VERSION "FL_IC_CANFD"

NS_ :

BS_:

BU_: AVAS BBCM CMSM DVR EAMP EPC FLZCU ICC PCL PLG SBOX SCU

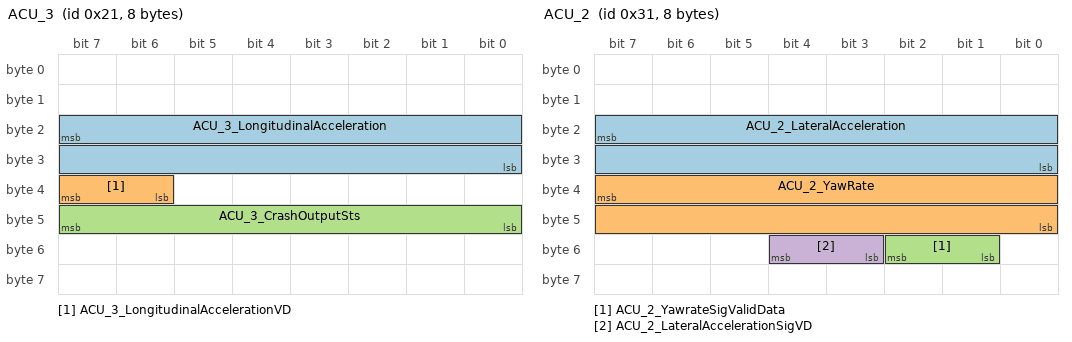
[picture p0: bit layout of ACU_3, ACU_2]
BO_ 33 ACU_3: 8 FLZCU
 SG_ ACU_3_LongitudinalAcceleration : 23|16@0+ (0.001,-2) [-2|2] "g"  ICC
 SG_ ACU_3_LongitudinalAccelerationVD : 39|2@0+ (1,0) [0|3] ""  ICC
 SG_ ACU_3_CrashOutputSts : 47|8@0+ (1,0) [0|255] ""  ICC

BO_ 49 ACU_2: 8 FLZCU
 SG_ ACU_2_LateralAcceleration : 23|16@0+ (0.001,-2) [-2|2] "g"  ICC
 SG_ ACU_2_YawRate : 39|16@0+ (0.01,-180) [-180|180] "deg/sec"  ICC
 SG_ ACU_2_YawrateSigValidData : 50|2@0+ (1,0) [0|3] ""  ICC
 SG_ ACU_2_LateralAccelerationSigVD : 52|2@0+ (1,0) [0|3] ""  ICC

BO_ 258 BMS_1: 48 FLZCU
 SG_ BMS_1_CRC1 : 7|8@0+ (1,0) [0|255] ""  ICC
 SG_ BMS_1_RollgCntr1 : 11|4@0+ (1,0) [0|14] ""  ICC
 SG_ BMS_1_Resd1 : 15|4@0+ (1,0) [0|15] ""  ICC
 SG_ BMS_PackVoltage : 23|16@0+ (0.1,0) [0|1000] "volt(V)"  ICC
 SG_ BMS_PackCurrent : 39|16@0+ (0.1,-2047) [-2047|2047] "ampere(A)"  ICC
 SG_ BMS_HvBattSts : 51|4@0+ (1,0) [0|15] ""  ICC
 SG_ BMS_SysSelfCheck : 53|2@0+ (1,0) [0|3] ""  ICC
 SG_ BMS_HVBattThermRunaway : 55|2@0+ (1,0) [0|3] ""  ICC
 SG_ BMS_1_CRC2 : 71|8@0+ (1,0) [0|255] ""  ICC
 SG_ BMS_1_RollgCntr2 : 75|4@0+ (1,0) [0|14] ""  ICC
 SG_ BMS_1_Resd2 : 79|4@0+ (1,0) [0|15] ""  ICC
 SG_ BMS_ChargeVoltageReq : 87|14@0+ (0.1,0) [0|1024] "volt(V)"  ICC
 SG_ BMS_ChgCurrReq : 103|14@0+ (0.1,-1024) [-1024|0] "ampere(A)"  ICC
 SG_ BMS_InfraDcUActDc : 119|14@0+ (0.1,0) [0|1024] "volt(V)"  ICC
 SG_ BMS_1_CRC3 : 135|8@0+ (1,0) [0|255] ""  ICC
 SG_ BMS_1_RollgCntr3 : 139|4@0+ (1,0) [0|14] ""  ICC
 SG_ BMS_1_Resd3 : 143|4@0+ (1,0) [0|15] ""  ICC
 SG_ BMS_InfraDcIActDc : 151|14@0+ (0.1,-1024) [-1024|0] "ampere(A)"  ICC
 SG_ BMS_HvBattDynChrgnILim : 167|14@0+ (0.1,-1024) [-1024|0] "ampere(A)"  ICC
 SG_ BMS_HvBattUChrgnLim : 183|14@0+ (0.1,0) [0|1024] "volt(V)"  ICC
 SG_ BMS_1_CRC4 : 199|8@0+ (1,0) [0|255] ""  ICC
 SG_ BMS_1_RollgCntr4 : 203|4@0+ (1,0) [0|14] ""  ICC
 SG_ BMS_1_Resd4 : 207|4@0+ (1,0) [0|15] ""  ICC
 SG_ BMS_ChrgDcIAvl : 215|14@0+ (0.1,-1024) [-1024|0] "ampere(A)"  ICC
 SG_ BMS_DChrgAPlusSt : 217|1@0+ (1,0) [0|1] ""  ICC
 SG_ BMS_Insulation_R : 231|16@0+ (1,0) [0|60000] "kiloohm(kΩ)"  ICC
 SG_ BMS_ChrgDcCnctrDetd : 241|2@0+ (1,0) [0|3] ""  ICC
 SG_ BMS_DCChgMode : 244|3@0+ (1,0) [0|7] ""  ICC
 SG_ BMS_ChrgDcChrgnFltStopReas : 247|3@0+ (1,0) [0|7] ""  ICC
 SG_ BMS_1_CRC5 : 263|8@0+ (1,0) [0|255] ""  ICC
 SG_ BMS_1_RollgCntr5 : 267|4@0+ (1,0) [0|14] ""  ICC
 SG_ BMS_1_Resd5 : 271|4@0+ (1,0) [0|15] ""  ICC
 SG_ BMS_ChgRemTime : 279|11@0+ (1,0) [0|1440] "min"  ICC
 SG_ BMS_ChargeRequest_Mode : 284|4@0+ (1,0) [0|15] ""  ICC
 SG_ BMS_1_StateOfChargeDis : 295|8@0+ (1,0) [0|100] "%"  ICC
 SG_ BMS_StateOfEnergy : 311|16@0+ (0.1,0) [0|999.9] "kWh"  ICC
 SG_ BMS_1_CRC6 : 327|8@0+ (1,0) [0|255] ""  ICC
 SG_ BMS_1_RollgCntr6 : 331|4@0+ (1,0) [0|14] ""  ICC
 SG_ BMS_1_Resd6 : 335|4@0+ (1,0) [0|15] ""  ICC
 SG_ BMS_StateOfHealth : 342|7@0+ (1,0) [0|100] ""  ICC
 SG_ BMS_BlanceState : 343|1@0+ (1,0) [0|1] ""  ICC
 SG_ BMS_IsolationFault : 345|2@0+ (1,0) [0|3] ""  ICC
 SG_ BMS_HVILFault_DC : 346|1@0+ (1,0) [0|1] ""  ICC
 SG_ BMS_HVILFault_FMCU : 347|1@0+ (1,0) [0|1] ""  ICC
 SG_ BMS_HVILFault_RMCU : 348|1@0+ (1,0) [0|1] ""  ICC
 SG_ BMS_SOCDis : 359|14@0+ (0.01,0) [0|100] "%"  ICC
 SG_ BMS_InfraDcIActDcMin : 375|14@0+ (0.1,-1024) [-1024|0] "ampere(A)"  ICC

BO_ 259 EMS_6: 16 FLZCU
 SG_ EMS_EngineSpeed_Actual : 39|16@0+ (0.25,0) [0|16383] "rpm"  ICC

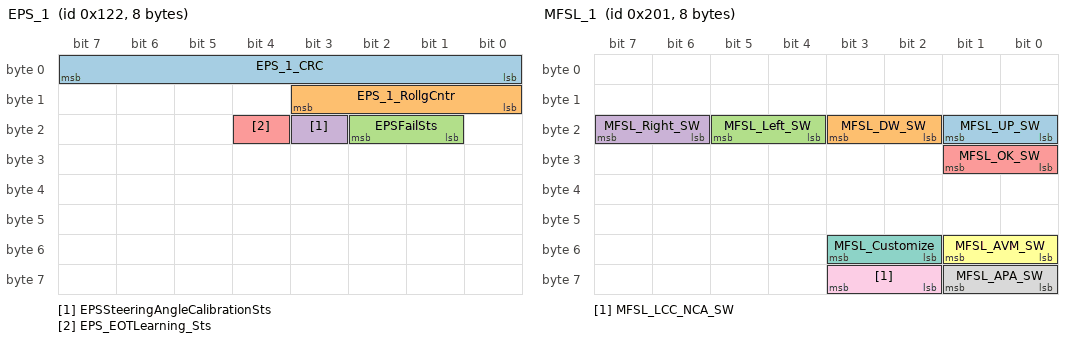
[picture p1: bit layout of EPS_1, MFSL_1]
BO_ 290 EPS_1: 8 FLZCU
 SG_ EPS_1_CRC : 7|8@0+ (1,0) [0|255] ""  ICC
 SG_ EPS_1_RollgCntr : 11|4@0+ (1,0) [0|14] ""  ICC
 SG_ EPSFailSts : 18|2@0+ (1,0) [0|3] ""  ICC
 SG_ EPSSteeringAngleCalibrationSts : 19|1@0+ (1,0) [0|1] ""  ICC
 SG_ EPS_EOTLearning_Sts : 20|1@0+ (1,0) [0|1] ""  ICC

BO_ 513 MFSL_1: 8 FLZCU
 SG_ MFSL_UP_SW : 17|2@0+ (1,0) [0|3] ""  ICC
 SG_ MFSL_DW_SW : 19|2@0+ (1,0) [0|3] ""  ICC
 SG_ MFSL_Left_SW : 21|2@0+ (1,0) [0|3] ""  ICC
 SG_ MFSL_Right_SW : 23|2@0+ (1,0) [0|3] ""  ICC
 SG_ MFSL_OK_SW : 25|2@0+ (1,0) [0|3] ""  ICC
 SG_ MFSL_AVM_SW : 49|2@0+ (1,0) [0|3] ""  ICC
 SG_ MFSL_Customize : 51|2@0+ (1,0) [0|3] ""  ICC
 SG_ MFSL_APA_SW : 57|2@0+ (1,0) [0|3] ""  ICC
 SG_ MFSL_LCC_NCA_SW : 59|2@0+ (1,0) [0|3] ""  ICC

BO_ 514 ADS_HW_202h: 16 FLZCU
 SG_ New_Signal_202_2 : 111|24@0+ (1,0) [0|0] ""  ICC
 SG_ New_Signal_202_1 : 71|16@0+ (1,0) [0|0] ""  ICC
 SG_ ADS_CRC1_202h : 7|8@0+ (1,0) [0|255] ""  ICC
 SG_ ADS_RollgCntr1_202h : 11|4@0+ (1,0) [0|14] ""  ICC
 SG_ ADS_Resd1_202h : 15|4@0+ (1,0) [0|15] ""  ICC
 SG_ ADS_NicaReminderAcoustic_202h : 17|3@0+ (1,0) [0|7] ""  ICC
 SG_ ADS_NicaReminderLEDVisual_202h : 20|3@0+ (1,0) [0|7] ""  ICC
 SG_ ADS_AdsFault_202h : 23|3@0+ (1,0) [0|7] ""  ICC
 SG_ ADS_TakeoverID_202h : 30|16@0+ (1,0) [0|65535] ""  ICC
 SG_ ADS_TakeoverType_202h : 43|4@0+ (1,0) [0|15] ""  ICC
 SG_ ADS_TakeoverLevel_202h : 46|3@0+ (1,0) [0|7] ""  ICC
 SG_ ADS_TORIDCorrespErrorID_202h : 55|16@0+ (1,0) [0|65535] ""  ICC
 SG_ ADS_TakeoverExtended16bit_202h : 87|16@0+ (1,0) [0|65535] ""  ICC
 SG_ ADS_TakeoverExtended8bit_202h : 103|8@0+ (1,0) [0|255] ""  ICC

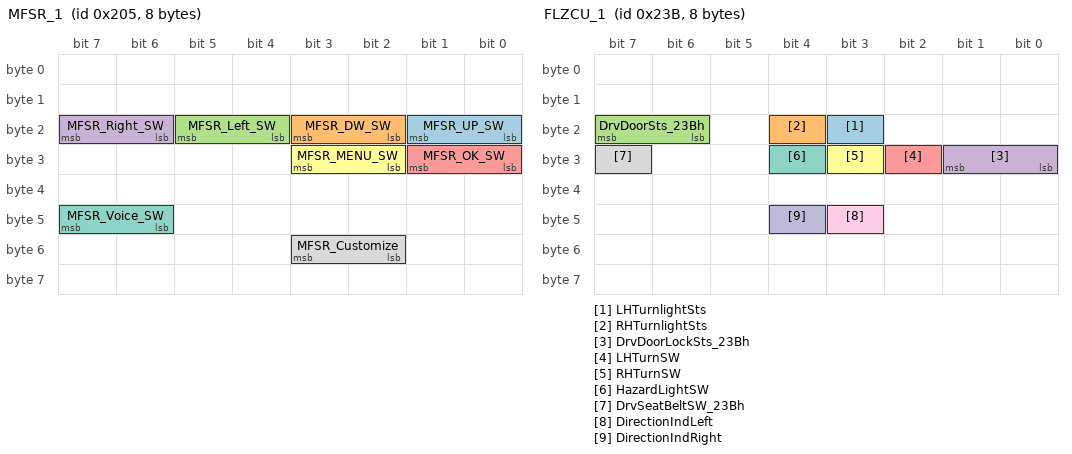
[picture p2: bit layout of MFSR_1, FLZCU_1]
BO_ 517 MFSR_1: 8 FLZCU
 SG_ MFSR_UP_SW : 17|2@0+ (1,0) [0|3] ""  ICC
 SG_ MFSR_DW_SW : 19|2@0+ (1,0) [0|3] ""  ICC
 SG_ MFSR_Left_SW : 21|2@0+ (1,0) [0|3] ""  ICC
 SG_ MFSR_Right_SW : 23|2@0+ (1,0) [0|3] ""  ICC
 SG_ MFSR_OK_SW : 25|2@0+ (1,0) [0|3] ""  ICC
 SG_ MFSR_MENU_SW : 27|2@0+ (1,0) [0|3] ""  ICC
 SG_ MFSR_Voice_SW : 47|2@0+ (1,0) [0|3] ""  ICC
 SG_ MFSR_Customize : 51|2@0+ (1,0) [0|3] ""  ICC

BO_ 524 ADS_6: 8 FLZCU
 SG_ ADS_6_Customize_buttonsFB : 19|3@0+ (1,0) [0|7] ""  ICC

BO_ 571 FLZCU_1: 8 FLZCU
 SG_ LHTurnlightSts : 19|1@0+ (1,0) [0|1] ""  ICC
 SG_ RHTurnlightSts : 20|1@0+ (1,0) [0|1] ""  ICC
 SG_ DrvDoorSts_23Bh : 23|2@0+ (1,0) [0|3] ""  ICC
 SG_ DrvDoorLockSts_23Bh : 25|2@0+ (1,0) [0|3] ""  ICC
 SG_ LHTurnSW : 26|1@0+ (1,0) [0|1] ""  ICC
 SG_ RHTurnSW : 27|1@0+ (1,0) [0|1] ""  ICC
 SG_ HazardLightSW : 28|1@0+ (1,0) [0|1] ""  ICC
 SG_ DrvSeatBeltSW_23Bh : 31|1@0+ (1,0) [0|1] ""  ICC
 SG_ DirectionIndLeft : 43|1@0+ (1,0) [0|1] ""  ICC
 SG_ DirectionIndRight : 44|1@0+ (1,0) [0|1] ""  ICC

BO_ 572 ONEBOX_7: 48 FLZCU
 SG_ ONEBOX_7_TAB_HighTemp : 49|1@0+ (1,0) [0|1] ""  ICC
 SG_ ONEBOX_7_TAB_Active : 51|2@0+ (1,0) [0|3] ""  ICC
 SG_ ONEBOX_7_BSW_Active : 60|2@0+ (1,0) [0|3] ""  ICC
 SG_ ONEBOX_7_iCCO_Active : 109|2@0+ (1,0) [0|3] ""  ICC
 SG_ ONEBOX_7_iCCO_TgtVel : 151|8@0+ (0.1,0) [0|20] ""  ICC

BO_ 587 ONEBOX_4: 48 FLZCU
 SG_ ONEBOX_4_LHFWheelSpeedRPM : 23|16@0+ (0.0625,0) [0|4095.875] "rpm"  ICC
 SG_ ONEBOX_4_RHFWheelSpeedRPM : 39|16@0+ (0.0625,0) [0|4095.875] "rpm"  ICC
 SG_ LHRWheelSpeedRPM : 55|16@0+ (0.0625,0) [0|4095.875] "rpm"  ICC
 SG_ RHRWheelSpeedRPM : 87|16@0+ (0.0625,0) [0|4095.875] "rpm"  ICC
 SG_ LHRPulseCounter : 103|13@0+ (1,0) [0|8191] "pulse"  ICC
 SG_ LHRPulseCounterFailSts : 106|1@0+ (1,0) [0|1] ""  ICC
 SG_ RHRPulseCounter : 119|13@0+ (1,0) [0|8191] "pulse"  ICC
 SG_ RHRPulseCounterFailSts : 122|1@0+ (1,0) [0|1] ""  ICC
 SG_ RHFPulseCounter : 151|13@0+ (1,0) [0|8191] "pulse"  ICC
 SG_ RHFPulseCounterFailSts : 154|1@0+ (1,0) [0|1] ""  ICC
 SG_ LHFPulseCounter : 167|13@0+ (1,0) [0|8191] "pulse"  ICC
 SG_ LHFPulseCounterFailSts : 170|1@0+ (1,0) [0|1] ""  ICC
 SG_ LHFWheelDriveDirection : 187|3@0+ (1,0) [0|7] ""  ICC
 SG_ RHFWheelDriveDirection : 219|3@0+ (1,0) [0|7] ""  ICC
 SG_ LHRWheelDriveDirection : 235|3@0+ (1,0) [0|7] ""  ICC
 SG_ RHRWheelDriveDirection : 251|3@0+ (1,0) [0|7] ""  ICC
 SG_ IPB_SandABSAvl_24Bh : 277|2@0+ (1,0) [0|3] ""  ICC
 SG_ IPB_SandABSSwSts_24Bh : 279|2@0+ (1,0) [0|3] ""  ICC

BO_ 612 EPB_R_1: 24 FLZCU
 SG_ New_Signal_264_5 : 40|17@0+ (1,0) [0|0] ""  ICC
 SG_ New_Signal_264_4 : 47|6@0+ (1,0) [0|0] ""  ICC
 SG_ New_Signal_264_3 : 24|5@0+ (1,0) [0|0] ""  ICC
 SG_ New_Signal_264_2 : 31|6@0+ (1,0) [0|0] ""  ICC
 SG_ New_Signal_264_1 : 15|4@0+ (1,0) [0|0] ""  ICC
 SG_ CRC1_264h : 7|8@0+ (1,0) [0|255] ""  ICC
 SG_ RollgCntr1_264h : 11|4@0+ (1,0) [0|14] ""  ICC
 SG_ EPBAUTO_Status_264h : 16|1@0+ (1,0) [0|1] ""  ICC
 SG_ FltLamp_264h : 18|2@0+ (1,0) [0|3] ""  ICC
 SG_ ParkLamp_264h : 20|2@0+ (1,0) [0|3] ""  ICC
 SG_ ActrSt_264h : 23|3@0+ (1,0) [0|7] ""  ICC
 SG_ RWUSt_264h : 25|1@0+ (1,0) [0|1] ""  ICC
 SG_ TextDisp_264h : 35|4@0+ (1,0) [0|15] ""  ICC
 SG_ IPB_EPBErrorStatus : 41|1@0+ (1,0) [0|1] ""  ICC

BO_ 632 EMS_4: 8 FLZCU
 SG_ EngineCoolantTemperature : 23|8@0+ (0.75,-48) [-48|142.5] "°C"  ICC

BO_ 638 FRZCU_9: 16 FLZCU
 SG_ FRZCU_HoodSts : 45|2@0+ (1,0) [0|3] ""  ICC
 SG_ FRZCU_AuthenResult : 48|1@0+ (1,0) [0|1] ""  ICC
 SG_ FRZCU_TrunkSts : 53|2@0+ (1,0) [0|3] ""  ICC
 SG_ DrvHandleSwitchSts_27Eh : 57|2@0+ (1,0) [0|3] ""  ICC
 SG_ PassHandleSwitchSts_27Eh : 59|2@0+ (1,0) [0|3] ""  ICC
 SG_ PassRearHandleSwitchSts_27Eh : 61|2@0+ (1,0) [0|3] ""  ICC
 SG_ DrvRearHandleSwitchSts_27Eh : 63|2@0+ (1,0) [0|3] ""  ICC
 SG_ SeatLength_target_Passenger : 87|4@0+ (1,0) [0|15] ""  ICC
 SG_ FRZCU_TrunkLockSts : 89|2@0+ (1,0) [0|3] ""  ICC
 SG_ SeatBackrest_target_Passenger : 95|5@0+ (1,0) [0|31] ""  ICC
 SG_ FRZCU_GloveboxSW : 98|1@0+ (1,0) [0|1] ""  ICC
 SG_ FrontBackSpeedAdj_Cmd : 101|3@0+ (1,0) [0|7] ""  ICC
 SG_ FRZCU_HoodLockSts : 103|2@0+ (1,0) [0|3] ""  ICC
 SG_ FRZCU_PELockInKeyWarning : 105|1@0+ (1,0) [0|1] ""  ICC
 SG_ PassRearReleaseLockSts_27Eh : 108|3@0+ (1,0) [0|7] ""  ICC
 SG_ PassReleaseLockSts_27Eh : 111|3@0+ (1,0) [0|7] ""  ICC
 SG_ FRZCU_OTAPwrDwnReqFb : 113|2@0+ (1,0) [0|3] ""  ICC
 SG_ FRZCU_KeylessWarning : 116|1@0+ (1,0) [0|1] ""  ICC
 SG_ FRZCU_PowerOFFWarning : 118|1@0+ (1,0) [0|1] ""  ICC
 SG_ FRZCU_OTAPwrOnReqFb : 127|2@0+ (1,0) [0|3] ""  ICC

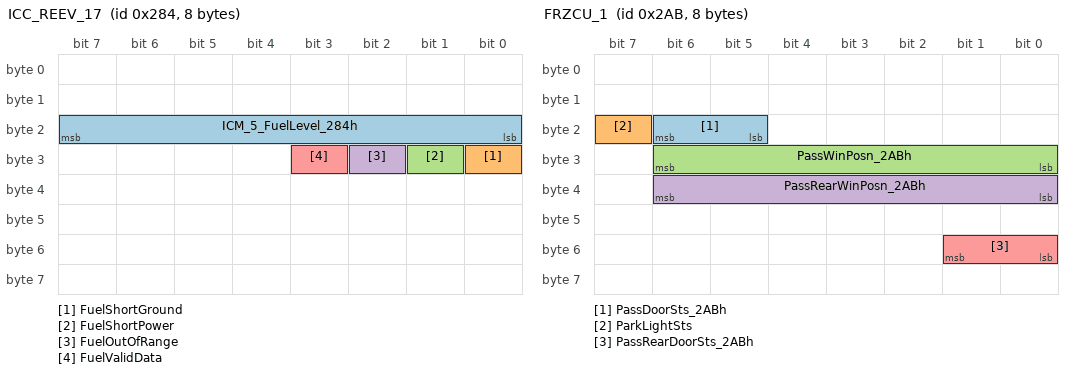
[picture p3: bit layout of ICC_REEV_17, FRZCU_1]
BO_ 644 ICC_REEV_17: 8 ICC
 SG_ ICM_5_FuelLevel_284h : 23|8@0+ (1,0) [0|100] "%"  FLZCU
 SG_ FuelShortGround : 24|1@0+ (1,0) [0|1] ""  FLZCU
 SG_ FuelShortPower : 25|1@0+ (1,0) [0|1] ""  FLZCU
 SG_ FuelOutOfRange : 26|1@0+ (1,0) [0|1] ""  FLZCU
 SG_ FuelValidData : 27|1@0+ (1,0) [0|1] ""  FLZCU

BO_ 683 FRZCU_1: 8 FLZCU
 SG_ PassDoorSts_2ABh : 22|2@0+ (1,0) [0|3] ""  ICC
 SG_ ParkLightSts : 23|1@0+ (1,0) [0|1] ""  ICC
 SG_ PassWinPosn_2ABh : 30|7@0+ (1,0) [0|100] "%"  ICC
 SG_ PassRearWinPosn_2ABh : 38|7@0+ (1,0) [0|100] "%"  ICC
 SG_ PassRearDoorSts_2ABh : 49|2@0+ (1,0) [0|3] ""  ICC

BO_ 699 RZCU_2: 8 FLZCU
 SG_ DrvRearDoorSts_2BBh : 21|2@0+ (1,0) [0|3] ""  ICC

BO_ 769 ADS_HW_301h: 48 FLZCU
 SG_ ADS_LccNcaFunctionStatus_301h : 19|6@0+ (1,0) [0|63] ""  ICC
 SG_ ADS_AccFunctionStatus_301h : 23|4@0+ (1,0) [0|15] ""  ICC
 SG_ ADS_AvpFunctionStatus_301h : 25|5@0+ (1,0) [0|31] ""  ICC
 SG_ ADS_AdsFucntionNotActive_301h : 29|4@0+ (1,0) [0|15] ""  ICC
 SG_ ADS_SpeedSetByDriver_301h : 36|9@0+ (1,0) [0|511] "kph"  ICC
 SG_ ADS_SpeedLimitValue_301h : 43|8@0+ (1,0) [0|255] "kph"  ICC
 SG_ ADS_OneTouchSpeedAdjustment_301h : 48|3@0+ (1,0) [0|7] ""  ICC
 SG_ ADS_SpeedAutoFollow_301h : 51|3@0+ (1,0) [0|7] ""  ICC
 SG_ ADS_HODReminder_301h : 58|3@0+ (1,0) [0|7] ""  ICC
 SG_ ADS_CalibState_301h : 61|3@0+ (1,0) [0|7] ""  ICC
 SG_ ADS_FcwFault_301h : 80|2@0+ (1,0) [0|3] ""  ICC
 SG_ ADS_FcwWaning_301h : 83|3@0+ (1,0) [0|7] ""  ICC
 SG_ ADS_DMSReminder_301h : 87|4@0+ (1,0) [0|15] ""  ICC
 SG_ ADS_AebObjType_301h : 88|3@0+ (1,0) [0|7] ""  ICC
 SG_ ADS_AebFault_301h : 90|2@0+ (1,0) [0|3] ""  ICC
 SG_ ADS_AebWaning_301h : 94|4@0+ (1,0) [0|15] ""  ICC
 SG_ ADS_RcwWarning_301h : 96|3@0+ (1,0) [0|7] ""  ICC
 SG_ ADS_RaebFault_301h : 98|2@0+ (1,0) [0|3] ""  ICC
 SG_ ADS_RaebWarning_301h : 101|3@0+ (1,0) [0|7] ""  ICC
 SG_ ADS_FctaRightWarning_301h : 104|3@0+ (1,0) [0|7] ""  ICC
 SG_ ADS_FctaLeftWarning_301h : 107|3@0+ (1,0) [0|7] ""  ICC
 SG_ ADS_RcwFault_301h : 109|2@0+ (1,0) [0|3] ""  ICC
 SG_ ADS_FctbRightWarning_301h : 114|3@0+ (1,0) [0|7] ""  ICC
 SG_ ADS_FctbLeftWarning_301h : 117|3@0+ (1,0) [0|7] ""  ICC
 SG_ ADS_RctaFault_301h : 121|2@0+ (1,0) [0|3] ""  ICC
 SG_ ADS_RctaRightWarning_301h : 124|3@0+ (1,0) [0|7] ""  ICC
 SG_ ADS_RctaLeftWarning_301h : 127|3@0+ (1,0) [0|7] ""  ICC
 SG_ ADS_LdwWarning_301h : 145|3@0+ (1,0) [0|7] ""  ICC
 SG_ ADS_RctbRightWarning_301h : 148|3@0+ (1,0) [0|7] ""  ICC
 SG_ ADS_RctbLeftWarning_301h : 151|3@0+ (1,0) [0|7] ""  ICC
 SG_ ADS_LkaFault_301h : 152|2@0+ (1,0) [0|3] ""  ICC
 SG_ ADS_LKAWarning_301h : 155|3@0+ (1,0) [0|7] ""  ICC
 SG_ ADS_LdwFault_301h : 158|3@0+ (1,0) [0|7] ""  ICC
 SG_ ADS_BsdFault_301h : 160|2@0+ (1,0) [0|3] ""  ICC
 SG_ ADS_RightMirrWarningCmd_301h : 163|3@0+ (1,0) [0|7] ""  ICC
 SG_ ADS_LeftMirrWarningCmd_301h : 166|3@0+ (1,0) [0|7] ""  ICC
 SG_ ADS_RiFrntDoorWarningCmd_301h : 168|3@0+ (1,0) [0|7] ""  ICC
 SG_ ADS_LeReDoorWarningCmd_301h : 171|3@0+ (1,0) [0|7] ""  ICC
 SG_ ADS_LeFrntDoorWarningCmd_301h : 174|3@0+ (1,0) [0|7] ""  ICC
 SG_ ADS_SpeedLimitWarning_301h : 176|3@0+ (1,0) [0|7] ""  ICC
 SG_ ADS_DowFault_301h : 178|2@0+ (1,0) [0|3] ""  ICC
 SG_ ADS_RiReDoorWarningCmd_301h : 181|3@0+ (1,0) [0|7] ""  ICC
 SG_ ADS_ElkaFault_301h : 185|2@0+ (1,0) [0|3] ""  ICC
 SG_ ADS_TlaFault_301h : 187|2@0+ (1,0) [0|3] ""  ICC
 SG_ ADS_TsrFault_301h : 189|2@0+ (1,0) [0|3] ""  ICC
 SG_ ADS_AbsoultwSpeedLimit_301h : 215|16@0+ (1,0) [0|65535] "kph"  ICC
 SG_ ADS_ElkaWarning_301h : 228|3@0+ (1,0) [0|7] ""  ICC
 SG_ ADS_TlaWarning_301h : 231|3@0+ (1,0) [0|7] ""  ICC

BO_ 770 ADS_HW_302h: 64 FLZCU
 SG_ ADS_RPAOnlineOrNot_302h : 23|8@0+ (1,0) [0|255] ""  ICC
 SG_ ADS_VehParkMod_302h : 25|3@0+ (1,0) [0|7] ""  ICC
 SG_ ADS_SeldParkID_302h : 29|4@0+ (1,0) [0|10] ""  ICC
 SG_ ADS_RpaParkAuthn_302h : 31|2@0+ (1,0) [0|3] ""  ICC
 SG_ ADS_ParkProgs_302h : 32|7@0+ (1,0) [0|100] ""  ICC
 SG_ ADS_ParkDirCfm_302h : 36|4@0+ (1,0) [0|15] ""  ICC
 SG_ ADS_RemParkPatSel_302h : 38|2@0+ (1,0) [0|3] ""  ICC
 SG_ ADS_ParkRmngDst_302h : 41|9@0+ (0.1,0) [0|50] ""  ICC
 SG_ ADS_ObstclDst_302h : 48|5@0+ (1,0) [0|31] ""  ICC
 SG_ ADS_AutEve_302h : 59|4@0+ (1,0) [0|15] ""  ICC
 SG_ ADS_parkInterruptDuration_302h : 87|8@0+ (1,0) [0|255] ""  ICC
 SG_ ADS_ParkOutDir_ParaLe_302h : 88|1@0+ (1,0) [0|1] ""  ICC
 SG_ ADS_ParkStMac_302h : 93|5@0+ (1,0) [0|31] ""  ICC
 SG_ APA_ResuAvl_302h : 95|2@0+ (1,0) [0|3] ""  ICC
 SG_ APA_RPAFctUnavlMsg_1_302h : 96|1@0+ (1,0) [0|1] ""  ICC
 SG_ ADS_ParkOutDir_PerpBack_302h : 97|1@0+ (1,0) [0|1] ""  ICC
 SG_ ADS_ParkOutDir_PerpRiBack_302h : 98|1@0+ (1,0) [0|1] ""  ICC
 SG_ ADS_ParkOutDir_PerpLeBack_302h : 99|1@0+ (1,0) [0|1] ""  ICC
 SG_ ADS_ParkOutDir_PerpRiFwd_302h : 100|1@0+ (1,0) [0|1] ""  ICC
 SG_ ADS_ParkOutDir_PerpLeFwd_302h : 101|1@0+ (1,0) [0|1] ""  ICC
 SG_ ADS_ParkOutDir_PerpFwd_302h : 102|1@0+ (1,0) [0|1] ""  ICC
 SG_ ADS_ParkOutDir_ParaRi_302h : 103|1@0+ (1,0) [0|1] ""  ICC
 SG_ APA_RPAFctUnavlMsg_9_302h : 104|1@0+ (1,0) [0|1] ""  ICC
 SG_ APA_RPAFctUnavlMsg_8_302h : 105|1@0+ (1,0) [0|1] ""  ICC
 SG_ APA_RPAFctUnavlMsg_7_302h : 106|1@0+ (1,0) [0|1] ""  ICC
 SG_ APA_RPAFctUnavlMsg_6_302h : 107|1@0+ (1,0) [0|1] ""  ICC
 SG_ APA_RPAFctUnavlMsg_5_302h : 108|1@0+ (1,0) [0|1] ""  ICC
 SG_ APA_RPAFctUnavlMsg_4_302h : 109|1@0+ (1,0) [0|1] ""  ICC
 SG_ APA_RPAFctUnavlMsg_3_302h : 110|1@0+ (1,0) [0|1] ""  ICC
 SG_ APA_RPAFctUnavlMsg_2_302h : 111|1@0+ (1,0) [0|1] ""  ICC
 SG_ APA_RPAFctUnavlMsg_17_302h : 112|1@0+ (1,0) [0|1] ""  ICC
 SG_ APA_RPAFctUnavlMsg_16_302h : 113|1@0+ (1,0) [0|1] ""  ICC
 SG_ APA_RPAFctUnavlMsg_15_302h : 114|1@0+ (1,0) [0|1] ""  ICC
 SG_ APA_RPAFctUnavlMsg_14_302h : 115|1@0+ (1,0) [0|1] ""  ICC
 SG_ APA_RPAFctUnavlMsg_13_302h : 116|1@0+ (1,0) [0|1] ""  ICC
 SG_ APA_RPAFctUnavlMsg_12_302h : 117|1@0+ (1,0) [0|1] ""  ICC
 SG_ APA_RPAFctUnavlMsg_11_302h : 118|1@0+ (1,0) [0|1] ""  ICC
 SG_ APA_RPAFctUnavlMsg_10_302h : 119|1@0+ (1,0) [0|1] ""  ICC
 SG_ APA_RPAFctUnavlMsg_25_302h : 120|1@0+ (1,0) [0|1] ""  ICC
 SG_ APA_RPAFctUnavlMsg_24_302h : 121|1@0+ (1,0) [0|1] ""  ICC
 SG_ APA_RPAFctUnavlMsg_23_302h : 122|1@0+ (1,0) [0|1] ""  ICC
 SG_ APA_RPAFctUnavlMsg_22_302h : 123|1@0+ (1,0) [0|1] ""  ICC
 SG_ APA_RPAFctUnavlMsg_21_302h : 124|1@0+ (1,0) [0|1] ""  ICC
 SG_ APA_RPAFctUnavlMsg_20_302h : 125|1@0+ (1,0) [0|1] ""  ICC
 SG_ APA_RPAFctUnavlMsg_19_302h : 126|1@0+ (1,0) [0|1] ""  ICC
 SG_ APA_RPAFctUnavlMsg_18_302h : 127|1@0+ (1,0) [0|1] ""  ICC
 SG_ APA_RPACnclMsg_8_302h : 144|1@0+ (1,0) [0|1] ""  ICC
 SG_ APA_RPACnclMsg_7_302h : 145|1@0+ (1,0) [0|1] ""  ICC
 SG_ APA_RPACnclMsg_6_302h : 146|1@0+ (1,0) [0|1] ""  ICC
 SG_ APA_RPACnclMsg_5_302h : 147|1@0+ (1,0) [0|1] ""  ICC
 SG_ APA_RPACnclMsg_4_302h : 148|1@0+ (1,0) [0|1] ""  ICC
 SG_ APA_RPACnclMsg_3 : 149|1@0+ (1,0) [0|1] ""  ICC
 SG_ APA_RPACnclMsg_2_302h : 150|1@0+ (1,0) [0|1] ""  ICC
 SG_ APA_RPACnclMsg_1_302h : 151|1@0+ (1,0) [0|1] ""  ICC
 SG_ APA_RPACnclMsg_16_302h : 152|1@0+ (1,0) [0|1] ""  ICC
 SG_ APA_RPACnclMsg_15_302h : 153|1@0+ (1,0) [0|1] ""  ICC
 SG_ APA_RPACnclMsg_14_302h : 154|1@0+ (1,0) [0|1] ""  ICC
 SG_ APA_RPACnclMsg_13_302h : 155|1@0+ (1,0) [0|1] ""  ICC
 SG_ APA_RPACnclMsg_12_302h : 156|1@0+ (1,0) [0|1] ""  ICC
 SG_ APA_RPACnclMsg_11_302h : 157|1@0+ (1,0) [0|1] ""  ICC
 SG_ APA_RPACnclMsg_10_302h : 158|1@0+ (1,0) [0|1] ""  ICC
 SG_ APA_RPACnclMsg_9_302h : 159|1@0+ (1,0) [0|1] ""  ICC
 SG_ APA_RPAPauseMsg_4_302h : 160|1@0+ (1,0) [0|1] ""  ICC
 SG_ APA_RPAPauseMsg_3_302h : 161|1@0+ (1,0) [0|1] ""  ICC
 SG_ APA_RPAPauseMsg_2_302h : 162|1@0+ (1,0) [0|1] ""  ICC
 SG_ APA_RPAPauseMsg_1_302h : 163|1@0+ (1,0) [0|1] ""  ICC
 SG_ APA_RPACnclMsg_20_302h : 164|1@0+ (1,0) [0|1] ""  ICC
 SG_ APA_RPACnclMsg_19_302h : 165|1@0+ (1,0) [0|1] ""  ICC
 SG_ APA_RPACnclMsg_18_302h : 166|1@0+ (1,0) [0|1] ""  ICC
 SG_ APA_RPACnclMsg_17_302h : 167|1@0+ (1,0) [0|1] ""  ICC
 SG_ ADS_ParkPosn1_ID_302h : 169|4@0+ (1,0) [0|15] ""  ICC
 SG_ APA_RPAPauseMsg_10_302h : 170|1@0+ (1,0) [0|1] ""  ICC
 SG_ APA_RPAPauseMsg_9_302h : 171|1@0+ (1,0) [0|1] ""  ICC
 SG_ APA_RPAPauseMsg_8_302h : 172|1@0+ (1,0) [0|1] ""  ICC
 SG_ APA_RPAPauseMsg_7_302h : 173|1@0+ (1,0) [0|1] ""  ICC
 SG_ APA_RPAPauseMsg_6_302h : 174|1@0+ (1,0) [0|1] ""  ICC
 SG_ APA_RPAPauseMsg_5_302h : 175|1@0+ (1,0) [0|1] ""  ICC
 SG_ ADS_ParkRelPos1_x1_302h : 177|10@0+ (0.1,-50) [-50|50] ""  ICC
 SG_ ADS_MnvrOrintChng2_302h : 179|2@0+ (1,0) [0|3] ""  ICC
 SG_ ADS_MnvrOrintChng1_302h : 181|2@0+ (1,0) [0|3] ""  ICC
 SG_ ADS_ParkRelPos1_y1_302h : 215|10@0+ (0.1,-50) [-50|50] ""  ICC
 SG_ ADS_ParkRelPos1_x2_302h : 221|10@0+ (0.1,-50) [-50|50] ""  ICC
 SG_ ADS_ParkRelPos1_y2_302h : 227|10@0+ (0.1,-50) [-50|50] ""  ICC
 SG_ ADS_ParkRelPos1_x3_302h : 233|10@0+ (0.1,-50) [-50|50] ""  ICC
 SG_ ADS_TcsActvSts_302h : 248|1@0+ (1,0) [0|1] ""  ICC
 SG_ ADS_VdcActvSts_302h : 249|1@0+ (1,0) [0|1] ""  ICC
 SG_ ADS_ParkChkSrc_Posn1_302h : 252|3@0+ (1,0) [0|7] ""  ICC
 SG_ ADS_TarParkSt_Posn1_302h : 255|3@0+ (1,0) [0|7] ""  ICC
 SG_ ADS_ParkRelPos1_y3_302h : 279|10@0+ (0.1,-50) [-50|50] ""  ICC
 SG_ ADS_ParkRelPos1_x4_302h : 285|10@0+ (0.1,-50) [-50|50] ""  ICC
 SG_ ADS_ParkRelPos1_y4_302h : 291|10@0+ (0.1,-50) [-50|50] ""  ICC
 SG_ ADS_ParkPosn2_ID_302h : 297|4@0+ (1,0) [0|15] ""  ICC
 SG_ ADS_ParkRelPos2_x1_302h : 309|10@0+ (0.1,-50) [-50|50] ""  ICC
 SG_ ADS_ParkRelPos2_y1_302h : 343|10@0+ (0.1,-50) [-50|50] ""  ICC
 SG_ ADS_ParkRelPos2_x2_302h : 349|10@0+ (0.1,-50) [-50|50] ""  ICC
 SG_ ADS_ParkRelPos2_y2_302h : 355|10@0+ (0.1,-50) [-50|50] ""  ICC
 SG_ ADS_ParkRelPos2_x3_302h : 361|10@0+ (0.1,-50) [-50|50] ""  ICC
 SG_ ADS_ParkChkSrc_Posn2_302h : 380|3@0+ (1,0) [0|7] ""  ICC
 SG_ ADS_TarParkSt_Posn2_302h : 383|3@0+ (1,0) [0|7] ""  ICC
 SG_ ADS_ParkRelPos2_y3_302h : 407|10@0+ (0.1,-50) [-50|50] ""  ICC
 SG_ ADS_ParkRelPos2_x4_302h : 413|10@0+ (0.1,-50) [-50|50] ""  ICC
 SG_ ADS_ParkRelPos2_y4_302h : 419|10@0+ (0.1,-50) [-50|50] ""  ICC

BO_ 771 FLZCU_303h: 16 FLZCU
 SG_ TimeGapAdjustment_33Dh : 26|3@0+ (1,0) [0|7] ""  ICC

BO_ 777 ISGF_2: 8 FLZCU
 SG_ ISGF_ErrLvl : 20|4@0+ (1,0) [0|15] ""  ICC

BO_ 783 ADS_COM_1: 8 FLZCU
 SG_ ADCC_SysReadySts : 37|3@0+ (1,0) [0|7] ""  ICC

BO_ 787 FRZCU_14: 16 FLZCU
 SG_ PassSitPosnSts_313h : 22|2@0+ (1,0) [0|3] ""  ICC
 SG_ ChrgHoodSts : 23|1@0+ (1,0) [0|1] ""  ICC

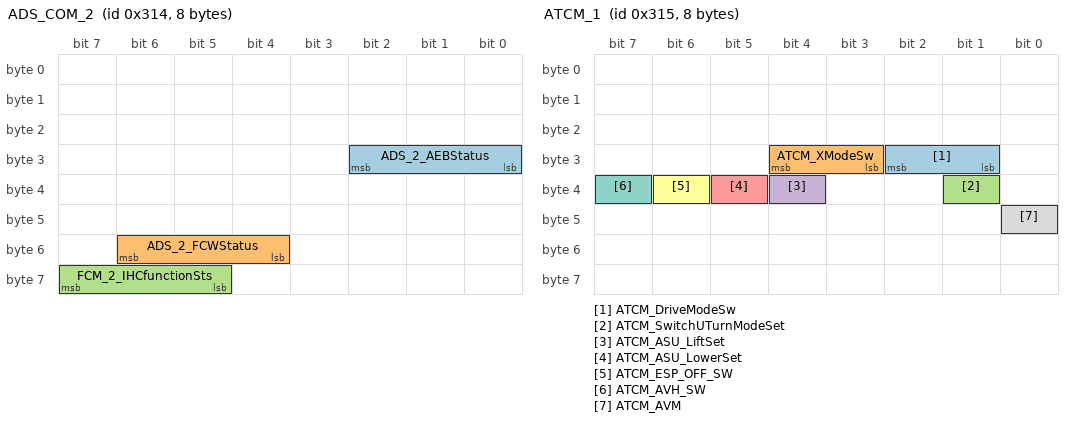
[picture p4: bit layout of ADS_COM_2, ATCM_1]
BO_ 788 ADS_COM_2: 8 FLZCU
 SG_ ADS_2_AEBStatus : 26|3@0+ (1,0) [0|7] ""  ICC
 SG_ ADS_2_FCWStatus : 54|3@0+ (1,0) [0|7] ""  ICC
 SG_ FCM_2_IHCfunctionSts : 63|3@0+ (1,0) [0|7] ""  ICC

BO_ 789 ATCM_1: 8 FLZCU
 SG_ ATCM_DriveModeSw : 26|2@0+ (1,0) [0|3] ""  ICC
 SG_ ATCM_XModeSw : 28|2@0+ (1,0) [0|3] ""  ICC
 SG_ ATCM_SwitchUTurnModeSet : 33|1@0+ (1,0) [0|1] ""  ICC
 SG_ ATCM_ASU_LiftSet : 36|1@0+ (1,0) [0|1] ""  ICC
 SG_ ATCM_ASU_LowerSet : 37|1@0+ (1,0) [0|1] ""  ICC
 SG_ ATCM_ESP_OFF_SW : 38|1@0+ (1,0) [0|1] ""  ICC
 SG_ ATCM_AVH_SW : 39|1@0+ (1,0) [0|1] ""  ICC
 SG_ ATCM_AVM : 40|1@0+ (1,0) [0|1] ""  ICC

BO_ 794 ADS_COM_3: 24 FLZCU
 SG_ ADS_3_ICATextinfo : 19|4@0+ (1,0) [0|15] ""  ICC
 SG_ ADS_3_ICAStatus : 23|3@0+ (1,0) [0|7] ""  ICC
 SG_ ADS_3_DriverHandsoffWarning : 27|3@0+ (1,0) [0|7] ""  ICC
 SG_ ADS_3_ACCSts : 31|4@0+ (1,0) [0|15] ""  ICC
 SG_ ADS_3_LKSSts : 34|3@0+ (1,0) [0|7] ""  ICC
 SG_ ADS_3_LKSMod : 36|2@0+ (1,0) [0|3] ""  ICC
 SG_ ADS_3_LKSRightTrackingSt : 42|2@0+ (1,0) [0|3] ""  ICC
 SG_ ADS_3_LKSLeftTrackingSt : 44|2@0+ (1,0) [0|3] ""  ICC
 SG_ ADS_3_ELKSts : 47|3@0+ (1,0) [0|7] ""  ICC
 SG_ ADS_3_ELKRightActiveSt : 53|2@0+ (1,0) [0|3] ""  ICC
 SG_ ADS_3_ELKLeftActiveSt : 55|2@0+ (1,0) [0|3] ""  ICC
 SG_ ADS_HNOPSts : 83|4@0+ (1,0) [0|15] ""  ICC

BO_ 811 BMS_6: 16 FLZCU
 SG_ BMS_Chg_Sts_32Bh : 87|4@0+ (1,0) [0|15] ""  ICC

BO_ 819 ADS_4: 48 FLZCU
 SG_ ADS_4_CRC1 : 7|8@0+ (1,0) [0|255] ""  ICC
 SG_ ADS_4_RollgCntr1 : 11|4@0+ (1,0) [0|14] ""  ICC
 SG_ ADS_4_Resd1 : 15|4@0+ (1,0) [0|15] ""  ICC
 SG_ ADS_4_AEBReqType : 16|3@0+ (1,0) [0|7] ""  ICC
 SG_ ADS_4_AEBStatus : 19|3@0+ (1,0) [0|7] ""  ICC
 SG_ ADS_4_ACCSts : 23|4@0+ (1,0) [0|15] ""  ICC
 SG_ ADS_4_TimeGapSet : 26|3@0+ (1,0) [0|7] ""  ICC
 SG_ ADS_4_FcwMode : 29|3@0+ (1,0) [0|7] ""  ICC
 SG_ ADS_4_SetSpd : 39|8@0+ (1,0) [0|255] "kph"  ICC
 SG_ ADS_4_DAIStatus : 41|2@0+ (1,0) [0|3] ""  ICC
 SG_ ADS_4_ACCTextMessage : 45|4@0+ (1,0) [0|15] ""  ICC
 SG_ ADS_4_LongiTakeOverReq : 46|1@0+ (1,0) [0|1] ""  ICC
 SG_ ADS_4_SetSpdUnit : 47|1@0+ (1,0) [0|1] ""  ICC
 SG_ ADS_4_GoNotifier : 50|3@0+ (1,0) [0|7] ""  ICC
 SG_ ADS_4_DAISts : 52|2@0+ (1,0) [0|3] ""  ICC
 SG_ ADS_4_Radar_textinfo : 55|3@0+ (1,0) [0|7] ""  ICC
 SG_ ADS_4_SCF_PopoverReq : 57|1@0+ (1,0) [0|1] ""  ICC
 SG_ ADS_4_DrvrCfmSCFDispFb : 58|1@0+ (1,0) [0|1] ""  ICC
 SG_ ADS_4_SCF_SpdLimUnit : 60|2@0+ (1,0) [0|3] ""  ICC
 SG_ ADS_4_SCF_SpdLimSts : 63|3@0+ (1,0) [0|7] ""  ICC
 SG_ ADS_4_CRC2 : 71|8@0+ (1,0) [0|255] ""  ICC
 SG_ ADS_4_RollgCntr2 : 75|4@0+ (1,0) [0|14] ""  ICC
 SG_ ADS_4_Resd2 : 79|4@0+ (1,0) [0|15] ""  ICC
 SG_ ADS_4_ACCObjTyp : 83|4@0+ (1,0) [0|15] ""  ICC
 SG_ ADS_4_FrntFarObjTyp : 87|4@0+ (1,0) [0|15] ""  ICC
 SG_ ADS_4_ACCObjLgtDstX : 95|8@0+ (0.5,0) [0|127] "m"  ICC
 SG_ ADS_4_ACCObjHozDstY : 103|10@0+ (0.1,-50) [-50|50] "m"  ICC
 SG_ ADS_4_FrntFarObjHozDstY : 105|10@0+ (0.1,-50) [-50|50] "m"  ICC
 SG_ ADS_4_FrntFarObjID : 107|1@0+ (1,0) [0|1] ""  ICC
 SG_ ADS_4_Resd : 108|1@0+ (1,0) [0|1] ""  ICC
 SG_ ADS_4_ACCObjID : 109|1@0+ (1,0) [0|1] ""  ICC
 SG_ ADS_4_FrntFarObjLgtDstX : 127|8@0+ (0.5,0) [0|127] "m"  ICC
 SG_ ADS_4_CRC3 : 135|8@0+ (1,0) [0|255] ""  ICC
 SG_ ADS_4_RollgCntr3 : 139|4@0+ (1,0) [0|14] ""  ICC
 SG_ ADS_4_Resd3 : 143|4@0+ (1,0) [0|15] ""  ICC
 SG_ ADS_4_LeObjHozDstY : 145|10@0+ (0.1,-50) [-50|50] "m"  ICC
 SG_ ADS_4_Resd_1 : 146|1@0+ (1,0) [0|1] ""  ICC
 SG_ ADS_4_LeObjID : 147|1@0+ (1,0) [0|1] ""  ICC
 SG_ ADS_4_LeObjTyp : 151|4@0+ (1,0) [0|15] ""  ICC
 SG_ ADS_4_LeObjLgtDstX : 167|8@0+ (0.5,0) [0|127] "m"  ICC
 SG_ ADS_4_RiObjHozDstY : 169|10@0+ (0.1,-50) [-50|50] "m"  ICC
 SG_ ADS_4_RiObjID : 171|1@0+ (1,0) [0|1] ""  ICC
 SG_ ADS_4_RiObjTyp : 175|4@0+ (1,0) [0|15] ""  ICC
 SG_ ADS_4_RiObjLgtDstX : 191|8@0+ (0.5,0) [0|127] "m"  ICC
 SG_ ADS_4_CRC4 : 199|8@0+ (1,0) [0|255] ""  ICC
 SG_ ADS_4_RollgCntr4 : 203|4@0+ (1,0) [0|14] ""  ICC
 SG_ ADS_4_Resd4 : 207|4@0+ (1,0) [0|15] ""  ICC
 SG_ ADS_4_SCFSwtSet : 210|2@0+ (1,0) [0|3] ""  ICC
 SG_ ADS_4_AEBSettingSt : 212|2@0+ (1,0) [0|3] ""  ICC
 SG_ ADS_4_FCWSettingSt : 215|3@0+ (1,0) [0|7] ""  ICC
 SG_ NOPTextinfo_333h : 219|4@0+ (1,0) [0|15] ""  ICC
 SG_ ADS_4_CruiseAccelerateSts : 221|2@0+ (1,0) [0|3] ""  ICC
 SG_ ADS_4_DAISwtSet : 223|2@0+ (1,0) [0|3] ""  ICC
 SG_ FCM_FRM_DAIONOFFSts_333h : 225|2@0+ (1,0) [0|3] ""  ICC
 SG_ FCTAFCTBONOFFSts_333h : 227|2@0+ (1,0) [0|3] ""  ICC
 SG_ TRA_Operation_Status_333h : 231|4@0+ (1,0) [0|15] ""  ICC
 SG_ LightingBlueONOFFSts_333h : 233|2@0+ (1,0) [0|3] ""  ICC
 SG_ ADCC_AdsLowPowSts_333h : 235|2@0+ (1,0) [0|3] ""  ICC
 SG_ DataCollectionONOFFStS_333h : 237|2@0+ (1,0) [0|3] ""  ICC
 SG_ FCM_10_TLITrfcLi_333h : 239|2@0+ (1,0) [0|3] ""  ICC

BO_ 821 ADS_5: 48 FLZCU
 SG_ ADS_5_CRC1 : 7|8@0+ (1,0) [0|255] ""  ICC
 SG_ ADS_5_RollgCntr1 : 11|4@0+ (1,0) [0|14] ""  ICC
 SG_ ADS_5_Resd1 : 15|4@0+ (1,0) [0|15] ""  ICC
 SG_ ADS_5_ILOASts : 18|3@0+ (1,0) [0|7] ""  ICC
 SG_ ADS_5_ICAQuitReason : 21|3@0+ (1,0) [0|7] ""  ICC
 SG_ ADS_5_ISLISt : 23|2@0+ (1,0) [0|3] ""  ICC
 SG_ ADS_5_ISLISpeedLimitSign : 26|8@0+ (1,0) [0|255] ""  ICC
 SG_ ADS_5_ILOATextInfo : 28|2@0+ (1,0) [0|3] ""  ICC
 SG_ ADS_5_ILOAActdirection : 30|2@0+ (1,0) [0|3] ""  ICC
 SG_ ADS_5_LKS_warning : 31|1@0+ (1,0) [0|1] ""  ICC
 SG_ ADS_5_EgoLeftLineHeatgAg : 32|9@0+ (0.004,-1.02) [-1.02|1.02] "Rad"  ICC
 SG_ ADS_5_ISLIOverSpeedWarn : 34|2@0+ (1,0) [0|3] ""  ICC
 SG_ ADS_5_EgoLeLineHozlDst : 48|9@0+ (0.1,-25) [-25|25] "m"  ICC
 SG_ ADS_5_EgoLeLineID : 51|1@0+ (1,0) [0|1] ""  ICC
 SG_ ADS_5_EgoLeLineColor : 53|2@0+ (1,0) [0|3] ""  ICC
 SG_ ADS_5_EgoLeLineTyp : 55|2@0+ (1,0) [0|3] ""  ICC
 SG_ ADS_5_CRC2 : 71|8@0+ (1,0) [0|255] ""  ICC
 SG_ ADS_5_RollgCntr2 : 75|4@0+ (1,0) [0|14] ""  ICC
 SG_ ADS_5_Resd2 : 79|4@0+ (1,0) [0|15] ""  ICC
 SG_ ADS_5_EgoLeLineCrvt : 87|10@0+ (6E-005,-0.0156) [-0.0156|0.0156] "1/m"  ICC
 SG_ ADS_5_NeborLeLineHozlDst : 88|9@0+ (0.1,-25) [-25|25] "m"  ICC
 SG_ ADS_5_NeborLeLineID : 89|1@0+ (1,0) [0|1] ""  ICC
 SG_ ADS_5_NeborLeLineColor : 91|2@0+ (1,0) [0|3] ""  ICC
 SG_ ADS_5_NeborLeLineTyp : 93|2@0+ (1,0) [0|3] ""  ICC
 SG_ ADS_5_NeborLeLineCrvt : 111|10@0+ (6E-005,-0.0156) [-0.0156|0.0156] "1/m"  ICC
 SG_ ADS_5_NeborRiLineHozlDst : 112|9@0+ (0.1,-25) [-25|25] "m"  ICC
 SG_ ADS_5_NeborRiLineID : 113|1@0+ (1,0) [0|1] ""  ICC
 SG_ ADS_5_NeborRiLineColor : 115|2@0+ (1,0) [0|3] ""  ICC
 SG_ ADS_5_NeborRiLineTyp : 117|2@0+ (1,0) [0|3] ""  ICC
 SG_ ADS_5_CRC3 : 135|8@0+ (1,0) [0|255] ""  ICC
 SG_ ADS_5_RollgCntr3 : 139|4@0+ (1,0) [0|14] ""  ICC
 SG_ ADS_5_Resd3 : 143|4@0+ (1,0) [0|15] ""  ICC
 SG_ ADS_5_NeborRiLineCrvt : 151|10@0+ (6E-005,-0.0156) [-0.0156|0.0156] "1/m"  ICC
 SG_ ADS_5_ELKSettingSt : 153|2@0+ (1,0) [0|3] ""  ICC
 SG_ ADS_5_LDWLDPSnvtySet : 155|2@0+ (1,0) [0|3] ""  ICC
 SG_ ADS_5_LDWWarnType : 157|2@0+ (1,0) [0|3] ""  ICC
 SG_ ADS_5_IESSwtSet : 161|2@0+ (1,0) [0|3] ""  ICC
 SG_ ADS_5_IHCSettingSt : 163|2@0+ (1,0) [0|3] ""  ICC
 SG_ ADS_5_ISLIWarningMod : 165|2@0+ (1,0) [0|3] ""  ICC
 SG_ ADS_5_ICAEnableBtnSts : 167|2@0+ (1,0) [0|3] ""  ICC
 SG_ ADS_5_EgoRiLineTyp : 169|2@0+ (1,0) [0|3] ""  ICC
 SG_ ADS_5_FCM_Camera_textinfo : 175|2@0+ (1,0) [0|3] ""  ICC
 SG_ ADS_5_EgoRiLineHozlDst : 179|9@0+ (0.1,-25) [-25|25] "m"  ICC
 SG_ ADS_5_EgoRiLineColor : 181|2@0+ (1,0) [0|3] ""  ICC
 SG_ ADS_5_EgoRiLineID : 183|2@0+ (1,0) [0|3] ""  ICC
 SG_ ADS_5_CRC4 : 199|8@0+ (1,0) [0|255] ""  ICC
 SG_ ADS_5_RollgCntr4 : 203|4@0+ (1,0) [0|14] ""  ICC
 SG_ ADS_5_Resd4 : 207|4@0+ (1,0) [0|15] ""  ICC
 SG_ ADS_5_EgoRightLineHeatgAg : 215|9@0+ (0.004,-1.02) [-1.02|1.02] "Rad"  ICC
 SG_ ADS_5_EgoRiLineCrvt : 222|10@0+ (6E-005,-0.0156) [-0.0156|0.0156] "1/m"  ICC
 SG_ ADS_5_NeborLeftLineHeatgAg : 228|9@0+ (0.004,-1.02) [-1.02|1.02] "Rad"  ICC
 SG_ ADS_5_NeborRightLineHeatgAg : 235|9@0+ (0.004,-1.02) [-1.02|1.02] "Rad"  ICC

BO_ 850 ASU_6: 32 FLZCU
 SG_ ASU_6_HMIFailFb_JT : 23|4@0+ (1,0) [0|15] ""  ICC

BO_ 859 FLZCU_5: 8 FLZCU
 SG_ RearDefrostSts : 21|1@0+ (1,0) [0|1] ""  ICC

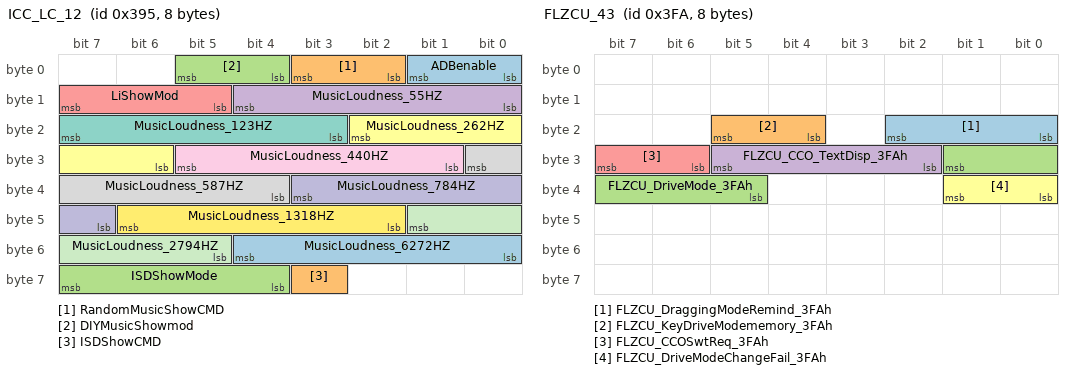
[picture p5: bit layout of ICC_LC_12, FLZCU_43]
BO_ 917 ICC_LC_12: 8 ICC
 SG_ ADBenable : 1|2@0+ (1,0) [0|3] ""  FLZCU
 SG_ RandomMusicShowCMD : 3|2@0+ (1,0) [0|3] ""  FLZCU
 SG_ DIYMusicShowmod : 5|2@0+ (1,0) [0|3] ""  FLZCU
 SG_ MusicLoudness_55HZ : 12|5@0+ (1,0) [0|31] ""  FLZCU
 SG_ LiShowMod : 15|3@0+ (1,0) [0|7] ""  FLZCU
 SG_ MusicLoudness_262HZ : 18|5@0+ (1,0) [0|31] ""  FLZCU
 SG_ MusicLoudness_123HZ : 23|5@0+ (1,0) [0|31] ""  FLZCU
 SG_ MusicLoudness_587HZ : 24|5@0+ (1,0) [0|31] ""  FLZCU
 SG_ MusicLoudness_440HZ : 29|5@0+ (1,0) [0|31] ""  FLZCU
 SG_ MusicLoudness_784HZ : 35|5@0+ (1,0) [0|31] ""  FLZCU
 SG_ MusicLoudness_2794HZ : 41|5@0+ (1,0) [0|31] ""  FLZCU
 SG_ MusicLoudness_1318HZ : 46|5@0+ (1,0) [0|31] ""  FLZCU
 SG_ MusicLoudness_6272HZ : 52|5@0+ (1,0) [0|31] ""  FLZCU
 SG_ ISDShowCMD : 59|1@0+ (1,0) [0|1] ""  FLZCU
 SG_ ISDShowMode : 63|4@0+ (1,0) [0|15] ""  FLZCU

BO_ 943 CSA_3: 32 FLZCU
 SG_ CSA_3_CRC1 : 7|8@0+ (1,0) [0|255] ""  ICC
 SG_ CSA_3_RollgCntr1 : 11|4@0+ (1,0) [0|14] ""  ICC
 SG_ CSA_3_Resd1 : 15|4@0+ (1,0) [0|15] ""  ICC
 SG_ FlwheelBearing : 23|12@0+ (0.001,0) [0|4.095] "t"  ICC
 SG_ FrwheelBearing : 27|12@0+ (0.001,0) [0|4.095] "t"  ICC
 SG_ BlwheelBearing : 47|12@0+ (0.001,0) [0|4.095] "t"  ICC
 SG_ BrwheelBearing : 51|12@0+ (0.001,0) [0|4.095] "t"  ICC
 SG_ CSA_3_CRC2 : 71|8@0+ (1,0) [0|255] ""  ICC
 SG_ CSA_3_RollgCntr2 : 75|4@0+ (1,0) [0|14] ""  ICC
 SG_ VehicleBearing_kg : 87|12@0+ (1,0) [0|4095] "kg"  ICC
 SG_ VehicleBearing_lb : 91|14@0+ (1,0) [0|16383] "lb"  ICC
 SG_ GoodsWeight_kg : 109|12@0+ (1,0) [0|4095] "kg"  ICC
 SG_ Goods_Weight_Ratio : 113|10@0+ (0.1,0) [0|100] "%"  ICC
 SG_ CSA_3_CRC3 : 135|8@0+ (1,0) [0|255] ""  ICC
 SG_ CSA_3_RollgCntr3 : 139|4@0+ (1,0) [0|14] ""  ICC
 SG_ CSA_3_Resd3 : 143|4@0+ (1,0) [0|15] ""  ICC
 SG_ GoodsWeight_lb : 151|14@0+ (1,0) [0|16383] "lb"  ICC
 SG_ OverWeightValue_kg : 153|12@0+ (1,0) [0|4095] "kg"  ICC
 SG_ OverWeightValue_lb : 173|14@0+ (1,0) [0|16383] "lb"  ICC
 SG_ OverLoadWarnShieldSetFed : 187|2@0+ (1,0) [0|3] ""  ICC
 SG_ OverWeightWarning : 188|1@0+ (1,0) [0|1] ""  ICC
 SG_ OverWeightRatio : 191|3@0+ (1,0) [0|7] "%"  ICC
 SG_ Fraxlebearingrate : 199|8@0+ (1,0) [0|100] "%"  ICC

BO_ 949 PEPS_1: 16 FLZCU
 SG_ PEPS_OrderInformation : 21|4@0+ (1,0) [0|15] ""  ICC
 SG_ PEPS_InformationSource : 23|2@0+ (1,0) [0|3] ""  ICC
 SG_ PEPS_KeySts : 27|3@0+ (1,0) [0|7] ""  ICC
 SG_ PEPS_IDInformation : 31|4@0+ (1,0) [0|15] ""  ICC
 SG_ PEPS_ETRUnLockReq : 39|2@0+ (1,0) [0|3] ""  ICC

BO_ 991 TMS_2: 24 FLZCU
 SG_ TMS_BatteryLoopErrorLevel : 123|3@0+ (1,0) [0|7] ""  ICC
 SG_ TMS_MotorLoopErrorLevel : 126|3@0+ (1,0) [0|7] ""  ICC

BO_ 1018 FLZCU_43: 8 FLZCU
 SG_ FLZCU_DraggingModeRemind_3FAh : 18|3@0+ (1,0) [0|7] ""  ICC
 SG_ FLZCU_KeyDriveModememory_3FAh : 21|2@0+ (1,0) [0|3] ""  ICC
 SG_ FLZCU_DriveMode_3FAh : 25|5@0+ (1,0) [0|31] ""  ICC
 SG_ FLZCU_CCO_TextDisp_3FAh : 29|4@0+ (1,0) [0|15] ""  ICC
 SG_ FLZCU_CCOSwtReq_3FAh : 31|2@0+ (1,0) [0|3] ""  ICC
 SG_ FLZCU_DriveModeChangeFail_3FAh : 33|2@0+ (1,0) [0|3] ""  ICC

BO_ 1020 FLZCU_41: 64 FLZCU
 SG_ SAM_1_SteeringAngleSpeed : 23|8@0+ (4,0) [0|1016] "deg/Sec"  ICC
 SG_ SAM_1_SteeringAngle : 31|16@0+ (0.0625,-2048) [-2048|2047.875] "deg"  ICC
 SG_ BMSH_MaxChgPwrPeak : 47|12@0+ (0.1,0) [0|320] "KW"  ICC
 SG_ BMSH_MaxDchgPwrPeak : 51|12@0+ (0.1,0) [0|320] "KW"  ICC
 SG_ FMCU_8_ISGF_SpdAct : 71|16@0+ (1,-32767) [-32767|32766] "rpm"  ICC
 SG_ RMCU_1_Speed : 87|16@0+ (1,-32767) [-32767|32766] "rpm"  ICC
 SG_ SAM_1_SteeringAngleVD : 96|1@0+ (1,0) [0|1] ""  ICC
 SG_ SAM_1_SteeringAngleSpeedVD : 97|1@0+ (1,0) [0|1] ""  ICC
 SG_ CSA_2_AllWarningInfo : 100|3@0+ (1,0) [0|7] ""  ICC
 SG_ RMCU_1_TCURErrLvlDis : 127|3@0+ (1,0) [0|7] ""  ICC
 SG_ ASU_2_sensorErrorSts : 143|4@0+ (1,0) [0|15] ""  ICC
 SG_ ASU_2_LFHeight : 151|12@0+ (0.1,-150) [0|259.4] "mm"  ICC
 SG_ ASU_2_RFHeight : 155|12@0+ (0.1,-150) [0|259.4] "mm"  ICC
 SG_ ASU_2_LRHeight : 175|12@0+ (0.1,-150) [0|259.4] "mm"  ICC
 SG_ ASU_2_RRHeight : 179|12@0+ (0.1,-150) [0|259.4] "mm"  ICC
 SG_ CSA_2_WiprFrntCmd : 209|2@0+ (1,0) [0|3] ""  ICC
 SG_ EVCC_GunConnectSt_203h : 211|2@0+ (1,0) [0|3] ""  ICC
 SG_ STAT_ShifterLeverFault : 214|3@0+ (1,0) [0|7] ""  ICC

BO_ 1022 FLZCU_40: 64 FLZCU
 SG_ FLZCU_MedStatusFb : 17|2@0+ (1,0) [0|3] ""  ICC
 SG_ FLZCU_SteerWhlposSts : 20|3@0+ (1,0) [0|7] ""  ICC
 SG_ FLZCU_CarMode : 23|3@0+ (1,0) [0|7] ""  ICC
 SG_ FLZCU_MedAreaFb : 27|4@0+ (1,0) [0|15] ""  ICC
 SG_ FLZCU_MedFailCause : 31|4@0+ (1,0) [0|15] ""  ICC
 SG_ DrvSecSeatLvltargetCmd_3FEh : 34|7@0+ (1,-1) [-1|100] "%"  ICC
 SG_ FLZCU_NapArea2Fb : 37|3@0+ (1,0) [0|7] ""  ICC
 SG_ FLZCU_MedClosePrompt : 39|2@0+ (1,0) [0|3] ""  ICC
 SG_ DrvSecSeatBackAgCmd_3FEh : 43|7@0+ (1,-1) [-1|100] "%"  ICC
 SG_ DrvSecSeatLegSpprtCmd_3FEh : 52|7@0+ (1,-1) [-1|100] "%"  ICC
 SG_ FLZCU_LogoChargingSts : 58|2@0+ (1,0) [0|3] ""  ICC
 SG_ FLZCU_MonoAmbLigSts : 59|1@0+ (1,0) [0|1] ""  ICC
 SG_ DrvRearWinThermalStatus_3FEh : 60|1@0+ (1,0) [0|1] ""  ICC
 SG_ DrvWinThermalStatus_3FEh : 61|1@0+ (1,0) [0|1] ""  ICC
 SG_ PassRearSeatBackAgCmd_3FEh : 80|7@0+ (1,-1) [-1|100] "%"  ICC
 SG_ PassRearSeatLvltargetCmd_3FEh : 87|7@0+ (1,-1) [-1|100] "%"  ICC
 SG_ PassRearSeatLegSpprtCmd_3FEh : 89|7@0+ (1,-1) [-1|100] "%"  ICC
 SG_ DrvSitPosnSts_3FEh : 98|3@0+ (1,0) [0|7] ""  ICC
 SG_ DrvRearSeatVentLvl2_3FEh : 107|4@0+ (1,0) [0|15] ""  ICC
 SG_ DrvSeatVentLvl2_3FEh : 111|4@0+ (1,0) [0|15] ""  ICC
 SG_ DrvRearSeatHeatLvl2_3FEh : 115|4@0+ (1,0) [0|15] ""  ICC
 SG_ DrvSeatHeatLvl2_3FEh : 119|4@0+ (1,0) [0|15] ""  ICC
 SG_ FLZCU_DrvExpSeatSts_3FEh : 129|2@0+ (1,0) [0|3] ""  ICC
 SG_ FLZCU_FLogolightInhibitSts : 130|1@0+ (1,0) [0|1] ""  ICC
 SG_ FLZCU_SteerOverHeatWarn : 134|1@0+ (1,0) [0|1] ""  ICC
 SG_ MaintenanceOdometer_Backup_3FEh : 175|24@0+ (0.1,0) [0|999999.9] "KM"  ICC

BO_ 1024 FRZCU_13: 64 FLZCU
 SG_ CSunshadePercentSts : 20|4@0+ (1,0) [0|15] ""  ICC
 SG_ CSunshadeSts : 23|3@0+ (1,0) [0|7] ""  ICC
 SG_ PassSeatVentLvl2_400h : 27|4@0+ (1,0) [0|15] ""  ICC
 SG_ PassSeatHeatLvl2_400h : 31|4@0+ (1,0) [0|15] ""  ICC
 SG_ PassSecSeatHeatLvl2_400h : 35|4@0+ (1,0) [0|15] ""  ICC
 SG_ PassSecSeatVentLvl2_400h : 39|4@0+ (1,0) [0|15] ""  ICC
 SG_ FRZCU_OnekeyHVoffSwtst : 41|2@0+ (1,0) [0|3] ""  ICC
 SG_ FRZCU_CSunshadeThermalSts : 43|1@0+ (1,0) [0|1] ""  ICC
 SG_ PassRearWinThermalSts_400h : 44|1@0+ (1,0) [0|1] ""  ICC
 SG_ PassWinThermalSts_400h : 45|1@0+ (1,0) [0|1] ""  ICC
 SG_ FRZCU_ContainerlightSts : 47|2@0+ (1,0) [0|3] ""  ICC
 SG_ FRZCU_ADSLightSts : 49|2@0+ (1,0) [0|3] ""  ICC
 SG_ FRZCU_QueenSeatEnterSts : 57|2@0+ (1,0) [0|3] ""  ICC
 SG_ FRZCU_PasgerSeatMovFailCause : 61|4@0+ (1,0) [0|15] ""  ICC
 SG_ FRZCU_ADSLightFltSts : 63|2@0+ (1,0) [0|3] ""  ICC
 SG_ FRZCU_QueenSeatPosSts : 80|1@0+ (1,0) [0|1] ""  ICC
 SG_ FRZCU_QueenSeatSts : 83|2@0+ (1,0) [0|3] ""  ICC
 SG_ FRZCU_QueenSeatMovFailCause : 87|4@0+ (1,0) [0|15] ""  ICC
 SG_ CSunshadeLearnedSts : 93|2@0+ (1,0) [0|3] ""  ICC
 SG_ CSunshadePosn : 103|7@0+ (1,0) [0|100] "%"  ICC

CM_ SG_ 33 ACU_3_LongitudinalAcceleration "纵向加速度
Longitudinal acceleration signal
Sensor accuracy：0.0027680342857143 g";
CM_ SG_ 33 ACU_3_LongitudinalAccelerationVD "纵向加速度有效位
If hasn’t been calibrated, after initialization, this signal ‘s value is always10(invalid)";
CM_ SG_ 33 ACU_3_CrashOutputSts "碰撞状态信号
Crash signal indicates the status according to bit:
If multiple directions collide at the same time, each collision flag bit representing each direction will be set to 1.For example, if left crash is superimposed with right crash, the output signal is 00001100
此信号发到ECU停止工作为止";
CM_ SG_ 49 ACU_2_LateralAcceleration "横向加速度
Lateral acceleration signal
Sensor accuracy：0.0027680342857143g";
CM_ SG_ 49 ACU_2_YawRate "偏航角速度
Yaw rate signal
Sensor accuracy：0.122189236 deg/s";
CM_ SG_ 49 ACU_2_YawrateSigValidData "偏航角速度有效性
Signal state for yawrate";
CM_ SG_ 49 ACU_2_LateralAccelerationSigVD "横向加速度有效性
If hasn’t been calibrated, after initialization, this signal ‘s value is always 10(invalid).";
CM_ SG_ 258 BMS_1_CRC1 "Profile1A:E2E CRC (SAE J1850 CRC-8) for 8 Bytes
DataID:0x0014";
CM_ SG_ 258 BMS_1_RollgCntr1 "Profile1A:E2E Rolling message counter(the maximum value of Alive counter is 14)";
CM_ SG_ 258 BMS_1_Resd1 "Profile1A:E2E Reserved";
CM_ SG_ 258 BMS_PackVoltage "电池包电压（实际电压）
Battery Voltage";
CM_ SG_ 258 BMS_PackCurrent "电池包电流
Baattery Current(direction:discharge+ charge -)";
CM_ SG_ 258 BMS_HvBattSts "BMS实际状态
Battery State
拆帧至GL 网段
ID 0x397(FLZCU_16)20-23Bit";
CM_ SG_ 258 BMS_SysSelfCheck "系统自检
BMS Self Check State";
CM_ SG_ 258 BMS_HVBattThermRunaway "热失控
Thermal Run-away
拆帧至ID 0x397(FLZCU_16)18-19Bit";
CM_ SG_ 258 BMS_1_CRC2 "Profile1A:E2E CRC (SAE J1850 CRC-8) for 8 Bytes
DataID:No ASIL requirements.Not configure
CRC Reserved.";
CM_ SG_ 258 BMS_1_RollgCntr2 "Profile1A:E2E Rolling message counter(the maximum value of Alive counter is 14)";
CM_ SG_ 258 BMS_1_Resd2 "Profile1A:E2E Reserved";
CM_ SG_ 258 BMS_ChargeVoltageReq "充电请求电压（快充）
Chagre Voltage Request indiction(only for BMS internal analysis)";
CM_ SG_ 258 BMS_ChgCurrReq "充电请求电流（快充）
Chagre Current Request t indiction(only for BMS internal analysis)";
CM_ SG_ 258 BMS_InfraDcUActDc "快充桩的实际输出电压
DC-charge station actual ouput voltage(only for BMS internal analysis)";
CM_ SG_ 258 BMS_1_CRC3 "Profile1A:E2E CRC (SAE J1850 CRC-8) for 8 Bytes
DataID:0x0015";
CM_ SG_ 258 BMS_1_RollgCntr3 "Profile1A:E2E Rolling message counter(the maximum value of Alive counter is 14)";
CM_ SG_ 258 BMS_1_Resd3 "Profile1A:E2E Reserved";
CM_ SG_ 258 BMS_InfraDcIActDc "快充桩的实际输出电流
DC-charge station actual ouput current(only for BMS internal analysis)";
CM_ SG_ 258 BMS_HvBattDynChrgnILim "最大允许充电电流（快慢充共用）
battery chagre current limit";
CM_ SG_ 258 BMS_HvBattUChrgnLim "最大允许充电电压（快慢充共用）
battery chagre voltage limit";
CM_ SG_ 258 BMS_1_CRC4 "Profile1A:E2E CRC (SAE J1850 CRC-8) for 8 Bytes
DataID:0x0016";
CM_ SG_ 258 BMS_1_RollgCntr4 "Profile1A:E2E Rolling message counter(the maximum value of Alive counter is 14)";
CM_ SG_ 258 BMS_1_Resd4 "Profile1A:E2E Reserved";
CM_ SG_ 258 BMS_ChrgDcIAvl "桩最大输出电流
DC-charge station charging current limit";
CM_ SG_ 258 BMS_DChrgAPlusSt "A+状态  边沿检测
DC A+ status";
CM_ SG_ 258 BMS_Insulation_R "绝缘阻值(取双边中较小值)
insulation resistance";
CM_ SG_ 258 BMS_ChrgDcCnctrDetd "CC2连接状态
CC2 connect state
拆帧至DK 网段ID 0x4E9(FLZCU_28)14-15Bit";
CM_ SG_ 258 BMS_DCChgMode "快充模式
DC charge mode
0x0:Default 默认值
0x1:HandOver 握手
0x2:ParaConfig充电配置
0x3:Chging充电中
0x4:ChgEnd充电结束
0x5:ChgWaring充电警告
0x6:ChgFault充电错误
CATL无0x5状态，可以不进行配置。";
CM_ SG_ 258 BMS_ChrgDcChrgnFltStopReas "Dc charge stop reason";
CM_ SG_ 258 BMS_1_CRC5 "Profile1A:E2E CRC (SAE J1850 CRC-8) for 8 Bytes
DataID:0x0017";
CM_ SG_ 258 BMS_1_RollgCntr5 "Profile1A:E2E Rolling message counter(the maximum value of Alive counter is 14)";
CM_ SG_ 258 BMS_1_Resd5 "Profile1A:E2E Reserved";
CM_ SG_ 258 BMS_ChgRemTime "剩余充电时间
remain charging time
BMS以实际充电电流进行测算剩余充电时间，快慢充共用信号。充电状态发正常计算值，非充电状态发0。";
CM_ SG_ 258 BMS_ChargeRequest_Mode "充电模式请求
charge request mode
0x0:没有请求
0x1: 慢充请求
0x2:升压模式请求
0x3:快充请求
0x4:充电预充请求
0x5~0xE:Reserved预留
0xF:init无效值
快充与慢充流程需使用该信号
0x2，0x4，0xF无定义";
CM_ SG_ 258 BMS_1_StateOfChargeDis "显示SOC
battery indication SOC
拆帧至GL 网段ID 0x397(FLZCU_16)24-31Bit";
CM_ SG_ 258 BMS_StateOfEnergy "电池SOEbattery SOE";
CM_ SG_ 258 BMS_1_CRC6 "Profile1A:E2E CRC (SAE J1850 CRC-8) for 8 Bytes
DataID:0x0018";
CM_ SG_ 258 BMS_1_RollgCntr6 "Profile1A:E2E Rolling message counter(the maximum value of Alive counter is 14)";
CM_ SG_ 258 BMS_1_Resd6 "Profile1A:E2E Reserved";
CM_ SG_ 258 BMS_StateOfHealth "电池SOH
battery SOH
0x7E: Error
0x7F: Init";
CM_ SG_ 258 BMS_BlanceState "电池均衡状态
battery balance state";
CM_ SG_ 258 BMS_IsolationFault "电池绝缘故障
battery insulation fault state";
CM_ SG_ 258 BMS_HVILFault_DC "DC internal HVIL fault
捷途使用该信号发送BMS电池包内部高压互锁故障状态";
CM_ SG_ 258 BMS_SOCDis "发送显示SOC
battery indication SOC";
CM_ SG_ 258 BMS_InfraDcIActDcMin "桩最小输出电流
DC-charge station actual ouput current(only for BMS internal analysis)";
CM_ SG_ 259 EMS_EngineSpeed_Actual "发动机转速（实际）
PHEV:Actual Engine speed send by EMS to HCU";
CM_ SG_ 290 EPS_1_CRC "Profile1A:E2E CRC (SAE J1850 CRC-8) for 8 Bytes
DataID:0x002E";
CM_ SG_ 290 EPS_1_RollgCntr "Profile1A:E2E Rolling message counter(the maximum value of Alive counter is 14)";
CM_ SG_ 290 EPSFailSts "EPS Fail Status";
CM_ SG_ 290 EPSSteeringAngleCalibrationSts "EPS Steering Angle Calibration Status";
CM_ SG_ 290 EPS_EOTLearning_Sts "Indicates the status of EPS EOT(end of travel) learning, displayed on the DMC(ICM)";
CM_ SG_ 513 MFSL_UP_SW "上调节开关";
CM_ SG_ 513 MFSL_DW_SW "下调节开关";
CM_ SG_ 513 MFSL_Left_SW "左调节开关";
CM_ SG_ 513 MFSL_Right_SW "右调节开关";
CM_ SG_ 513 MFSL_OK_SW "确认";
CM_ SG_ 513 MFSL_APA_SW "APA开关";
CM_ SG_ 513 MFSL_LCC_NCA_SW "行车功能激活按键";
CM_ BO_ 514 "华为MDC新增";
CM_ SG_ 514 ADS_CRC1_202h "Profile1A:E2E CRC (SAE J1850 CRC-8) for 8 Bytes
DataID:0x00FF";
CM_ SG_ 514 ADS_RollgCntr1_202h "Profile1A:E2E Rolling message counter(the maximum value of Alive counter is 14)";
CM_ SG_ 514 ADS_Resd1_202h "Profile1A:E2E Reserved";
CM_ SG_ 514 ADS_NicaReminderAcoustic_202h "ADS功能告警声音提醒";
CM_ SG_ 514 ADS_NicaReminderLEDVisual_202h "ADS功能接告警灯提醒";
CM_ SG_ 514 ADS_AdsFault_202h "ADS系统故障";
CM_ SG_ 514 ADS_TakeoverID_202h "ADS功能接管提醒ID";
CM_ SG_ 514 ADS_TakeoverType_202h "TORType";
CM_ SG_ 514 ADS_TakeoverLevel_202h "TORLevel";
CM_ SG_ 514 ADS_TORIDCorrespErrorID_202h "TOR对应的error code ID";
CM_ SG_ 514 ADS_TakeoverExtended16bit_202h "接管扩展字段(如：弹窗内数值显示)";
CM_ SG_ 514 ADS_TakeoverExtended8bit_202h "接管扩展字段(如：功能激活失败)";
CM_ SG_ 517 MFSR_UP_SW "上调节开关";
CM_ SG_ 517 MFSR_DW_SW "下调节开关";
CM_ SG_ 517 MFSR_Left_SW "左调节开关";
CM_ SG_ 517 MFSR_Right_SW "右调节开关";
CM_ SG_ 517 MFSR_OK_SW "确认";
CM_ SG_ 517 MFSR_Voice_SW "语音唤醒";
CM_ SG_ 517 MFSR_Customize "用户自定义开关";
CM_ BO_ 524 "国内高配ADCC发整帧国内低配FCM只发送ADS_6_Customize_buttonsFB国际项目FRM只发送ADS_6_Customize_buttonsFB";
CM_ SG_ 524 ADS_6_Customize_buttonsFB "自定义按键大屏设置设置项反馈";
CM_ SG_ 571 LHTurnlightSts "左转向灯工作状态";
CM_ SG_ 571 RHTurnlightSts "右转向灯工作状态";
CM_ SG_ 571 DrvDoorSts_23Bh "主驾门状态";
CM_ SG_ 571 DrvDoorLockSts_23Bh "主驾门锁状态";
CM_ SG_ 571 LHTurnSW "左转向开关，打开发1；关闭发0，默认发0";
CM_ SG_ 571 RHTurnSW "右转向开关，打开发1；关闭发0，默认发0";
CM_ SG_ 571 HazardLightSW "带自锁的开关，按照危险灯状态发送；不带自锁的开关，发送危险灯状态";
CM_ SG_ 571 DrvSeatBeltSW_23Bh "安全带检测开关，0为未插入，1为插入";
CM_ SG_ 571 DirectionIndLeft "当左转向灯闪烁时一直发1，转向灯熄灭时一直发0
左转向灯实际状态";
CM_ SG_ 571 DirectionIndRight "当右转向灯闪烁时一直发1，转向灯熄灭时一直发0
右转向灯实际状态";
CM_ SG_ 572 ONEBOX_7_TAB_HighTemp "坦克转弯工作温度过高";
CM_ SG_ 572 ONEBOX_7_TAB_Active "IPB反馈TAB状态";
CM_ SG_ 572 ONEBOX_7_BSW_Active "智能擦盘状态反馈信号";
CM_ SG_ 572 ONEBOX_7_iCCO_Active "IPB反馈iCCO功能状态";
CM_ SG_ 572 ONEBOX_7_iCCO_TgtVel "iCCO功能目标车速";
CM_ SG_ 587 ONEBOX_4_LHFWheelSpeedRPM "left front Wheel Speed(the unit is RPM)";
CM_ SG_ 587 ONEBOX_4_RHFWheelSpeedRPM "right front  Wheel Speed(the unit is RPM)";
CM_ SG_ 587 LHRWheelSpeedRPM "Left Rear Wheel Speed(the unit is RPM)";
CM_ SG_ 587 RHRWheelSpeedRPM "right Rear  Wheel Speed(the unit is RPM)";
CM_ SG_ 587 LHRPulseCounter "left rear wheel Pulse Counter";
CM_ SG_ 587 LHRPulseCounterFailSts "left rear wheel Pulse Counter Fail Status";
CM_ SG_ 587 RHRPulseCounter "right rear wheel Pulse Counter";
CM_ SG_ 587 RHRPulseCounterFailSts "right rear wheel Pulse Counter FailSts";
CM_ SG_ 587 RHFPulseCounter "right front wheel Pulse Counter";
CM_ SG_ 587 RHFPulseCounterFailSts "right front wheel Pulse Counter FailSts";
CM_ SG_ 587 LHFPulseCounter "left front wheel Pulse Counter";
CM_ SG_ 587 LHFPulseCounterFailSts "left front wheel Pulse Counter FailSts";
CM_ SG_ 587 LHFWheelDriveDirection "left front Wheel Drive Direction";
CM_ SG_ 587 RHFWheelDriveDirection "right front Wheel Speed Drive Direction";
CM_ SG_ 587 LHRWheelDriveDirection "left rear Wheel Speed Drive Direction";
CM_ SG_ 587 RHRWheelDriveDirection "right rear Wheel Speed Drive Direction";
CM_ SG_ 587 IPB_SandABSAvl_24Bh "沙地ABS功能可用状态";
CM_ SG_ 587 IPB_SandABSSwSts_24Bh "沙地ABS开关状态";
CM_ SG_ 612 CRC1_264h "Profile1A:E2E CRC (SAE J1850 CRC-8) for 8 Bytes
DataID:0x002B";
CM_ SG_ 612 RollgCntr1_264h "Profile1A:E2E Rolling message counter(the maximum value of Alive counter is 14)";
CM_ SG_ 612 EPBAUTO_Status_264h "熄火自动驻车";
CM_ SG_ 612 FltLamp_264h "EPB故障状态
诊断和转毂测试模式时闪烁";
CM_ SG_ 612 ParkLamp_264h "EPB驻车灯状态
动态制动时闪烁";
CM_ SG_ 612 ActrSt_264h "Current state of APB actuator connected to ECU
EPB卡钳执行状态

备注：
①一边夹紧一边释放，按博世最新平台策略，一按照Applied外发。
②0x5:CompletelyReleased（IPB2.0实际按照Reserved）
③0x6:Half Applied（IPB2.0实际按照Reserved）";
CM_ SG_ 612 RWUSt_264h "EPB 后轮防抱死工作状态：
0x1:active仪表持续提示“紧急制动开启”且仪表红“P”灯闪烁，同时点亮制动尾灯，最后1帧信号显示完后结束";
CM_ SG_ 612 TextDisp_264h "EPB文本提示
备注：
0x1:驻车坡度过大，请注意安全
0x2:IPB2.0实际按照Reserved
0x3:请关好车门并系好安全带
0x4:请同时踩下制动踏板
0x5:IPB2.0新增禁止P档手动释放EPB文字提示“请切换到非P档解除电子驻车”
0x6:请先将挡位置于N挡，然后踩下制动踏板方可关闭熄火自动驻车功能";
CM_ SG_ 612 IPB_EPBErrorStatus "用于EPB故障显示";
CM_ SG_ 632 EngineCoolantTemperature "Engine coolant temperture
发动机水温";
CM_ SG_ 638 FRZCU_HoodSts "前舱盖状态
源头FRZCU_HoodSts";
CM_ SG_ 638 FRZCU_AuthenResult "源头FRZCU_AuthenResult";
CM_ SG_ 638 FRZCU_TrunkSts "FRZCU不发，由BBCM发
源头FRZCU_TrunkSts";
CM_ SG_ 638 DrvHandleSwitchSts_27Eh "主驾门把手开关状态
FRZCU_HandleSwitchStsFL
源头DrvHandleSwitchSts_27Eh";
CM_ SG_ 638 PassHandleSwitchSts_27Eh "副驾门把手开关状态
FRZCU_HandleSwitchStsFR
源头PassHandleSwitchSts_27Eh";
CM_ SG_ 638 PassRearHandleSwitchSts_27Eh "副驾后门把手开关状态
FRZCU_HandleSwitchStsRR
源头PassRearHandleSwitchSts_27Eh";
CM_ SG_ 638 DrvRearHandleSwitchSts_27Eh "主驾后门把手开关状态
FRZCU_HandleSwitchStsRL
源头DrvRearHandleSwitchSts_27Eh";
CM_ SG_ 638 SeatLength_target_Passenger "座椅水平位置调节";
CM_ SG_ 638 FRZCU_TrunkLockSts "源头FRZCU_TrunkLockSts";
CM_ SG_ 638 SeatBackrest_target_Passenger "座椅靠背角度调节";
CM_ SG_ 638 FRZCU_GloveboxSW "上报手套箱开关状态";
CM_ SG_ 638 FrontBackSpeedAdj_Cmd "Front_Back_Speed_Adjust_Command
座椅前后调节速度信号";
CM_ SG_ 638 FRZCU_HoodLockSts "源头FRZCU_HoodLockSts";
CM_ SG_ 638 FRZCU_PELockInKeyWarning "PE闭锁车内有钥匙提醒";
CM_ SG_ 638 PassRearReleaseLockSts_27Eh "FRZCU_RRReleaseLockSts
副驾后电释放状态
0x0:None
0x1:已释放
0x2:释放中
0x3:已复位
0x4:复位中";
CM_ SG_ 638 PassReleaseLockSts_27Eh "FRZCU_FRReleaseLockSts
副驾电释放状态
0x0:None
0x1:已释放
0x2:释放中
0x3:已复位
0x4:复位中";
CM_ SG_ 638 FRZCU_OTAPwrDwnReqFb "OTA_Power_Down_Request_FeedBack";
CM_ SG_ 638 FRZCU_KeylessWarning "无合法钥匙提醒";
CM_ SG_ 638 FRZCU_PowerOFFWarning "电源下电提醒";
CM_ SG_ 638 FRZCU_OTAPwrOnReqFb "OTA_Power_On_Request_FeedBack";
CM_ SG_ 644 ICM_5_FuelLevel_284h "国六项目EMS收，滤波后的燃油液位信息";
CM_ SG_ 644 FuelShortGround "备注：国六项目EMS收，短路到地";
CM_ SG_ 644 FuelShortPower "备注：国六项目EMS收，短路到电源";
CM_ SG_ 644 FuelOutOfRange "备注：国六项目EMS收。超范围";
CM_ SG_ 644 FuelValidData "备注：国六项目EMS收，开路，信号丢失";
CM_ SG_ 683 PassDoorSts_2ABh "副驾门状态
RHFDoorSts";
CM_ SG_ 683 ParkLightSts "位置灯状态
源头ParkLightSts";
CM_ SG_ 683 PassWinPosn_2ABh "副驾玻璃开度
FRWinPosn
Front Right Window Position";
CM_ SG_ 683 PassRearWinPosn_2ABh "副驾后玻璃开度
RRWinPosn
Rear Right Window Position";
CM_ SG_ 683 PassRearDoorSts_2ABh "副驾后门状态
RHRDoorSts";
CM_ SG_ 699 DrvRearDoorSts_2BBh "主驾后门状态";
CM_ BO_ 769 "华为MDC新增";
CM_ SG_ 769 ADS_LccNcaFunctionStatus_301h "LCC和NCA的功能状态机";
CM_ SG_ 769 ADS_AccFunctionStatus_301h "ACC功能状态机";
CM_ SG_ 769 ADS_AvpFunctionStatus_301h "AVP的功能状态机";
CM_ SG_ 769 ADS_AdsFucntionNotActive_301h "ADS无法激活";
CM_ SG_ 769 ADS_SpeedSetByDriver_301h "ADS 智驾定速值";
CM_ SG_ 769 ADS_SpeedLimitValue_301h "ADS 道路限速值";
CM_ SG_ 769 ADS_OneTouchSpeedAdjustment_301h "非智能限速一键调速";
CM_ SG_ 769 ADS_SpeedAutoFollow_301h "智能限速状态";
CM_ SG_ 769 ADS_HODReminder_301h "脱手提醒";
CM_ SG_ 769 ADS_CalibState_301h "标定状态";
CM_ SG_ 769 ADS_FcwFault_301h "FCW故障";
CM_ SG_ 769 ADS_FcwWaning_301h "FCW告警";
CM_ SG_ 769 ADS_DMSReminder_301h "DIL提醒";
CM_ SG_ 769 ADS_AebObjType_301h "AEB触发障碍物类型";
CM_ SG_ 769 ADS_AebFault_301h "AEB故障";
CM_ SG_ 769 ADS_AebWaning_301h "AEB告警";
CM_ SG_ 769 ADS_RcwWarning_301h "RCW告警";
CM_ SG_ 769 ADS_RaebFault_301h "RAEB故障";
CM_ SG_ 769 ADS_RaebWarning_301h "RAEB告警";
CM_ SG_ 769 ADS_FctaRightWarning_301h "右FCTA告警";
CM_ SG_ 769 ADS_FctaLeftWarning_301h "左FCTA告警";
CM_ SG_ 769 ADS_RcwFault_301h "RCW故障";
CM_ SG_ 769 ADS_FctbRightWarning_301h "右FCTB告警";
CM_ SG_ 769 ADS_FctbLeftWarning_301h "左FCTB告警";
CM_ SG_ 769 ADS_RctaFault_301h "RCTA故障";
CM_ SG_ 769 ADS_RctaRightWarning_301h "右RCTA告警";
CM_ SG_ 769 ADS_RctaLeftWarning_301h "左RCTA告警";
CM_ SG_ 769 ADS_LdwWarning_301h "LDW告警";
CM_ SG_ 769 ADS_RctbRightWarning_301h "右RCTB告警";
CM_ SG_ 769 ADS_RctbLeftWarning_301h "左RCTB告警";
CM_ SG_ 769 ADS_LkaFault_301h "LKA故障";
CM_ SG_ 769 ADS_LKAWarning_301h "LKA告警";
CM_ SG_ 769 ADS_LdwFault_301h "LDW故障";
CM_ SG_ 769 ADS_BsdFault_301h "BSD故障";
CM_ SG_ 769 ADS_RightMirrWarningCmd_301h "右BSD告警";
CM_ SG_ 769 ADS_LeftMirrWarningCmd_301h "左BSD告警";
CM_ SG_ 769 ADS_RiFrntDoorWarningCmd_301h "右前门的告警";
CM_ SG_ 769 ADS_LeReDoorWarningCmd_301h "左后门的告警";
CM_ SG_ 769 ADS_LeFrntDoorWarningCmd_301h "左前门的告警";
CM_ SG_ 769 ADS_SpeedLimitWarning_301h "超速告警";
CM_ SG_ 769 ADS_DowFault_301h "DOW故障";
CM_ SG_ 769 ADS_RiReDoorWarningCmd_301h "右后门的告警";
CM_ SG_ 769 ADS_ElkaFault_301h "ELKA故障";
CM_ SG_ 769 ADS_TlaFault_301h "TLA故障";
CM_ SG_ 769 ADS_TsrFault_301h "TSR故障";
CM_ SG_ 769 ADS_AbsoultwSpeedLimit_301h "设定的绝对限速值";
CM_ SG_ 769 ADS_ElkaWarning_301h "ELKA告警";
CM_ SG_ 769 ADS_TlaWarning_301h "TLA告警";
CM_ BO_ 770 "华为MDC新增";
CM_ SG_ 770 ADS_RPAOnlineOrNot_302h "RPA业务心跳消息";
CM_ SG_ 770 ADS_VehParkMod_302h "自车泊入方式";
CM_ SG_ 770 ADS_SeldParkID_302h "选中的目标车位ID号";
CM_ SG_ 770 ADS_RpaParkAuthn_302h "RPA泊车授权";
CM_ SG_ 770 ADS_ParkProgs_302h "泊车进度0~100%";
CM_ SG_ 770 ADS_ParkDirCfm_302h "RPA泊出方向确认";
CM_ SG_ 770 ADS_RemParkPatSel_302h "RPA远程泊车模式选择确认";
CM_ SG_ 770 ADS_ParkRmngDst_302h "泊车剩余距离0~50m";
CM_ SG_ 770 ADS_ObstclDst_302h "障碍物距离";
CM_ SG_ 770 ADS_AutEve_302h "智能驾驶事件（RPA指示信息）";
CM_ SG_ 770 ADS_parkInterruptDuration_302h "RPA暂停倒计时";
CM_ SG_ 770 ADS_ParkOutDir_ParaLe_302h "水平向左";
CM_ SG_ 770 ADS_ParkStMac_302h "泊车状态机";
CM_ SG_ 770 APA_ResuAvl_302h "RPA功能是否可以恢复泊车";
CM_ SG_ 770 APA_RPAFctUnavlMsg_1_302h "RPA功能不可用原因1";
CM_ SG_ 770 ADS_ParkOutDir_PerpBack_302h "垂直向后";
CM_ SG_ 770 ADS_ParkOutDir_PerpRiBack_302h "垂直向右后";
CM_ SG_ 770 ADS_ParkOutDir_PerpLeBack_302h "垂直向左后";
CM_ SG_ 770 ADS_ParkOutDir_PerpRiFwd_302h "垂直向右前";
CM_ SG_ 770 ADS_ParkOutDir_PerpLeFwd_302h "垂直向左前";
CM_ SG_ 770 ADS_ParkOutDir_PerpFwd_302h "垂直向前";
CM_ SG_ 770 ADS_ParkOutDir_ParaRi_302h "水平向右";
CM_ SG_ 770 APA_RPAFctUnavlMsg_9_302h "RPA功能不可用原因9";
CM_ SG_ 770 APA_RPAFctUnavlMsg_8_302h "RPA功能不可用原因8";
CM_ SG_ 770 APA_RPAFctUnavlMsg_7_302h "RPA功能不可用原因7";
CM_ SG_ 770 APA_RPAFctUnavlMsg_6_302h "RPA功能不可用原因6";
CM_ SG_ 770 APA_RPAFctUnavlMsg_5_302h "RPA功能不可用原因5";
CM_ SG_ 770 APA_RPAFctUnavlMsg_4_302h "RPA功能不可用原因4";
CM_ SG_ 770 APA_RPAFctUnavlMsg_3_302h "RPA功能不可用原因3";
CM_ SG_ 770 APA_RPAFctUnavlMsg_2_302h "RPA功能不可用原因2";
CM_ SG_ 770 APA_RPAFctUnavlMsg_17_302h "RPA功能不可用原因17";
CM_ SG_ 770 APA_RPAFctUnavlMsg_16_302h "RPA功能不可用原因16";
CM_ SG_ 770 APA_RPAFctUnavlMsg_15_302h "RPA功能不可用原因15";
CM_ SG_ 770 APA_RPAFctUnavlMsg_14_302h "RPA功能不可用原因14";
CM_ SG_ 770 APA_RPAFctUnavlMsg_13_302h "RPA功能不可用原因13";
CM_ SG_ 770 APA_RPAFctUnavlMsg_12_302h "RPA功能不可用原因12";
CM_ SG_ 770 APA_RPAFctUnavlMsg_11_302h "RPA功能不可用原因11";
CM_ SG_ 770 APA_RPAFctUnavlMsg_10_302h "RPA功能不可用原因10";
CM_ SG_ 770 APA_RPAFctUnavlMsg_25_302h "RPA功能不可用原因25";
CM_ SG_ 770 APA_RPAFctUnavlMsg_24_302h "RPA功能不可用原因24";
CM_ SG_ 770 APA_RPAFctUnavlMsg_23_302h "RPA功能不可用原因23";
CM_ SG_ 770 APA_RPAFctUnavlMsg_22_302h "RPA功能不可用原因22";
CM_ SG_ 770 APA_RPAFctUnavlMsg_21_302h "RPA功能不可用原因21";
CM_ SG_ 770 APA_RPAFctUnavlMsg_20_302h "RPA功能不可用原因20";
CM_ SG_ 770 APA_RPAFctUnavlMsg_19_302h "RPA功能不可用原因19";
CM_ SG_ 770 APA_RPAFctUnavlMsg_18_302h "RPA功能不可用原因18";
CM_ SG_ 770 APA_RPACnclMsg_8_302h "RPA功能取消原因8";
CM_ SG_ 770 APA_RPACnclMsg_7_302h "RPA功能取消原因7";
CM_ SG_ 770 APA_RPACnclMsg_6_302h "RPA功能取消原因6";
CM_ SG_ 770 APA_RPACnclMsg_5_302h "RPA功能取消原因5";
CM_ SG_ 770 APA_RPACnclMsg_4_302h "RPA功能取消原因4";
CM_ SG_ 770 APA_RPACnclMsg_3 "RPA功能取消原因3";
CM_ SG_ 770 APA_RPACnclMsg_2_302h "RPA功能取消原因2";
CM_ SG_ 770 APA_RPACnclMsg_1_302h "RPA功能取消原因1";
CM_ SG_ 770 APA_RPACnclMsg_16_302h "RPA功能取消原因16";
CM_ SG_ 770 APA_RPACnclMsg_15_302h "RPA功能取消原因15";
CM_ SG_ 770 APA_RPACnclMsg_14_302h "RPA功能取消原因14";
CM_ SG_ 770 APA_RPACnclMsg_13_302h "RPA功能取消原因13";
CM_ SG_ 770 APA_RPACnclMsg_12_302h "RPA功能取消原因12";
CM_ SG_ 770 APA_RPACnclMsg_11_302h "RPA功能取消原因11";
CM_ SG_ 770 APA_RPACnclMsg_10_302h "RPA功能取消原因10";
CM_ SG_ 770 APA_RPACnclMsg_9_302h "RPA功能取消原因9";
CM_ SG_ 770 APA_RPAPauseMsg_4_302h "RPA功能暂停原因4";
CM_ SG_ 770 APA_RPAPauseMsg_3_302h "RPA功能暂停原因3";
CM_ SG_ 770 APA_RPAPauseMsg_2_302h "RPA功能暂停原因2";
CM_ SG_ 770 APA_RPAPauseMsg_1_302h "RPA功能暂停原因1";
CM_ SG_ 770 APA_RPACnclMsg_20_302h "RPA功能取消原因20";
CM_ SG_ 770 APA_RPACnclMsg_19_302h "RPA功能取消原因19";
CM_ SG_ 770 APA_RPACnclMsg_18_302h "RPA功能取消原因18";
CM_ SG_ 770 APA_RPACnclMsg_17_302h "RPA功能取消原因17";
CM_ SG_ 770 ADS_ParkPosn1_ID_302h "车位1_ID号0~15";
CM_ SG_ 770 APA_RPAPauseMsg_10_302h "RPA功能暂停原因10";
CM_ SG_ 770 APA_RPAPauseMsg_9_302h "RPA功能暂停原因9";
CM_ SG_ 770 APA_RPAPauseMsg_8_302h "RPA功能暂停原因8";
CM_ SG_ 770 APA_RPAPauseMsg_7_302h "RPA功能暂停原因7";
CM_ SG_ 770 APA_RPAPauseMsg_6_302h "RPA功能暂停原因6";
CM_ SG_ 770 APA_RPAPauseMsg_5_302h "RPA功能暂停原因5";
CM_ SG_ 770 ADS_ParkRelPos1_x1_302h "目标车位相对位置1_x1(-50.0~50.0m)";
CM_ SG_ 770 ADS_MnvrOrintChng2_302h "目标车位2类型";
CM_ SG_ 770 ADS_MnvrOrintChng1_302h "目标车位1类型";
CM_ SG_ 770 ADS_ParkRelPos1_y1_302h "目标车位相对位置1_y1(-50.0~50.0m)";
CM_ SG_ 770 ADS_ParkRelPos1_x2_302h "目标车位相对位置1_x2(-50.0~50.0m)";
CM_ SG_ 770 ADS_ParkRelPos1_y2_302h "目标车位相对位置1_y2(-50.0~50.0m)";
CM_ SG_ 770 ADS_ParkRelPos1_x3_302h "目标车位相对位置1_x3(-50.0~50.0m)";
CM_ SG_ 770 ADS_TcsActvSts_302h "TCS激活状态";
CM_ SG_ 770 ADS_VdcActvSts_302h "VDC激活状态";
CM_ SG_ 770 ADS_ParkChkSrc_Posn1_302h "目标车位1检测来源";
CM_ SG_ 770 ADS_TarParkSt_Posn1_302h "目标车位1的状态";
CM_ SG_ 770 ADS_ParkRelPos1_y3_302h "目标车位相对位置1_y3(-50.0~50.0m)";
CM_ SG_ 770 ADS_ParkRelPos1_x4_302h "目标车位相对位置1_x4(-50.0~50.0m)";
CM_ SG_ 770 ADS_ParkRelPos1_y4_302h "目标车位相对位置1_y4(-50.0~50.0m)";
CM_ SG_ 770 ADS_ParkPosn2_ID_302h "车位2_ID号(0~15)";
CM_ SG_ 770 ADS_ParkRelPos2_x1_302h "目标车位相对位置2_x1(-50.0~50.0m)";
CM_ SG_ 770 ADS_ParkRelPos2_y1_302h "目标车位相对位置2_y1(-50.0~50.0m)";
CM_ SG_ 770 ADS_ParkRelPos2_x2_302h "目标车位相对位置2_x2(-50.0~50.0m)";
CM_ SG_ 770 ADS_ParkRelPos2_y2_302h "目标车位相对位置2_y2(-50.0~50.0m)";
CM_ SG_ 770 ADS_ParkRelPos2_x3_302h "目标车位相对位置2_x3(-50.0~50.0m)";
CM_ SG_ 770 ADS_ParkChkSrc_Posn2_302h "目标车位2检测来源";
CM_ SG_ 770 ADS_TarParkSt_Posn2_302h "目标车位2的状态";
CM_ SG_ 770 ADS_ParkRelPos2_y3_302h "目标车位相对位置2_y3(-50.0~50.0m)";
CM_ SG_ 770 ADS_ParkRelPos2_x4_302h "目标车位相对位置2_x4(-50.0~50.0m)";
CM_ SG_ 770 ADS_ParkRelPos2_y4_302h "目标车位相对位置2_y4(-50.0~50.0m)";
CM_ SG_ 771 TimeGapAdjustment_33Dh "HMI在智驾或人驾过程中,显示用户调节的跟车时距";
CM_ SG_ 777 ISGF_ErrLvl "前发电机故障等级Error Level";
CM_ SG_ 787 PassSitPosnSts_313h "FRZCU_FRSitPosnSts
副驾座椅记忆位置反馈";
CM_ SG_ 787 ChrgHoodSts "充电口盖状态反馈
股份FLZCU0x33E发，捷途由FRZCU发";
CM_ SG_ 788 ADS_2_AEBStatus "AEB状态信号
以下为平台化库数据内容
0x0:OFF
0x1:ON
0x2:Failure
0x3:no_active(0x3:available捷途使用)
0x4:active
0x5:pre-fill
0x6 blindness(捷途使用)";
CM_ SG_ 788 ADS_2_FCWStatus "FCW状态信号";
CM_ SG_ 788 FCM_2_IHCfunctionSts "远近光自动切换功能状态";
CM_ SG_ 789 ATCM_DriveModeSw "驾驶模式状态
";
CM_ SG_ 789 ATCM_XModeSw "X模式状态";
CM_ SG_ 789 ATCM_SwitchUTurnModeSet "极限掉头开关/坦克掉头
";
CM_ SG_ 789 ATCM_ASU_LiftSet "悬架升高";
CM_ SG_ 789 ATCM_ASU_LowerSet "悬架降低";
CM_ SG_ 789 ATCM_ESP_OFF_SW "车身稳定控制系统关闭ESP—OFF开关";
CM_ SG_ 789 ATCM_AVH_SW "自动驻车/AVH开关";
CM_ SG_ 789 ATCM_AVM "AVM开关";
CM_ SG_ 794 ADS_3_ICATextinfo "ICA状态信号";
CM_ SG_ 794 ADS_3_ICAStatus "ICA状态信号";
CM_ SG_ 794 ADS_3_DriverHandsoffWarning "驾驶员脱手报警请求";
CM_ SG_ 794 ADS_3_ACCSts "ACC状态信号";
CM_ SG_ 794 ADS_3_LKSSts "LKS状态信号";
CM_ SG_ 794 ADS_3_LKSMod "LDW LDP激活模式状态";
CM_ SG_ 794 ADS_3_LKSRightTrackingSt "LDW LDP右侧车道线激活状态";
CM_ SG_ 794 ADS_3_LKSLeftTrackingSt "LDW LDP左侧车道线激活状态";
CM_ SG_ 794 ADS_3_ELKSts "ELK状态信号";
CM_ SG_ 794 ADS_3_ELKRightActiveSt "ELK右侧车道线激活状态";
CM_ SG_ 794 ADS_3_ELKLeftActiveSt "ELK左侧车道线激活状态";
CM_ SG_ 794 ADS_HNOPSts "高速领航辅助状态";
CM_ SG_ 811 BMS_Chg_Sts_32Bh "充电状态BMS_Chg_Sts";
CM_ BO_ 819 "低配国内FCM发，低配国际FRM发";
CM_ SG_ 819 ADS_4_CRC1 "Profile1A:E2E CRC (SAE J1850 CRC-8) for 8 Bytes
DataID:No ASIL requirements.Not configure
CRC Reserved.";
CM_ SG_ 819 ADS_4_RollgCntr1 "Profile1A:E2E Rolling message counter(the maximum value of Alive counter is 14)";
CM_ SG_ 819 ADS_4_Resd1 "Profile1A:E2E Reserved";
CM_ SG_ 819 ADS_4_AEBReqType "AEB请求类型";
CM_ SG_ 819 ADS_4_AEBStatus "AEB功能状态";
CM_ SG_ 819 ADS_4_ACCSts "ACC功能状态";
CM_ SG_ 819 ADS_4_TimeGapSet "跟车时距";
CM_ SG_ 819 ADS_4_FcwMode "FCW功能状态";
CM_ SG_ 819 ADS_4_SetSpd "巡航车速";
CM_ SG_ 819 ADS_4_DAIStatus "起步提醒功能状态";
CM_ SG_ 819 ADS_4_ACCTextMessage "ACC提示信息";
CM_ SG_ 819 ADS_4_LongiTakeOverReq "接管请求";
CM_ SG_ 819 ADS_4_SetSpdUnit "巡航车速单位";
CM_ SG_ 819 ADS_4_GoNotifier "起步提醒文言";
CM_ SG_ 819 ADS_4_DAISts "起步提醒功能执行状态";
CM_ SG_ 819 ADS_4_Radar_textinfo "雷达提示信息";
CM_ SG_ 819 ADS_4_SCF_PopoverReq "智能限速辅助弹窗提醒";
CM_ SG_ 819 ADS_4_DrvrCfmSCFDispFb "SCF 驾驶员确认信号 （确认后，setspeed变为摄像头限速值）";
CM_ SG_ 819 ADS_4_SCF_SpdLimUnit "智能限速辅助单位";
CM_ SG_ 819 ADS_4_SCF_SpdLimSts "智能限速辅助功能状态";
CM_ SG_ 819 ADS_4_CRC2 "Profile1A:E2E CRC (SAE J1850 CRC-8) for 8 Bytes
DataID:No ASIL requirements.Not configure
CRC Reserved.";
CM_ SG_ 819 ADS_4_RollgCntr2 "Profile1A:E2E Rolling message counter(the maximum value of Alive counter is 14)";
CM_ SG_ 819 ADS_4_Resd2 "Profile1A:E2E Reserved";
CM_ SG_ 819 ADS_4_ACCObjTyp "跟车目标类型";
CM_ SG_ 819 ADS_4_FrntFarObjTyp "前前车目标类型";
CM_ SG_ 819 ADS_4_ACCObjLgtDstX "跟车目标纵向距离";
CM_ SG_ 819 ADS_4_ACCObjHozDstY "跟车目标横向距离";
CM_ SG_ 819 ADS_4_FrntFarObjHozDstY "前前车横向距离";
CM_ SG_ 819 ADS_4_FrntFarObjID "前前车有效性";
CM_ SG_ 819 ADS_4_ACCObjID "跟车目标有效性";
CM_ SG_ 819 ADS_4_FrntFarObjLgtDstX "前前车纵向距离";
CM_ SG_ 819 ADS_4_CRC3 "Profile1A:E2E CRC (SAE J1850 CRC-8) for 8 Bytes
DataID:No ASIL requirements.Not configure
CRC Reserved.";
CM_ SG_ 819 ADS_4_RollgCntr3 "Profile1A:E2E Rolling message counter(the maximum value of Alive counter is 14)";
CM_ SG_ 819 ADS_4_Resd3 "Profile1A:E2E Reserved";
CM_ SG_ 819 ADS_4_LeObjHozDstY "左边车辆横向距离";
CM_ SG_ 819 ADS_4_LeObjID "左边车辆类型有效性";
CM_ SG_ 819 ADS_4_LeObjTyp "左边车辆类型";
CM_ SG_ 819 ADS_4_LeObjLgtDstX "左边车辆纵向距离";
CM_ SG_ 819 ADS_4_RiObjHozDstY "右边车辆横向距离";
CM_ SG_ 819 ADS_4_RiObjID "右边车辆类型有效性";
CM_ SG_ 819 ADS_4_RiObjTyp "右边车辆类型";
CM_ SG_ 819 ADS_4_RiObjLgtDstX "右边车辆纵向距离";
CM_ SG_ 819 ADS_4_CRC4 "Profile1A:E2E CRC (SAE J1850 CRC-8) for 8 Bytes
DataID:No ASIL requirements.Not configure
CRC Reserved.";
CM_ SG_ 819 ADS_4_RollgCntr4 "Profile1A:E2E Rolling message counter(the maximum value of Alive counter is 14)";
CM_ SG_ 819 ADS_4_Resd4 "Profile1A:E2E Reserved";
CM_ SG_ 819 ADS_4_SCFSwtSet "智能限速辅助反馈开关（预留默认开）";
CM_ SG_ 819 ADS_4_AEBSettingSt "AEB功能设置状态反馈";
CM_ SG_ 819 ADS_4_FCWSettingSt "FCW功能设置状态反馈";
CM_ SG_ 819 NOPTextinfo_333h "与仪表交互的NOP文言";
CM_ SG_ 819 ADS_4_CruiseAccelerateSts "巡航跟车加减速状态指示，低配用于HMI显示";
CM_ SG_ 819 ADS_4_DAISwtSet "驶离提醒开关（预留默认开）";
CM_ SG_ 819 FCM_FRM_DAIONOFFSts_333h "驶离提醒软开关反馈";
CM_ SG_ 819 FCTAFCTBONOFFSts_333h "FCTA、FCTB软开关，关、报警、报警＋制动，ADCC反馈给车机";
CM_ SG_ 819 TRA_Operation_Status_333h "循迹倒车功能状态";
CM_ SG_ 819 LightingBlueONOFFSts_333h "辅助驾驶指示灯开启与关闭软开关状态反馈";
CM_ SG_ 819 DataCollectionONOFFStS_333h "数据采集授权开启与关闭的软开关状态反馈";
CM_ SG_ 819 FCM_10_TLITrfcLi_333h "与仪表的红绿灯交互";
CM_ BO_ 821 "高配ADCC发ADS_5_DVR_1_DVR360WorkSts 、ADS_5_DVR_1_DVRFCMWorkSts";
CM_ SG_ 821 ADS_5_CRC1 "Profile1A:E2E CRC (SAE J1850 CRC-8) for 8 Bytes
DataID:No ASIL requirements.Not configure
CRC Reserved.";
CM_ SG_ 821 ADS_5_RollgCntr1 "Profile1A:E2E Rolling message counter(the maximum value of Alive counter is 14)";
CM_ SG_ 821 ADS_5_Resd1 "Profile1A:E2E Reserved";
CM_ SG_ 821 ADS_5_ILOASts "智慧躲闪功能执行状态";
CM_ SG_ 821 ADS_5_ICAQuitReason "ICA 退出原因";
CM_ SG_ 821 ADS_5_ISLISt "超速报警功能状态";
CM_ SG_ 821 ADS_5_ISLISpeedLimitSign "限速标志值";
CM_ SG_ 821 ADS_5_ILOATextInfo "智慧躲闪提示信息";
CM_ SG_ 821 ADS_5_ILOAActdirection "智慧躲闪方向";
CM_ SG_ 821 ADS_5_LKS_warning "LKS声音报警信号";
CM_ SG_ 821 ADS_5_EgoLeftLineHeatgAg "自车中心线与本车道
 车道线的夹角";
CM_ SG_ 821 ADS_5_ISLIOverSpeedWarn "超速报警状态";
CM_ SG_ 821 ADS_5_EgoLeLineHozlDst "自车中心线与本车道左侧车道线横向距离";
CM_ SG_ 821 ADS_5_EgoLeLineID "左侧车道线有效信号";
CM_ SG_ 821 ADS_5_EgoLeLineColor "本车道左侧车道线颜色";
CM_ SG_ 821 ADS_5_EgoLeLineTyp "本车道左侧车道线类型";
CM_ SG_ 821 ADS_5_CRC2 "Profile1A:E2E CRC (SAE J1850 CRC-8) for 8 Bytes
DataID:No ASIL requirements.Not configure
CRC Reserved.";
CM_ SG_ 821 ADS_5_RollgCntr2 "Profile1A:E2E Rolling message counter(the maximum value of Alive counter is 14)";
CM_ SG_ 821 ADS_5_Resd2 "Profile1A:E2E Reserved";
CM_ SG_ 821 ADS_5_EgoLeLineCrvt "本车道左侧车道线曲率";
CM_ SG_ 821 ADS_5_NeborLeLineHozlDst "自车中心线与左侧相邻车 
 道线横向距离";
CM_ SG_ 821 ADS_5_NeborLeLineID "左侧相邻车道线有效信号";
CM_ SG_ 821 ADS_5_NeborLeLineColor "左侧相邻车道线颜色";
CM_ SG_ 821 ADS_5_NeborLeLineTyp "左侧相邻车道线类型";
CM_ SG_ 821 ADS_5_NeborLeLineCrvt "左侧相邻车道线曲率";
CM_ SG_ 821 ADS_5_NeborRiLineHozlDst "自车中心线与右侧相邻车 
 道线横向距离";
CM_ SG_ 821 ADS_5_NeborRiLineID "右侧相邻车道线有效信号";
CM_ SG_ 821 ADS_5_NeborRiLineColor "右侧相邻车道线颜色";
CM_ SG_ 821 ADS_5_NeborRiLineTyp "右侧相邻车道线类型";
CM_ SG_ 821 ADS_5_CRC3 "Profile1A:E2E CRC (SAE J1850 CRC-8) for 8 Bytes
DataID:No ASIL requirements.Not configure
CRC Reserved.";
CM_ SG_ 821 ADS_5_RollgCntr3 "Profile1A:E2E Rolling message counter(the maximum value of Alive counter is 14)";
CM_ SG_ 821 ADS_5_Resd3 "Profile1A:E2E Reserved";
CM_ SG_ 821 ADS_5_NeborRiLineCrvt "右侧相邻车道线曲率";
CM_ SG_ 821 ADS_5_ELKSettingSt "ELK功能设置状态反馈";
CM_ SG_ 821 ADS_5_LDWLDPSnvtySet "车道偏离敏感度反馈";
CM_ SG_ 821 ADS_5_LDWWarnType "LDW/LDP报警方式反馈";
CM_ SG_ 821 ADS_5_IESSwtSet "智慧躲闪反馈开关（预留默认开）";
CM_ SG_ 821 ADS_5_IHCSettingSt "智能远光辅助开关反馈";
CM_ SG_ 821 ADS_5_ISLIWarningMod "智能限速提醒方式反馈";
CM_ SG_ 821 ADS_5_ICAEnableBtnSts "ICA功能使能开关反馈（车道居中辅助）";
CM_ SG_ 821 ADS_5_EgoRiLineTyp "本车道右侧车道线类型";
CM_ SG_ 821 ADS_5_EgoRiLineHozlDst "自车中心线与本车道右侧车道线横向距离";
CM_ SG_ 821 ADS_5_EgoRiLineColor "本车道右侧车道线颜色";
CM_ SG_ 821 ADS_5_EgoRiLineID "右侧车道线有效信号";
CM_ SG_ 821 ADS_5_CRC4 "Profile1A:E2E CRC (SAE J1850 CRC-8) for 8 Bytes
DataID:No ASIL requirements.Not configure
CRC Reserved.";
CM_ SG_ 821 ADS_5_RollgCntr4 "Profile1A:E2E Rolling message counter(the maximum value of Alive counter is 14)";
CM_ SG_ 821 ADS_5_Resd4 "Profile1A:E2E Reserved";
CM_ SG_ 821 ADS_5_EgoRightLineHeatgAg "自车中心线与本车道右侧车道线的夹角";
CM_ SG_ 821 ADS_5_EgoRiLineCrvt "本车道右侧车道线曲率";
CM_ SG_ 821 ADS_5_NeborLeftLineHeatgAg "自车中心线与相邻车道左侧车道线的夹角";
CM_ SG_ 821 ADS_5_NeborRightLineHeatgAg "自车中心线与相邻车道右侧车道线的夹角";
CM_ SG_ 850 ASU_6_HMIFailFb_JT "0x0:无状态，不显示
0x1:悬架调节已锁定，请先解除锁定
0x2:尾门未关闭，载物模式已退出
0x3:悬架高度调节已禁用
0x4:悬架软硬调节已禁用
0x5:当前海拔过高，悬架高度调节已禁用
0x6~0xF:reserved";
CM_ BO_ 917 "灯光秀模式信号";
CM_ SG_ 917 RandomMusicShowCMD "RandomMusic";
CM_ SG_ 917 DIYMusicShowmod "DIYMusicShow";
CM_ SG_ 917 MusicLoudness_55HZ "The corresponding audio loudness when the sampling point music frequency is 
55HZ
Note:
      1.When DVD don't display music , DVD send this signal value 0x1F
       2.Within a cycle time, If DVD don't acquire this frequency, DVD send this signal value 0x1F";
CM_ SG_ 917 LiShowMod "LightShowMode";
CM_ SG_ 917 MusicLoudness_262HZ "The corresponding audio loudness when the sampling point music frequency is 262HZ
Note:
      1.When DVD don't display music , DVD send this signal value 0x1F
       2.Within a cycle time, If DVD don't acquire this frequency, DVD send this signal value 0x1F";
CM_ SG_ 917 MusicLoudness_123HZ "The corresponding audio loudness when the sampling point music frequency is 123HZ
Note:
      1.When DVD don't display music , DVD send this signal value 0x1F
       2.Within a cycle time, If DVD don't acquire this frequency, DVD send this signal value 0x1F";
CM_ SG_ 917 MusicLoudness_587HZ "The corresponding audio loudness when the sampling point music frequency is 587HZ
Note:
      1.When DVD don't display music , DVD send this signal value 0x1F
       2.Within a cycle time, If DVD don't acquire this frequency, DVD send this signal value 0x1F";
CM_ SG_ 917 MusicLoudness_440HZ "The corresponding audio loudness when the sampling point music frequency is 440HZ
Note:
      1.When DVD don't display music , DVD send this signal value 0x1F
       2.Within a cycle time, If DVD don't acquire this frequency, DVD send this signal value 0x1F";
CM_ SG_ 917 MusicLoudness_784HZ "The corresponding audio loudness when the sampling point music frequency is 784HZ
Note:
      1.When DVD don't display music , DVD send this signal value 0x1F
       2.Within a cycle time, If DVD don't acquire this frequency, DVD send this signal value 0x1F";
CM_ SG_ 917 MusicLoudness_2794HZ "The corresponding audio loudness when the sampling point music frequency is 2794HZ
Note:
      1.When DVD don't display music , DVD send this signal value 0x1F
       2.Within a cycle time, If DVD don't acquire this frequency, DVD send this signal value 0x1F";
CM_ SG_ 917 MusicLoudness_1318HZ "The corresponding audio loudness when the sampling point music frequency is 1318HZ
Note:
      1.When DVD don't display music , DVD send this signal value 0x1F
       2.Within a cycle time, If DVD don't acquire this frequency, DVD send this signal value 0x1F";
CM_ SG_ 917 MusicLoudness_6272HZ "The corresponding audio loudness when the sampling point music frequency is 6272HZ
Note:
      1.When DVD don't display music , DVD send this signal value 0x1F
       2.Within a cycle time, If DVD don't acquire this frequency, DVD send this signal value 0x1F";
CM_ SG_ 917 ISDShowCMD "ISD灯光开启,同一个模式若想反复播放，需要先";
CM_ SG_ 917 ISDShowMode "ISD灯光模式";
CM_ BO_ 943 "D01P使用";
CM_ SG_ 943 CSA_3_CRC1 "Profile1A:E2E CRC (SAE J1850 CRC-8) for 8 Bytes
DataID:Reserved";
CM_ SG_ 943 CSA_3_RollgCntr1 "Profile1A:E2E Rolling message counter(the maximum value of Alive counter is 14)";
CM_ SG_ 943 CSA_3_Resd1 "Profile1A:E2E Reserved";
CM_ SG_ 943 FlwheelBearing "持续发送左前轮载荷值(吨)";
CM_ SG_ 943 FrwheelBearing "持续发送右前轮载荷值(吨)";
CM_ SG_ 943 BlwheelBearing "持续发送左后轮载荷值(吨)";
CM_ SG_ 943 BrwheelBearing "持续发送右后轮载荷值(吨)";
CM_ SG_ 943 CSA_3_CRC2 "Profile1A:E2E CRC (SAE J1850 CRC-8) for 8 Bytes
DataID:Reserved";
CM_ SG_ 943 CSA_3_RollgCntr2 "Profile1A:E2E Rolling message counter(the maximum value of Alive counter is 14)";
CM_ SG_ 943 VehicleBearing_kg "持续发送整车重量(kg)";
CM_ SG_ 943 VehicleBearing_lb "持续发送整车重量(lb)";
CM_ SG_ 943 GoodsWeight_kg "持续发送货物重量(kg)";
CM_ SG_ 943 Goods_Weight_Ratio "持续发送货物重量百分比(%)";
CM_ SG_ 943 CSA_3_CRC3 "Profile1A:E2E CRC (SAE J1850 CRC-8) for 8 Bytes
DataID:Reserved";
CM_ SG_ 943 CSA_3_RollgCntr3 "Profile1A:E2E Rolling message counter(the maximum value of Alive counter is 14)";
CM_ SG_ 943 CSA_3_Resd3 "Profile1A:E2E Reserved";
CM_ SG_ 943 GoodsWeight_lb "持续发送货物重量(lb)";
CM_ SG_ 943 OverWeightValue_kg "持续发送超重值（kg)";
CM_ SG_ 943 OverWeightValue_lb "持续发送超重值（lb)";
CM_ SG_ 943 OverLoadWarnShieldSetFed "大屏重量报警屏蔽软开关反馈信号";
CM_ SG_ 943 OverWeightWarning "超重时发送超重报警信号";
CM_ SG_ 943 OverWeightRatio "持续发送超重百公比(%)";
CM_ SG_ 943 Fraxlebearingrate "前轴荷重比";
CM_ BO_ 949 "捷途新增";
CM_ SG_ 949 PEPS_OrderInformation "PEPS do not add any additional logic. Just reflect the status of the switch state.";
CM_ SG_ 949 PEPS_InformationSource "To show the lock/unlock information is from Smart or RKE .";
CM_ SG_ 949 PEPS_KeySts "PEPS钥匙位置状态";
CM_ SG_ 949 PEPS_ETRUnLockReq "尾门靠近解锁请求";
CM_ BO_ 991 "VCU测试报文";
CM_ SG_ 991 TMS_BatteryLoopErrorLevel "Battery_Loop_Error_Level
电池回路故障等级";
CM_ SG_ 991 TMS_MotorLoopErrorLevel "Motor_Loop_Error_Level
电驱回路故障等级";
CM_ SG_ 1018 FLZCU_DraggingModeRemind_3FAh "拖挂模式功能提示
0x0: 无提示
0x1:禁用ECO和越野模式
0x2:拖挂模式下仅支持Normal和Sport
0x3:ECO和越野模式恢复
0x4~0x7：预留";
CM_ SG_ 1018 FLZCU_KeyDriveModememory_3FAh "驾驶模式记忆开关反馈";
CM_ SG_ 1018 FLZCU_DriveMode_3FAh "驾驶模式反馈
0x0：无效值
0x1：经济
0x2：标准
0x3：运动
0x4: 雪地
0x5: 越野
0x6: xxx
0x7: 混动节能模式
0x8: 沙地
0x9: 智能
0xA: 涉水
0xB: 岩石
0xC: 泥地
0xD: X模式
0xE: 预留
0xF~0x1F：预留";
CM_ SG_ 1018 FLZCU_CCO_TextDisp_3FAh "CCO功能提示信息
越野蠕行功能提示";
CM_ SG_ 1018 FLZCU_CCOSwtReq_3FAh "越野蠕行CCO功能请求";
CM_ SG_ 1018 FLZCU_DriveModeChangeFail_3FAh "驾驶模式切换不满足条件，提示“请停车后退出当前驾驶模式”";
CM_ BO_ 1020 "拆帧ID捷途";
CM_ SG_ 1020 SAM_1_SteeringAngleSpeed "方向盘转角角速度";
CM_ SG_ 1020 SAM_1_SteeringAngle "方向盘转角角度值";
CM_ SG_ 1020 BMSH_MaxChgPwrPeak "Maximum Charge Power Peak
拆帧至IC CAN 0x3FC（bit52）";
CM_ SG_ 1020 BMSH_MaxDchgPwrPeak "Maximum Discharge Power Peak
拆帧至IC CAN 0x3FC（bit56）";
CM_ SG_ 1020 FMCU_8_ISGF_SpdAct "前发电机实际转速
ISG motor actual speed
拆帧至IC CAN0x3FC(bit72)";
CM_ SG_ 1020 RMCU_1_Speed "后驱动电机转速RMCU motor actual speed
拆针至IC CAN 0x3FC (bit88)";
CM_ SG_ 1020 SAM_1_SteeringAngleVD "角度有效性";
CM_ SG_ 1020 SAM_1_SteeringAngleSpeedVD "角速度有效性";
CM_ SG_ 1020 CSA_2_AllWarningInfo "EGS全部报警信号
T1C项目，EGS此信号发0x0、0x1、0x4，仪表接收";
CM_ SG_ 1020 RMCU_1_TCURErrLvlDis "TCUR故障等级
拆帧转发至IC CAN 0x3FC(bit125)";
CM_ SG_ 1020 ASU_2_sensorErrorSts "Sensor Error Status.";
CM_ SG_ 1020 ASU_2_LFHeight "Height of front left wheel.";
CM_ SG_ 1020 ASU_2_RFHeight "Height of front right wheel.";
CM_ SG_ 1020 ASU_2_LRHeight "Height of rear left wheel.";
CM_ SG_ 1020 ASU_2_RRHeight "Height of rear right wheel.";
CM_ SG_ 1020 CSA_2_WiprFrntCmd "Wiper front command for CSA..";
CM_ SG_ 1020 EVCC_GunConnectSt_203h "充电枪连接状态
0-未连接
1-已连接
2-连接异常";
CM_ SG_ 1020 STAT_ShifterLeverFault "Shift sensor fault status";
CM_ SG_ 1022 FLZCU_MedStatusFb "冥想模式状态反馈";
CM_ SG_ 1022 FLZCU_SteerWhlposSts "管柱电机运行状态
0x0:不工作
0x1:伸长调节中
0x2:缩短调节中
0x3:角度上调中
0x4:角度下调中";
CM_ SG_ 1022 FLZCU_CarMode "整车模式";
CM_ SG_ 1022 FLZCU_MedAreaFb "冥想模式开启区域设置反馈";
CM_ SG_ 1022 FLZCU_MedFailCause "冥想模式开启失败 原因反馈
0x0:Not Active 
0x1:档位非P 档 
0x2:车速≠0km/h 
0x3:前舱盖未关 
0x4:后背门未关 
0x5:左前门未关 
0x6:右前门未关 
0x7:左后门未关 
0x8:右后门未关 
0x9:低压电池电压低，不满足开启条件 
0xA:高压电池电量低，不满足开启条件 
0xB:制动踏板被踩下，不满足开启条件
0xC:电源档位非Comfortable档，不满足开启条件(新增)";
CM_ SG_ 1022 DrvSecSeatLvltargetCmd_3FEh "小憩模式主驾二排前后设置
0x0:Not active";
CM_ SG_ 1022 FLZCU_NapArea2Fb "小憩模式开启区域2设置反馈";
CM_ SG_ 1022 FLZCU_MedClosePrompt "冥想模式关闭提示信号
0x0:Not Active
0x1:低压电池电量低，关闭冥想模式 
0x2:高压电池电量低，关闭冥想模式";
CM_ SG_ 1022 DrvSecSeatBackAgCmd_3FEh "小憩模式主驾二排靠背设置
0x0:Not active";
CM_ SG_ 1022 DrvSecSeatLegSpprtCmd_3FEh "小憩模式主驾二排腿托设置
0x0:Not active";
CM_ SG_ 1022 FLZCU_LogoChargingSts "前LOGO充电灯效开关状态反馈";
CM_ SG_ 1022 FLZCU_MonoAmbLigSts "单色氛围灯状态";
CM_ SG_ 1022 DrvRearWinThermalStatus_3FEh "主驾后车窗热保护状态
0：未触发热保护
1：热保护触发中";
CM_ SG_ 1022 DrvWinThermalStatus_3FEh "主驾车窗热保护状态
0：未触发热保护
1：热保护触发中";
CM_ SG_ 1022 PassRearSeatBackAgCmd_3FEh "小憩模式副驾二排靠背设置
0x0:Not active";
CM_ SG_ 1022 PassRearSeatLvltargetCmd_3FEh "小憩模式副驾二排前后设置
0x0:Not active";
CM_ SG_ 1022 PassRearSeatLegSpprtCmd_3FEh "小憩模式副驾二排腿托设置
0x0:Not active";
CM_ SG_ 1022 DrvSitPosnSts_3FEh "主驾座椅记忆位置反馈（含后视镜、管柱）
车机座椅记忆页面有三个位置显示，需新增该信号";
CM_ SG_ 1022 DrvRearSeatVentLvl2_3FEh "二排主驾侧座椅通风状态--捷途使用
9档通风给TBOX和ICC";
CM_ SG_ 1022 DrvSeatVentLvl2_3FEh "主驾座椅通风状态--捷途使用
9档通风给TBOX和ICC";
CM_ SG_ 1022 DrvRearSeatHeatLvl2_3FEh "二排主驾侧座椅加热状态--捷途使用
9档加热给TBOX和ICC";
CM_ SG_ 1022 DrvSeatHeatLvl2_3FEh "主驾座椅加热状态--捷途使用
9档加热给TBOX和ICC";
CM_ SG_ 1022 FLZCU_DrvExpSeatSts_3FEh "主驾座椅避让展开/复位完成状态";
CM_ SG_ 1022 FLZCU_FLogolightInhibitSts "前LOGO灯禁止状态（D01P增加 高法规地区不允许亮）";
CM_ SG_ 1022 FLZCU_SteerOverHeatWarn "管柱热保护提醒";
CM_ SG_ 1024 CSunshadePercentSts "天幕遮阳帘开度百分比状态";
CM_ SG_ 1024 CSunshadeSts "天幕遮阳帘实际状态
(大屏动效-可显示开启和关闭的动画)";
CM_ SG_ 1024 PassSeatVentLvl2_400h "FRZCU_SeatVentLvlFR2
副驾座椅通风状态--捷途使用";
CM_ SG_ 1024 PassSeatHeatLvl2_400h "FRZCU_SeatHeatLvlFR2
副驾座椅加热状态--捷途使用";
CM_ SG_ 1024 PassSecSeatHeatLvl2_400h "FRZCU_SeatHeatLvlRR2
副驾二排座椅加热状态--捷途使用";
CM_ SG_ 1024 PassSecSeatVentLvl2_400h "FRZCU_SeatVentLvlRR2
副驾二排座椅通风状态--捷途使用";
CM_ SG_ 1024 FRZCU_OnekeyHVoffSwtst "紧急下电开关状态反馈（法规要求，执行下高压，低压不变）";
CM_ SG_ 1024 FRZCU_CSunshadeThermalSts "天幕遮阳帘热保护状态
0：未触发热保护
1：热保护触发中";
CM_ SG_ 1024 PassRearWinThermalSts_400h "FRZCU_RRWinThermalSts
副驾后车窗热保护状态
0：未触发热保护
1：热保护触发中";
CM_ SG_ 1024 PassWinThermalSts_400h "FRZCU_FRWinThermalSts
副驾车窗热保护状态
0：未触发热保护
1：热保护触发中";
CM_ SG_ 1024 FRZCU_ContainerlightSts "货箱灯状态反馈";
CM_ SG_ 1024 FRZCU_ADSLightSts "智驾小蓝灯开关状态
ADS进行相关的车模显示";
CM_ SG_ 1024 FRZCU_QueenSeatEnterSts "女王副驾进入状态反馈
0x1:调节中
0x2:调节成功（女王模式进入成功）
0x3:调节失败（女王模式进入失败";
CM_ SG_ 1024 FRZCU_PasgerSeatMovFailCause "副驾调节失败原因
0x1：座椅未学习
0x2：触发防夹
0x3：硬开关未释放
0x4：副驾处于折叠状态
0x5：电机线路故障（开路、短路、霍尔丢失）
0x6：优先级不满足";
CM_ SG_ 1024 FRZCU_ADSLightFltSts "智驾小蓝灯故障状态
ADS故障显示";
CM_ SG_ 1024 FRZCU_QueenSeatPosSts "副驾真实位置状态反馈
0x0:不处于女王副驾位置
0x1:处于女王副驾位置";
CM_ SG_ 1024 FRZCU_QueenSeatSts "女王副驾状态反馈
0x0:无请求
0x1:已退出
0x2:已进入";
CM_ SG_ 1024 FRZCU_QueenSeatMovFailCause "女王副驾调节失败原因
0x1：座椅未学习
0x2：触发防夹
0x3：硬开关未释放
0x4：副驾处于折叠状态
0x5：电机线路故障（开路、短路、霍尔丢失）
0x6：优先级不满足
0x7：二排已展开
0x8:二排右侧座椅被占用
0x9：二排被打断";
CM_ SG_ 1024 CSunshadeLearnedSts "遮阳帘学习状态，学习中大屏开关不可用";
CM_ SG_ 1024 CSunshadePosn "遮阳帘开度";
BA_DEF_ SG_  "GenSigASIL" ENUM  "QM","A","B","C","D","vector_leerstring";
BA_DEF_ BU_  "NmStationAddress" INT 0 63;
BA_DEF_ BU_  "NmAsrCanMsgReducedTime" INT 500 818;
BA_DEF_  "NmAsrWaitBusSleepTime" INT 0 65535;
BA_DEF_  "NmAsrBaseAddress" HEX 0 2047;
BA_DEF_  "NmAsrCanMsgCycleTime" INT 0 65535;
BA_DEF_  "NmAsrMessageCount" INT 0 128;
BA_DEF_  "NmAsrRepeatMessageTime" INT 0 65535;
BA_DEF_  "NmAsrTimeoutTime" INT 0 65535;
BA_DEF_  "NmType" STRING ;
BA_DEF_ BU_  "ILused" ENUM  "No","Yes";
BA_DEF_ BU_  "NmNode" ENUM  "No","Yes";
BA_DEF_ BU_  "NodeLayerModules" STRING ;
BA_DEF_  "Baudrate" INT 0 1000000;
BA_DEF_  "BaudrateCANFD" INT 1000000 10000000;
BA_DEF_  "BusType" STRING ;
BA_DEF_  "DBName" STRING ;
BA_DEF_  "NmBaseAddress" HEX 1536 1663;
BA_DEF_  "NmMessageCount" INT 0 255;
BA_DEF_  "ProtocolType" STRING ;
BA_DEF_ SG_  "ASIL" ENUM  "QM","A","B","C","D";
BA_DEF_ SG_  "E2EDataLength" INT 0 65535;
BA_DEF_ SG_  "GenSigInactiveValue" HEX 0 80000000;
BA_DEF_ SG_  "GenSigInvalidValue" HEX 0 281474976710655;
BA_DEF_ SG_  "GenSigStartValue" HEX 0 80000000;
BA_DEF_ SG_  "GenSigSendType" ENUM  "Cyclic","OnWrite","OnWriteWithRepetition","OnChange","OnChangeWithRepetition","IfActive","IfActiveWithRepetition","NoSigSendType";
BA_DEF_ BO_  "CANFD_BRS" ENUM  "0","1";
BA_DEF_ BO_  "DiagUudtResponse" ENUM  "True","False";
BA_DEF_ BO_  "GenMsgCycleTime" INT 0 65535;
BA_DEF_ BO_  "GenMsgCycleTimeFast" INT 0 65535;
BA_DEF_ BO_  "GenMsgDelayTime" INT 0 65535;
BA_DEF_ BO_  "GenMsgILSupport" ENUM  "No","Yes";
BA_DEF_ BO_  "GenMsgNrOfRepetition" INT 0 255;
BA_DEF_ BO_  "GenMsgSendType" ENUM  "Cyclic","Event","IfActive","CE","CA","NoMsgSendType";
BA_DEF_ BO_  "NmAsrMessage" ENUM  "No","Yes";
BA_DEF_ BO_  "NmMessage" ENUM  "No","Yes";
BA_DEF_ BO_  "SCP_AuthInfoTxLength" INT 9 512;
BA_DEF_ BO_  "SCP_FreshnessValueLength" INT 0 512;
BA_DEF_ BO_  "SCP_FreshnessValueTxLength" INT 0 512;
BA_DEF_ BO_  "VFrameFormat" ENUM  "StandardCAN","ExtendedCAN","reserved","J1939PG","reserved","reserved","reserved","reserved","reserved","reserved","reserved","reserved","reserved","reserved","StandardCAN_FD","ExtendedCAN_FD";
BA_DEF_DEF_  "GenSigASIL" "QM";
BA_DEF_DEF_  "NmStationAddress" 0;
BA_DEF_DEF_  "NmAsrCanMsgReducedTime" 500;
BA_DEF_DEF_  "NmAsrWaitBusSleepTime" 1500;
BA_DEF_DEF_  "NmAsrBaseAddress" 1536;
BA_DEF_DEF_  "NmAsrCanMsgCycleTime" 1000;
BA_DEF_DEF_  "NmAsrMessageCount" 128;
BA_DEF_DEF_  "NmAsrRepeatMessageTime" 3000;
BA_DEF_DEF_  "NmAsrTimeoutTime" 2500;
BA_DEF_DEF_  "NmType" "NmAsr";
BA_DEF_DEF_  "ILused" "Yes";
BA_DEF_DEF_  "NmNode" "No";
BA_DEF_DEF_  "NodeLayerModules" "CANoeILNLSPA.dll";
BA_DEF_DEF_  "Baudrate" 500000;
BA_DEF_DEF_  "BaudrateCANFD" 2000000;
BA_DEF_DEF_  "BusType" "CAN";
BA_DEF_DEF_  "DBName" "CAN";
BA_DEF_DEF_  "NmBaseAddress" 1536;
BA_DEF_DEF_  "NmMessageCount" 128;
BA_DEF_DEF_  "ProtocolType" "CAN";
BA_DEF_DEF_  "ASIL" "QM";
BA_DEF_DEF_  "E2EDataLength" 64;
BA_DEF_DEF_  "GenSigInactiveValue" 0;
BA_DEF_DEF_  "GenSigInvalidValue" 0;
BA_DEF_DEF_  "GenSigStartValue" 0;
BA_DEF_DEF_  "GenSigSendType" "NoSigSendType";
BA_DEF_DEF_  "CANFD_BRS" "1";
BA_DEF_DEF_  "DiagUudtResponse" "True";
BA_DEF_DEF_  "GenMsgCycleTime" 0;
BA_DEF_DEF_  "GenMsgCycleTimeFast" 0;
BA_DEF_DEF_  "GenMsgDelayTime" 0;
BA_DEF_DEF_  "GenMsgILSupport" "Yes";
BA_DEF_DEF_  "GenMsgNrOfRepetition" 0;
BA_DEF_DEF_  "GenMsgSendType" "Cyclic";
BA_DEF_DEF_  "NmAsrMessage" "No";
BA_DEF_DEF_  "NmMessage" "No";
BA_DEF_DEF_  "SCP_AuthInfoTxLength" 28;
BA_DEF_DEF_  "SCP_FreshnessValueLength" 48;
BA_DEF_DEF_  "SCP_FreshnessValueTxLength" 4;
BA_DEF_DEF_  "VFrameFormat" "J1939PG";
BA_ "BusType" "CAN FD";
BA_ "DBName" "D01D01PMessageList_ICCANFD_";
BA_ "ILused" BU_ AVAS 0;
BA_ "ILused" BU_ BBCM 0;
BA_ "ILused" BU_ CMSM 0;
BA_ "ILused" BU_ DVR 0;
BA_ "ILused" BU_ EAMP 0;
BA_ "ILused" BU_ EPC 0;
BA_ "ILused" BU_ FLZCU 0;
BA_ "ILused" BU_ ICC 0;
BA_ "NmStationAddress" BU_ ICC 24;
BA_ "NmNode" BU_ ICC 1;
BA_ "ILused" BU_ PCL 0;
BA_ "ILused" BU_ PLG 0;
BA_ "ILused" BU_ SBOX 0;
BA_ "ILused" BU_ SCU 0;
BA_ "GenMsgCycleTime" BO_ 33 10;
BA_ "VFrameFormat" BO_ 33 14;
BA_ "GenMsgCycleTime" BO_ 49 10;
BA_ "VFrameFormat" BO_ 49 14;
BA_ "GenMsgCycleTime" BO_ 258 10;
BA_ "VFrameFormat" BO_ 258 14;
BA_ "GenMsgCycleTime" BO_ 259 10;
BA_ "VFrameFormat" BO_ 259 14;
BA_ "GenMsgCycleTime" BO_ 290 10;
BA_ "VFrameFormat" BO_ 290 14;
BA_ "GenMsgCycleTime" BO_ 513 20;
BA_ "VFrameFormat" BO_ 513 14;
BA_ "GenMsgCycleTime" BO_ 514 20;
BA_ "VFrameFormat" BO_ 514 14;
BA_ "GenMsgCycleTime" BO_ 517 20;
BA_ "VFrameFormat" BO_ 517 14;
BA_ "GenMsgCycleTime" BO_ 524 20;
BA_ "VFrameFormat" BO_ 524 14;
BA_ "GenMsgCycleTime" BO_ 571 20;
BA_ "VFrameFormat" BO_ 571 14;
BA_ "GenMsgCycleTime" BO_ 572 20;
BA_ "VFrameFormat" BO_ 572 14;
BA_ "GenMsgCycleTime" BO_ 587 20;
BA_ "VFrameFormat" BO_ 587 14;
BA_ "GenMsgCycleTime" BO_ 612 20;
BA_ "VFrameFormat" BO_ 612 14;
BA_ "GenMsgCycleTime" BO_ 632 50;
BA_ "VFrameFormat" BO_ 632 14;
BA_ "GenMsgCycleTime" BO_ 638 20;
BA_ "VFrameFormat" BO_ 638 14;
BA_ "GenMsgCycleTime" BO_ 644 20;
BA_ "VFrameFormat" BO_ 644 14;
BA_ "GenMsgCycleTime" BO_ 683 20;
BA_ "VFrameFormat" BO_ 683 14;
BA_ "GenMsgCycleTime" BO_ 699 20;
BA_ "VFrameFormat" BO_ 699 14;
BA_ "GenMsgCycleTime" BO_ 769 50;
BA_ "VFrameFormat" BO_ 769 14;
BA_ "GenMsgCycleTime" BO_ 770 50;
BA_ "VFrameFormat" BO_ 770 14;
BA_ "GenMsgCycleTime" BO_ 771 50;
BA_ "VFrameFormat" BO_ 771 14;
BA_ "GenMsgCycleTime" BO_ 777 500;
BA_ "VFrameFormat" BO_ 777 14;
BA_ "GenMsgCycleTime" BO_ 783 50;
BA_ "VFrameFormat" BO_ 783 14;
BA_ "GenMsgCycleTime" BO_ 787 50;
BA_ "VFrameFormat" BO_ 787 14;
BA_ "GenMsgCycleTime" BO_ 788 50;
BA_ "VFrameFormat" BO_ 788 14;
BA_ "GenMsgNrOfRepetition" BO_ 789 3;
BA_ "GenMsgDelayTime" BO_ 789 5;
BA_ "GenMsgCycleTimeFast" BO_ 789 20;
BA_ "GenMsgSendType" BO_ 789 1;
BA_ "VFrameFormat" BO_ 789 14;
BA_ "GenMsgCycleTime" BO_ 794 50;
BA_ "VFrameFormat" BO_ 794 14;
BA_ "GenMsgCycleTime" BO_ 811 50;
BA_ "VFrameFormat" BO_ 811 14;
BA_ "GenMsgCycleTime" BO_ 819 50;
BA_ "VFrameFormat" BO_ 819 14;
BA_ "GenMsgCycleTime" BO_ 821 50;
BA_ "VFrameFormat" BO_ 821 14;
BA_ "GenMsgCycleTime" BO_ 850 50;
BA_ "VFrameFormat" BO_ 850 14;
BA_ "GenMsgCycleTime" BO_ 859 50;
BA_ "VFrameFormat" BO_ 859 14;
BA_ "GenMsgCycleTime" BO_ 917 50;
BA_ "VFrameFormat" BO_ 917 14;
BA_ "GenMsgCycleTime" BO_ 943 50;
BA_ "VFrameFormat" BO_ 943 14;
BA_ "GenMsgNrOfRepetition" BO_ 949 3;
BA_ "GenMsgCycleTime" BO_ 949 50;
BA_ "GenMsgDelayTime" BO_ 949 5;
BA_ "GenMsgCycleTimeFast" BO_ 949 50;
BA_ "GenMsgSendType" BO_ 949 3;
BA_ "VFrameFormat" BO_ 949 14;
BA_ "GenMsgCycleTime" BO_ 991 50;
BA_ "VFrameFormat" BO_ 991 14;
BA_ "GenMsgCycleTime" BO_ 1018 100;
BA_ "VFrameFormat" BO_ 1018 14;
BA_ "GenMsgCycleTime" BO_ 1020 100;
BA_ "VFrameFormat" BO_ 1020 14;
BA_ "GenMsgCycleTime" BO_ 1022 100;
BA_ "VFrameFormat" BO_ 1022 14;
BA_ "GenMsgCycleTime" BO_ 1024 100;
BA_ "VFrameFormat" BO_ 1024 14;
BA_ "GenSigInvalidValue" SG_ 33 ACU_3_LongitudinalAcceleration 65535;
BA_ "GenSigStartValue" SG_ 33 ACU_3_LongitudinalAcceleration 2000;
BA_ "ASIL" SG_ 33 ACU_3_LongitudinalAcceleration 2;
BA_ "GenSigSendType" SG_ 33 ACU_3_LongitudinalAcceleration 0;
BA_ "GenSigStartValue" SG_ 33 ACU_3_LongitudinalAccelerationVD 3;
BA_ "ASIL" SG_ 33 ACU_3_LongitudinalAccelerationVD 2;
BA_ "GenSigSendType" SG_ 33 ACU_3_LongitudinalAccelerationVD 0;
BA_ "ASIL" SG_ 33 ACU_3_CrashOutputSts 2;
BA_ "GenSigSendType" SG_ 33 ACU_3_CrashOutputSts 0;
BA_ "GenSigInvalidValue" SG_ 49 ACU_2_LateralAcceleration 65535;
BA_ "GenSigStartValue" SG_ 49 ACU_2_LateralAcceleration 2000;
BA_ "ASIL" SG_ 49 ACU_2_LateralAcceleration 2;
BA_ "GenSigSendType" SG_ 49 ACU_2_LateralAcceleration 0;
BA_ "GenSigInvalidValue" SG_ 49 ACU_2_YawRate 65535;
BA_ "GenSigStartValue" SG_ 49 ACU_2_YawRate 18000;
BA_ "ASIL" SG_ 49 ACU_2_YawRate 2;
BA_ "GenSigSendType" SG_ 49 ACU_2_YawRate 0;
BA_ "GenSigStartValue" SG_ 49 ACU_2_YawrateSigValidData 3;
BA_ "ASIL" SG_ 49 ACU_2_YawrateSigValidData 2;
BA_ "GenSigSendType" SG_ 49 ACU_2_YawrateSigValidData 0;
BA_ "GenSigStartValue" SG_ 49 ACU_2_LateralAccelerationSigVD 3;
BA_ "ASIL" SG_ 49 ACU_2_LateralAccelerationSigVD 2;
BA_ "GenSigSendType" SG_ 49 ACU_2_LateralAccelerationSigVD 0;
BA_ "GenSigSendType" SG_ 258 BMS_1_CRC1 0;
BA_ "GenSigSendType" SG_ 258 BMS_1_RollgCntr1 0;
BA_ "GenSigSendType" SG_ 258 BMS_1_Resd1 0;
BA_ "GenSigInvalidValue" SG_ 258 BMS_PackVoltage 65535;
BA_ "GenSigStartValue" SG_ 258 BMS_PackVoltage 65535;
BA_ "GenSigSendType" SG_ 258 BMS_PackVoltage 0;
BA_ "GenSigInvalidValue" SG_ 258 BMS_PackCurrent 65535;
BA_ "GenSigStartValue" SG_ 258 BMS_PackCurrent 65535;
BA_ "GenSigSendType" SG_ 258 BMS_PackCurrent 0;
BA_ "GenSigSendType" SG_ 258 BMS_HvBattSts 0;
BA_ "GenSigSendType" SG_ 258 BMS_SysSelfCheck 0;
BA_ "GenSigInvalidValue" SG_ 258 BMS_HVBattThermRunaway 2;
BA_ "GenSigSendType" SG_ 258 BMS_HVBattThermRunaway 0;
BA_ "GenSigSendType" SG_ 258 BMS_1_CRC2 0;
BA_ "GenSigSendType" SG_ 258 BMS_1_RollgCntr2 0;
BA_ "GenSigSendType" SG_ 258 BMS_1_Resd2 0;
BA_ "GenSigStartValue" SG_ 258 BMS_ChargeVoltageReq 16382;
BA_ "GenSigSendType" SG_ 258 BMS_ChargeVoltageReq 0;
BA_ "GenSigStartValue" SG_ 258 BMS_ChgCurrReq 16382;
BA_ "GenSigSendType" SG_ 258 BMS_ChgCurrReq 0;
BA_ "GenSigStartValue" SG_ 258 BMS_InfraDcUActDc 16382;
BA_ "GenSigSendType" SG_ 258 BMS_InfraDcUActDc 0;
BA_ "GenSigSendType" SG_ 258 BMS_1_CRC3 0;
BA_ "GenSigSendType" SG_ 258 BMS_1_RollgCntr3 0;
BA_ "GenSigSendType" SG_ 258 BMS_1_Resd3 0;
BA_ "GenSigStartValue" SG_ 258 BMS_InfraDcIActDc 16382;
BA_ "GenSigSendType" SG_ 258 BMS_InfraDcIActDc 0;
BA_ "GenSigStartValue" SG_ 258 BMS_HvBattDynChrgnILim 16382;
BA_ "GenSigSendType" SG_ 258 BMS_HvBattDynChrgnILim 0;
BA_ "GenSigStartValue" SG_ 258 BMS_HvBattUChrgnLim 16382;
BA_ "GenSigSendType" SG_ 258 BMS_HvBattUChrgnLim 0;
BA_ "GenSigSendType" SG_ 258 BMS_1_CRC4 0;
BA_ "GenSigSendType" SG_ 258 BMS_1_RollgCntr4 0;
BA_ "GenSigSendType" SG_ 258 BMS_1_Resd4 0;
BA_ "GenSigStartValue" SG_ 258 BMS_ChrgDcIAvl 16382;
BA_ "GenSigSendType" SG_ 258 BMS_ChrgDcIAvl 0;
BA_ "GenSigSendType" SG_ 258 BMS_DChrgAPlusSt 0;
BA_ "GenSigSendType" SG_ 258 BMS_Insulation_R 0;
BA_ "GenSigSendType" SG_ 258 BMS_ChrgDcCnctrDetd 0;
BA_ "GenSigSendType" SG_ 258 BMS_DCChgMode 0;
BA_ "GenSigSendType" SG_ 258 BMS_ChrgDcChrgnFltStopReas 0;
BA_ "GenSigSendType" SG_ 258 BMS_1_CRC5 0;
BA_ "GenSigSendType" SG_ 258 BMS_1_RollgCntr5 0;
BA_ "GenSigSendType" SG_ 258 BMS_1_Resd5 0;
BA_ "GenSigStartValue" SG_ 258 BMS_ChgRemTime 2047;
BA_ "GenSigSendType" SG_ 258 BMS_ChgRemTime 0;
BA_ "GenSigStartValue" SG_ 258 BMS_ChargeRequest_Mode 15;
BA_ "GenSigSendType" SG_ 258 BMS_ChargeRequest_Mode 0;
BA_ "GenSigInvalidValue" SG_ 258 BMS_1_StateOfChargeDis 255;
BA_ "GenSigStartValue" SG_ 258 BMS_1_StateOfChargeDis 255;
BA_ "GenSigSendType" SG_ 258 BMS_1_StateOfChargeDis 0;
BA_ "GenSigInvalidValue" SG_ 258 BMS_StateOfEnergy 65535;
BA_ "GenSigStartValue" SG_ 258 BMS_StateOfEnergy 65535;
BA_ "GenSigSendType" SG_ 258 BMS_StateOfEnergy 0;
BA_ "GenSigSendType" SG_ 258 BMS_1_CRC6 0;
BA_ "GenSigSendType" SG_ 258 BMS_1_RollgCntr6 0;
BA_ "GenSigSendType" SG_ 258 BMS_1_Resd6 0;
BA_ "GenSigSendType" SG_ 258 BMS_StateOfHealth 0;
BA_ "GenSigSendType" SG_ 258 BMS_BlanceState 0;
BA_ "GenSigSendType" SG_ 258 BMS_IsolationFault 0;
BA_ "GenSigSendType" SG_ 258 BMS_HVILFault_DC 0;
BA_ "GenSigSendType" SG_ 258 BMS_HVILFault_FMCU 0;
BA_ "GenSigSendType" SG_ 258 BMS_HVILFault_RMCU 0;
BA_ "GenSigInvalidValue" SG_ 258 BMS_SOCDis 16383;
BA_ "GenSigStartValue" SG_ 258 BMS_SOCDis 16383;
BA_ "GenSigSendType" SG_ 258 BMS_SOCDis 0;
BA_ "GenSigStartValue" SG_ 258 BMS_InfraDcIActDcMin 16383;
BA_ "GenSigSendType" SG_ 258 BMS_InfraDcIActDcMin 0;
BA_ "GenSigInvalidValue" SG_ 259 EMS_EngineSpeed_Actual 65535;
BA_ "GenSigSendType" SG_ 259 EMS_EngineSpeed_Actual 0;
BA_ "GenSigSendType" SG_ 290 EPS_1_CRC 0;
BA_ "GenSigSendType" SG_ 290 EPS_1_RollgCntr 0;
BA_ "ASIL" SG_ 290 EPSFailSts 2;
BA_ "GenSigSendType" SG_ 290 EPSFailSts 0;
BA_ "GenSigSendType" SG_ 290 EPSSteeringAngleCalibrationSts 0;
BA_ "GenSigSendType" SG_ 290 EPS_EOTLearning_Sts 0;
BA_ "ASIL" SG_ 513 MFSL_UP_SW 2;
BA_ "GenSigSendType" SG_ 513 MFSL_UP_SW 0;
BA_ "ASIL" SG_ 513 MFSL_DW_SW 2;
BA_ "GenSigSendType" SG_ 513 MFSL_DW_SW 0;
BA_ "ASIL" SG_ 513 MFSL_Left_SW 2;
BA_ "GenSigSendType" SG_ 513 MFSL_Left_SW 0;
BA_ "ASIL" SG_ 513 MFSL_Right_SW 2;
BA_ "GenSigSendType" SG_ 513 MFSL_Right_SW 0;
BA_ "GenSigSendType" SG_ 513 MFSL_OK_SW 0;
BA_ "GenSigSendType" SG_ 513 MFSL_AVM_SW 0;
BA_ "GenSigSendType" SG_ 513 MFSL_Customize 0;
BA_ "GenSigSendType" SG_ 513 MFSL_APA_SW 0;
BA_ "GenSigSendType" SG_ 513 MFSL_LCC_NCA_SW 0;
BA_ "GenSigSendType" SG_ 514 New_Signal_202_2 0;
BA_ "GenSigSendType" SG_ 514 New_Signal_202_1 0;
BA_ "GenSigSendType" SG_ 514 ADS_CRC1_202h 0;
BA_ "GenSigSendType" SG_ 514 ADS_RollgCntr1_202h 0;
BA_ "GenSigSendType" SG_ 514 ADS_Resd1_202h 0;
BA_ "GenSigSendType" SG_ 514 ADS_NicaReminderAcoustic_202h 0;
BA_ "ASIL" SG_ 514 ADS_NicaReminderLEDVisual_202h 2;
BA_ "GenSigSendType" SG_ 514 ADS_NicaReminderLEDVisual_202h 0;
BA_ "ASIL" SG_ 514 ADS_AdsFault_202h 2;
BA_ "GenSigSendType" SG_ 514 ADS_AdsFault_202h 0;
BA_ "GenSigSendType" SG_ 514 ADS_TakeoverID_202h 0;
BA_ "GenSigSendType" SG_ 514 ADS_TakeoverType_202h 0;
BA_ "GenSigSendType" SG_ 514 ADS_TakeoverLevel_202h 0;
BA_ "GenSigSendType" SG_ 514 ADS_TORIDCorrespErrorID_202h 0;
BA_ "GenSigSendType" SG_ 514 ADS_TakeoverExtended16bit_202h 0;
BA_ "GenSigSendType" SG_ 514 ADS_TakeoverExtended8bit_202h 0;
BA_ "GenSigSendType" SG_ 517 MFSR_UP_SW 0;
BA_ "GenSigSendType" SG_ 517 MFSR_DW_SW 0;
BA_ "GenSigSendType" SG_ 517 MFSR_Left_SW 0;
BA_ "GenSigSendType" SG_ 517 MFSR_Right_SW 0;
BA_ "GenSigSendType" SG_ 517 MFSR_OK_SW 0;
BA_ "GenSigSendType" SG_ 517 MFSR_MENU_SW 0;
BA_ "GenSigSendType" SG_ 517 MFSR_Voice_SW 0;
BA_ "GenSigSendType" SG_ 517 MFSR_Customize 0;
BA_ "GenSigSendType" SG_ 524 ADS_6_Customize_buttonsFB 0;
BA_ "ASIL" SG_ 571 LHTurnlightSts 2;
BA_ "GenSigSendType" SG_ 571 LHTurnlightSts 0;
BA_ "ASIL" SG_ 571 RHTurnlightSts 2;
BA_ "GenSigSendType" SG_ 571 RHTurnlightSts 0;
BA_ "ASIL" SG_ 571 DrvDoorSts_23Bh 1;
BA_ "GenSigSendType" SG_ 571 DrvDoorSts_23Bh 0;
BA_ "GenSigStartValue" SG_ 571 DrvDoorLockSts_23Bh 3;
BA_ "ASIL" SG_ 571 DrvDoorLockSts_23Bh 1;
BA_ "GenSigSendType" SG_ 571 DrvDoorLockSts_23Bh 0;
BA_ "GenSigSendType" SG_ 571 LHTurnSW 0;
BA_ "GenSigSendType" SG_ 571 RHTurnSW 0;
BA_ "GenSigSendType" SG_ 571 HazardLightSW 0;
BA_ "ASIL" SG_ 571 DrvSeatBeltSW_23Bh 1;
BA_ "GenSigSendType" SG_ 571 DrvSeatBeltSW_23Bh 0;
BA_ "ASIL" SG_ 571 DirectionIndLeft 2;
BA_ "GenSigSendType" SG_ 571 DirectionIndLeft 0;
BA_ "ASIL" SG_ 571 DirectionIndRight 2;
BA_ "GenSigSendType" SG_ 571 DirectionIndRight 0;
BA_ "GenSigSendType" SG_ 572 ONEBOX_7_TAB_HighTemp 0;
BA_ "GenSigSendType" SG_ 572 ONEBOX_7_TAB_Active 0;
BA_ "GenSigSendType" SG_ 572 ONEBOX_7_BSW_Active 0;
BA_ "GenSigSendType" SG_ 572 ONEBOX_7_iCCO_Active 0;
BA_ "GenSigSendType" SG_ 572 ONEBOX_7_iCCO_TgtVel 0;
BA_ "GenSigInvalidValue" SG_ 587 ONEBOX_4_LHFWheelSpeedRPM 65535;
BA_ "ASIL" SG_ 587 ONEBOX_4_LHFWheelSpeedRPM 4;
BA_ "GenSigSendType" SG_ 587 ONEBOX_4_LHFWheelSpeedRPM 0;
BA_ "GenSigInvalidValue" SG_ 587 ONEBOX_4_RHFWheelSpeedRPM 65535;
BA_ "ASIL" SG_ 587 ONEBOX_4_RHFWheelSpeedRPM 4;
BA_ "GenSigSendType" SG_ 587 ONEBOX_4_RHFWheelSpeedRPM 0;
BA_ "GenSigInvalidValue" SG_ 587 LHRWheelSpeedRPM 65535;
BA_ "ASIL" SG_ 587 LHRWheelSpeedRPM 2;
BA_ "GenSigSendType" SG_ 587 LHRWheelSpeedRPM 0;
BA_ "GenSigInvalidValue" SG_ 587 RHRWheelSpeedRPM 65535;
BA_ "ASIL" SG_ 587 RHRWheelSpeedRPM 2;
BA_ "GenSigSendType" SG_ 587 RHRWheelSpeedRPM 0;
BA_ "ASIL" SG_ 587 LHRPulseCounter 2;
BA_ "GenSigSendType" SG_ 587 LHRPulseCounter 0;
BA_ "ASIL" SG_ 587 LHRPulseCounterFailSts 2;
BA_ "GenSigSendType" SG_ 587 LHRPulseCounterFailSts 0;
BA_ "ASIL" SG_ 587 RHRPulseCounter 2;
BA_ "GenSigSendType" SG_ 587 RHRPulseCounter 0;
BA_ "ASIL" SG_ 587 RHRPulseCounterFailSts 2;
BA_ "GenSigSendType" SG_ 587 RHRPulseCounterFailSts 0;
BA_ "ASIL" SG_ 587 RHFPulseCounter 2;
BA_ "GenSigSendType" SG_ 587 RHFPulseCounter 0;
BA_ "ASIL" SG_ 587 RHFPulseCounterFailSts 2;
BA_ "GenSigSendType" SG_ 587 RHFPulseCounterFailSts 0;
BA_ "ASIL" SG_ 587 LHFPulseCounter 2;
BA_ "GenSigSendType" SG_ 587 LHFPulseCounter 0;
BA_ "ASIL" SG_ 587 LHFPulseCounterFailSts 2;
BA_ "GenSigSendType" SG_ 587 LHFPulseCounterFailSts 0;
BA_ "GenSigInvalidValue" SG_ 587 LHFWheelDriveDirection 4;
BA_ "ASIL" SG_ 587 LHFWheelDriveDirection 2;
BA_ "GenSigSendType" SG_ 587 LHFWheelDriveDirection 0;
BA_ "GenSigInvalidValue" SG_ 587 RHFWheelDriveDirection 4;
BA_ "ASIL" SG_ 587 RHFWheelDriveDirection 2;
BA_ "GenSigSendType" SG_ 587 RHFWheelDriveDirection 0;
BA_ "GenSigInvalidValue" SG_ 587 LHRWheelDriveDirection 4;
BA_ "ASIL" SG_ 587 LHRWheelDriveDirection 2;
BA_ "GenSigSendType" SG_ 587 LHRWheelDriveDirection 0;
BA_ "GenSigInvalidValue" SG_ 587 RHRWheelDriveDirection 4;
BA_ "ASIL" SG_ 587 RHRWheelDriveDirection 2;
BA_ "GenSigSendType" SG_ 587 RHRWheelDriveDirection 0;
BA_ "ASIL" SG_ 587 IPB_SandABSAvl_24Bh 2;
BA_ "GenSigSendType" SG_ 587 IPB_SandABSAvl_24Bh 0;
BA_ "ASIL" SG_ 587 IPB_SandABSSwSts_24Bh 2;
BA_ "GenSigSendType" SG_ 587 IPB_SandABSSwSts_24Bh 0;
BA_ "GenSigSendType" SG_ 612 New_Signal_264_5 0;
BA_ "GenSigSendType" SG_ 612 New_Signal_264_4 0;
BA_ "GenSigSendType" SG_ 612 New_Signal_264_3 0;
BA_ "GenSigSendType" SG_ 612 New_Signal_264_2 0;
BA_ "GenSigSendType" SG_ 612 New_Signal_264_1 0;
BA_ "GenSigSendType" SG_ 612 CRC1_264h 0;
BA_ "GenSigSendType" SG_ 612 RollgCntr1_264h 0;
BA_ "GenSigSendType" SG_ 612 EPBAUTO_Status_264h 0;
BA_ "GenSigSendType" SG_ 612 FltLamp_264h 0;
BA_ "GenSigSendType" SG_ 612 ParkLamp_264h 0;
BA_ "GenSigSendType" SG_ 612 ActrSt_264h 0;
BA_ "GenSigSendType" SG_ 612 RWUSt_264h 0;
BA_ "ASIL" SG_ 612 TextDisp_264h 2;
BA_ "GenSigSendType" SG_ 612 TextDisp_264h 0;
BA_ "GenSigSendType" SG_ 612 IPB_EPBErrorStatus 0;
BA_ "GenSigInvalidValue" SG_ 632 EngineCoolantTemperature 255;
BA_ "GenSigStartValue" SG_ 632 EngineCoolantTemperature 91;
BA_ "GenSigSendType" SG_ 632 EngineCoolantTemperature 0;
BA_ "ASIL" SG_ 638 FRZCU_HoodSts 1;
BA_ "GenSigSendType" SG_ 638 FRZCU_HoodSts 0;
BA_ "GenSigSendType" SG_ 638 FRZCU_AuthenResult 0;
BA_ "GenSigSendType" SG_ 638 FRZCU_TrunkSts 0;
BA_ "GenSigSendType" SG_ 638 DrvHandleSwitchSts_27Eh 0;
BA_ "GenSigSendType" SG_ 638 PassHandleSwitchSts_27Eh 0;
BA_ "GenSigSendType" SG_ 638 PassRearHandleSwitchSts_27Eh 0;
BA_ "GenSigSendType" SG_ 638 DrvRearHandleSwitchSts_27Eh 0;
BA_ "GenSigSendType" SG_ 638 SeatLength_target_Passenger 0;
BA_ "GenSigStartValue" SG_ 638 FRZCU_TrunkLockSts 3;
BA_ "GenSigSendType" SG_ 638 FRZCU_TrunkLockSts 0;
BA_ "GenSigSendType" SG_ 638 SeatBackrest_target_Passenger 0;
BA_ "GenSigSendType" SG_ 638 FRZCU_GloveboxSW 0;
BA_ "GenSigInvalidValue" SG_ 638 FrontBackSpeedAdj_Cmd 7;
BA_ "GenSigSendType" SG_ 638 FrontBackSpeedAdj_Cmd 0;
BA_ "GenSigStartValue" SG_ 638 FRZCU_HoodLockSts 3;
BA_ "GenSigSendType" SG_ 638 FRZCU_HoodLockSts 0;
BA_ "GenSigSendType" SG_ 638 FRZCU_PELockInKeyWarning 0;
BA_ "GenSigSendType" SG_ 638 PassRearReleaseLockSts_27Eh 0;
BA_ "GenSigSendType" SG_ 638 PassReleaseLockSts_27Eh 0;
BA_ "GenSigSendType" SG_ 638 FRZCU_OTAPwrDwnReqFb 0;
BA_ "GenSigSendType" SG_ 638 FRZCU_KeylessWarning 0;
BA_ "GenSigSendType" SG_ 638 FRZCU_PowerOFFWarning 0;
BA_ "GenSigSendType" SG_ 638 FRZCU_OTAPwrOnReqFb 0;
BA_ "GenSigSendType" SG_ 644 ICM_5_FuelLevel_284h 0;
BA_ "GenSigSendType" SG_ 644 FuelShortGround 0;
BA_ "GenSigSendType" SG_ 644 FuelShortPower 0;
BA_ "GenSigSendType" SG_ 644 FuelOutOfRange 0;
BA_ "GenSigSendType" SG_ 644 FuelValidData 0;
BA_ "ASIL" SG_ 683 PassDoorSts_2ABh 1;
BA_ "GenSigSendType" SG_ 683 PassDoorSts_2ABh 0;
BA_ "GenSigSendType" SG_ 683 ParkLightSts 0;
BA_ "GenSigInvalidValue" SG_ 683 PassWinPosn_2ABh 127;
BA_ "GenSigStartValue" SG_ 683 PassWinPosn_2ABh 127;
BA_ "GenSigSendType" SG_ 683 PassWinPosn_2ABh 0;
BA_ "GenSigInvalidValue" SG_ 683 PassRearWinPosn_2ABh 127;
BA_ "GenSigStartValue" SG_ 683 PassRearWinPosn_2ABh 127;
BA_ "GenSigSendType" SG_ 683 PassRearWinPosn_2ABh 0;
BA_ "ASIL" SG_ 683 PassRearDoorSts_2ABh 1;
BA_ "GenSigSendType" SG_ 683 PassRearDoorSts_2ABh 0;
BA_ "GenSigSendType" SG_ 699 DrvRearDoorSts_2BBh 0;
BA_ "GenSigSendType" SG_ 769 ADS_LccNcaFunctionStatus_301h 0;
BA_ "GenSigSendType" SG_ 769 ADS_AccFunctionStatus_301h 0;
BA_ "GenSigSendType" SG_ 769 ADS_AvpFunctionStatus_301h 0;
BA_ "GenSigSendType" SG_ 769 ADS_AdsFucntionNotActive_301h 0;
BA_ "GenSigSendType" SG_ 769 ADS_SpeedSetByDriver_301h 0;
BA_ "GenSigSendType" SG_ 769 ADS_SpeedLimitValue_301h 0;
BA_ "GenSigSendType" SG_ 769 ADS_OneTouchSpeedAdjustment_301h 0;
BA_ "GenSigSendType" SG_ 769 ADS_SpeedAutoFollow_301h 0;
BA_ "GenSigSendType" SG_ 769 ADS_HODReminder_301h 0;
BA_ "GenSigSendType" SG_ 769 ADS_CalibState_301h 0;
BA_ "GenSigSendType" SG_ 769 ADS_FcwFault_301h 0;
BA_ "GenSigSendType" SG_ 769 ADS_FcwWaning_301h 0;
BA_ "GenSigSendType" SG_ 769 ADS_DMSReminder_301h 0;
BA_ "GenSigSendType" SG_ 769 ADS_AebObjType_301h 0;
BA_ "GenSigSendType" SG_ 769 ADS_AebFault_301h 0;
BA_ "GenSigSendType" SG_ 769 ADS_AebWaning_301h 0;
BA_ "GenSigSendType" SG_ 769 ADS_RcwWarning_301h 0;
BA_ "GenSigSendType" SG_ 769 ADS_RaebFault_301h 0;
BA_ "GenSigSendType" SG_ 769 ADS_RaebWarning_301h 0;
BA_ "GenSigSendType" SG_ 769 ADS_FctaRightWarning_301h 0;
BA_ "GenSigSendType" SG_ 769 ADS_FctaLeftWarning_301h 0;
BA_ "GenSigSendType" SG_ 769 ADS_RcwFault_301h 0;
BA_ "GenSigSendType" SG_ 769 ADS_FctbRightWarning_301h 0;
BA_ "GenSigSendType" SG_ 769 ADS_FctbLeftWarning_301h 0;
BA_ "GenSigSendType" SG_ 769 ADS_RctaFault_301h 0;
BA_ "GenSigSendType" SG_ 769 ADS_RctaRightWarning_301h 0;
BA_ "GenSigSendType" SG_ 769 ADS_RctaLeftWarning_301h 0;
BA_ "GenSigSendType" SG_ 769 ADS_LdwWarning_301h 0;
BA_ "GenSigSendType" SG_ 769 ADS_RctbRightWarning_301h 0;
BA_ "GenSigSendType" SG_ 769 ADS_RctbLeftWarning_301h 0;
BA_ "GenSigSendType" SG_ 769 ADS_LkaFault_301h 0;
BA_ "GenSigSendType" SG_ 769 ADS_LKAWarning_301h 0;
BA_ "GenSigSendType" SG_ 769 ADS_LdwFault_301h 0;
BA_ "GenSigSendType" SG_ 769 ADS_BsdFault_301h 0;
BA_ "GenSigSendType" SG_ 769 ADS_RightMirrWarningCmd_301h 0;
BA_ "GenSigSendType" SG_ 769 ADS_LeftMirrWarningCmd_301h 0;
BA_ "GenSigSendType" SG_ 769 ADS_RiFrntDoorWarningCmd_301h 0;
BA_ "GenSigSendType" SG_ 769 ADS_LeReDoorWarningCmd_301h 0;
BA_ "GenSigSendType" SG_ 769 ADS_LeFrntDoorWarningCmd_301h 0;
BA_ "GenSigSendType" SG_ 769 ADS_SpeedLimitWarning_301h 0;
BA_ "GenSigSendType" SG_ 769 ADS_DowFault_301h 0;
BA_ "GenSigSendType" SG_ 769 ADS_RiReDoorWarningCmd_301h 0;
BA_ "GenSigSendType" SG_ 769 ADS_ElkaFault_301h 0;
BA_ "GenSigSendType" SG_ 769 ADS_TlaFault_301h 0;
BA_ "GenSigSendType" SG_ 769 ADS_TsrFault_301h 0;
BA_ "GenSigSendType" SG_ 769 ADS_AbsoultwSpeedLimit_301h 0;
BA_ "GenSigSendType" SG_ 769 ADS_ElkaWarning_301h 0;
BA_ "GenSigSendType" SG_ 769 ADS_TlaWarning_301h 0;
BA_ "GenSigSendType" SG_ 770 ADS_RPAOnlineOrNot_302h 0;
BA_ "GenSigInvalidValue" SG_ 770 ADS_VehParkMod_302h 3;
BA_ "GenSigSendType" SG_ 770 ADS_VehParkMod_302h 0;
BA_ "GenSigInvalidValue" SG_ 770 ADS_SeldParkID_302h 11;
BA_ "GenSigSendType" SG_ 770 ADS_SeldParkID_302h 0;
BA_ "GenSigSendType" SG_ 770 ADS_RpaParkAuthn_302h 0;
BA_ "GenSigSendType" SG_ 770 ADS_ParkProgs_302h 0;
BA_ "GenSigInvalidValue" SG_ 770 ADS_ParkDirCfm_302h 8;
BA_ "GenSigSendType" SG_ 770 ADS_ParkDirCfm_302h 0;
BA_ "GenSigSendType" SG_ 770 ADS_RemParkPatSel_302h 0;
BA_ "GenSigSendType" SG_ 770 ADS_ParkRmngDst_302h 0;
BA_ "GenSigSendType" SG_ 770 ADS_ObstclDst_302h 0;
BA_ "GenSigSendType" SG_ 770 ADS_AutEve_302h 0;
BA_ "GenSigSendType" SG_ 770 ADS_parkInterruptDuration_302h 0;
BA_ "GenSigSendType" SG_ 770 ADS_ParkOutDir_ParaLe_302h 0;
BA_ "GenSigSendType" SG_ 770 ADS_ParkStMac_302h 0;
BA_ "GenSigSendType" SG_ 770 APA_ResuAvl_302h 0;
BA_ "GenSigSendType" SG_ 770 APA_RPAFctUnavlMsg_1_302h 0;
BA_ "GenSigSendType" SG_ 770 ADS_ParkOutDir_PerpBack_302h 0;
BA_ "GenSigSendType" SG_ 770 ADS_ParkOutDir_PerpRiBack_302h 0;
BA_ "GenSigSendType" SG_ 770 ADS_ParkOutDir_PerpLeBack_302h 0;
BA_ "GenSigSendType" SG_ 770 ADS_ParkOutDir_PerpRiFwd_302h 0;
BA_ "GenSigSendType" SG_ 770 ADS_ParkOutDir_PerpLeFwd_302h 0;
BA_ "GenSigSendType" SG_ 770 ADS_ParkOutDir_PerpFwd_302h 0;
BA_ "GenSigSendType" SG_ 770 ADS_ParkOutDir_ParaRi_302h 0;
BA_ "GenSigSendType" SG_ 770 APA_RPAFctUnavlMsg_9_302h 0;
BA_ "GenSigSendType" SG_ 770 APA_RPAFctUnavlMsg_8_302h 0;
BA_ "GenSigSendType" SG_ 770 APA_RPAFctUnavlMsg_7_302h 0;
BA_ "GenSigSendType" SG_ 770 APA_RPAFctUnavlMsg_6_302h 0;
BA_ "GenSigSendType" SG_ 770 APA_RPAFctUnavlMsg_5_302h 0;
BA_ "GenSigSendType" SG_ 770 APA_RPAFctUnavlMsg_4_302h 0;
BA_ "GenSigSendType" SG_ 770 APA_RPAFctUnavlMsg_3_302h 0;
BA_ "GenSigSendType" SG_ 770 APA_RPAFctUnavlMsg_2_302h 0;
BA_ "GenSigSendType" SG_ 770 APA_RPAFctUnavlMsg_17_302h 0;
BA_ "GenSigSendType" SG_ 770 APA_RPAFctUnavlMsg_16_302h 0;
BA_ "GenSigSendType" SG_ 770 APA_RPAFctUnavlMsg_15_302h 0;
BA_ "GenSigSendType" SG_ 770 APA_RPAFctUnavlMsg_14_302h 0;
BA_ "GenSigSendType" SG_ 770 APA_RPAFctUnavlMsg_13_302h 0;
BA_ "GenSigSendType" SG_ 770 APA_RPAFctUnavlMsg_12_302h 0;
BA_ "GenSigSendType" SG_ 770 APA_RPAFctUnavlMsg_11_302h 0;
BA_ "GenSigSendType" SG_ 770 APA_RPAFctUnavlMsg_10_302h 0;
BA_ "GenSigSendType" SG_ 770 APA_RPAFctUnavlMsg_25_302h 0;
BA_ "GenSigSendType" SG_ 770 APA_RPAFctUnavlMsg_24_302h 0;
BA_ "GenSigSendType" SG_ 770 APA_RPAFctUnavlMsg_23_302h 0;
BA_ "GenSigSendType" SG_ 770 APA_RPAFctUnavlMsg_22_302h 0;
BA_ "GenSigSendType" SG_ 770 APA_RPAFctUnavlMsg_21_302h 0;
BA_ "GenSigSendType" SG_ 770 APA_RPAFctUnavlMsg_20_302h 0;
BA_ "GenSigSendType" SG_ 770 APA_RPAFctUnavlMsg_19_302h 0;
BA_ "GenSigSendType" SG_ 770 APA_RPAFctUnavlMsg_18_302h 0;
BA_ "GenSigSendType" SG_ 770 APA_RPACnclMsg_8_302h 0;
BA_ "GenSigSendType" SG_ 770 APA_RPACnclMsg_7_302h 0;
BA_ "GenSigSendType" SG_ 770 APA_RPACnclMsg_6_302h 0;
BA_ "GenSigSendType" SG_ 770 APA_RPACnclMsg_5_302h 0;
BA_ "GenSigSendType" SG_ 770 APA_RPACnclMsg_4_302h 0;
BA_ "GenSigSendType" SG_ 770 APA_RPACnclMsg_3 0;
BA_ "GenSigSendType" SG_ 770 APA_RPACnclMsg_2_302h 0;
BA_ "GenSigSendType" SG_ 770 APA_RPACnclMsg_1_302h 0;
BA_ "GenSigSendType" SG_ 770 APA_RPACnclMsg_16_302h 0;
BA_ "GenSigSendType" SG_ 770 APA_RPACnclMsg_15_302h 0;
BA_ "GenSigSendType" SG_ 770 APA_RPACnclMsg_14_302h 0;
BA_ "GenSigSendType" SG_ 770 APA_RPACnclMsg_13_302h 0;
BA_ "GenSigSendType" SG_ 770 APA_RPACnclMsg_12_302h 0;
BA_ "GenSigSendType" SG_ 770 APA_RPACnclMsg_11_302h 0;
BA_ "GenSigSendType" SG_ 770 APA_RPACnclMsg_10_302h 0;
BA_ "GenSigSendType" SG_ 770 APA_RPACnclMsg_9_302h 0;
BA_ "GenSigSendType" SG_ 770 APA_RPAPauseMsg_4_302h 0;
BA_ "GenSigSendType" SG_ 770 APA_RPAPauseMsg_3_302h 0;
BA_ "GenSigSendType" SG_ 770 APA_RPAPauseMsg_2_302h 0;
BA_ "GenSigSendType" SG_ 770 APA_RPAPauseMsg_1_302h 0;
BA_ "GenSigSendType" SG_ 770 APA_RPACnclMsg_20_302h 0;
BA_ "GenSigSendType" SG_ 770 APA_RPACnclMsg_19_302h 0;
BA_ "GenSigSendType" SG_ 770 APA_RPACnclMsg_18_302h 0;
BA_ "GenSigSendType" SG_ 770 APA_RPACnclMsg_17_302h 0;
BA_ "GenSigSendType" SG_ 770 ADS_ParkPosn1_ID_302h 0;
BA_ "GenSigSendType" SG_ 770 APA_RPAPauseMsg_10_302h 0;
BA_ "GenSigSendType" SG_ 770 APA_RPAPauseMsg_9_302h 0;
BA_ "GenSigSendType" SG_ 770 APA_RPAPauseMsg_8_302h 0;
BA_ "GenSigSendType" SG_ 770 APA_RPAPauseMsg_7_302h 0;
BA_ "GenSigSendType" SG_ 770 APA_RPAPauseMsg_6_302h 0;
BA_ "GenSigSendType" SG_ 770 APA_RPAPauseMsg_5_302h 0;
BA_ "GenSigSendType" SG_ 770 ADS_ParkRelPos1_x1_302h 0;
BA_ "GenSigSendType" SG_ 770 ADS_MnvrOrintChng2_302h 0;
BA_ "GenSigSendType" SG_ 770 ADS_MnvrOrintChng1_302h 0;
BA_ "GenSigSendType" SG_ 770 ADS_ParkRelPos1_y1_302h 0;
BA_ "GenSigSendType" SG_ 770 ADS_ParkRelPos1_x2_302h 0;
BA_ "GenSigSendType" SG_ 770 ADS_ParkRelPos1_y2_302h 0;
BA_ "GenSigSendType" SG_ 770 ADS_ParkRelPos1_x3_302h 0;
BA_ "GenSigSendType" SG_ 770 ADS_TcsActvSts_302h 0;
BA_ "GenSigSendType" SG_ 770 ADS_VdcActvSts_302h 0;
BA_ "GenSigSendType" SG_ 770 ADS_ParkChkSrc_Posn1_302h 0;
BA_ "GenSigSendType" SG_ 770 ADS_TarParkSt_Posn1_302h 0;
BA_ "GenSigSendType" SG_ 770 ADS_ParkRelPos1_y3_302h 0;
BA_ "GenSigSendType" SG_ 770 ADS_ParkRelPos1_x4_302h 0;
BA_ "GenSigSendType" SG_ 770 ADS_ParkRelPos1_y4_302h 0;
BA_ "GenSigSendType" SG_ 770 ADS_ParkPosn2_ID_302h 0;
BA_ "GenSigSendType" SG_ 770 ADS_ParkRelPos2_x1_302h 0;
BA_ "GenSigSendType" SG_ 770 ADS_ParkRelPos2_y1_302h 0;
BA_ "GenSigSendType" SG_ 770 ADS_ParkRelPos2_x2_302h 0;
BA_ "GenSigSendType" SG_ 770 ADS_ParkRelPos2_y2_302h 0;
BA_ "GenSigSendType" SG_ 770 ADS_ParkRelPos2_x3_302h 0;
BA_ "GenSigSendType" SG_ 770 ADS_ParkChkSrc_Posn2_302h 0;
BA_ "GenSigSendType" SG_ 770 ADS_TarParkSt_Posn2_302h 0;
BA_ "GenSigSendType" SG_ 770 ADS_ParkRelPos2_y3_302h 0;
BA_ "GenSigSendType" SG_ 770 ADS_ParkRelPos2_x4_302h 0;
BA_ "GenSigSendType" SG_ 770 ADS_ParkRelPos2_y4_302h 0;
BA_ "GenSigSendType" SG_ 771 TimeGapAdjustment_33Dh 0;
BA_ "GenSigSendType" SG_ 777 ISGF_ErrLvl 0;
BA_ "GenSigSendType" SG_ 783 ADCC_SysReadySts 0;
BA_ "GenSigSendType" SG_ 787 PassSitPosnSts_313h 0;
BA_ "GenSigSendType" SG_ 787 ChrgHoodSts 0;
BA_ "GenSigSendType" SG_ 788 ADS_2_AEBStatus 0;
BA_ "GenSigSendType" SG_ 788 ADS_2_FCWStatus 0;
BA_ "GenSigSendType" SG_ 788 FCM_2_IHCfunctionSts 0;
BA_ "GenSigSendType" SG_ 789 ATCM_DriveModeSw 2;
BA_ "GenSigSendType" SG_ 789 ATCM_XModeSw 2;
BA_ "GenSigSendType" SG_ 789 ATCM_SwitchUTurnModeSet 2;
BA_ "GenSigSendType" SG_ 789 ATCM_ASU_LiftSet 2;
BA_ "GenSigSendType" SG_ 789 ATCM_ASU_LowerSet 2;
BA_ "GenSigSendType" SG_ 789 ATCM_ESP_OFF_SW 2;
BA_ "GenSigSendType" SG_ 789 ATCM_AVH_SW 2;
BA_ "GenSigSendType" SG_ 789 ATCM_AVM 2;
BA_ "GenSigSendType" SG_ 794 ADS_3_ICATextinfo 0;
BA_ "GenSigSendType" SG_ 794 ADS_3_ICAStatus 0;
BA_ "GenSigSendType" SG_ 794 ADS_3_DriverHandsoffWarning 0;
BA_ "GenSigSendType" SG_ 794 ADS_3_ACCSts 0;
BA_ "GenSigSendType" SG_ 794 ADS_3_LKSSts 0;
BA_ "GenSigSendType" SG_ 794 ADS_3_LKSMod 0;
BA_ "GenSigSendType" SG_ 794 ADS_3_LKSRightTrackingSt 0;
BA_ "GenSigSendType" SG_ 794 ADS_3_LKSLeftTrackingSt 0;
BA_ "GenSigSendType" SG_ 794 ADS_3_ELKSts 0;
BA_ "GenSigSendType" SG_ 794 ADS_3_ELKRightActiveSt 0;
BA_ "GenSigSendType" SG_ 794 ADS_3_ELKLeftActiveSt 0;
BA_ "ASIL" SG_ 794 ADS_HNOPSts 2;
BA_ "GenSigSendType" SG_ 794 ADS_HNOPSts 0;
BA_ "GenSigInvalidValue" SG_ 811 BMS_Chg_Sts_32Bh 15;
BA_ "GenSigSendType" SG_ 811 BMS_Chg_Sts_32Bh 0;
BA_ "GenSigSendType" SG_ 819 ADS_4_CRC1 0;
BA_ "GenSigSendType" SG_ 819 ADS_4_RollgCntr1 0;
BA_ "GenSigSendType" SG_ 819 ADS_4_Resd1 0;
BA_ "GenSigSendType" SG_ 819 ADS_4_AEBReqType 0;
BA_ "GenSigSendType" SG_ 819 ADS_4_AEBStatus 0;
BA_ "GenSigSendType" SG_ 819 ADS_4_ACCSts 0;
BA_ "GenSigSendType" SG_ 819 ADS_4_TimeGapSet 0;
BA_ "GenSigSendType" SG_ 819 ADS_4_FcwMode 0;
BA_ "GenSigInvalidValue" SG_ 819 ADS_4_SetSpd 255;
BA_ "GenSigSendType" SG_ 819 ADS_4_SetSpd 0;
BA_ "GenSigSendType" SG_ 819 ADS_4_DAIStatus 0;
BA_ "GenSigSendType" SG_ 819 ADS_4_ACCTextMessage 0;
BA_ "GenSigSendType" SG_ 819 ADS_4_LongiTakeOverReq 0;
BA_ "GenSigSendType" SG_ 819 ADS_4_SetSpdUnit 0;
BA_ "GenSigSendType" SG_ 819 ADS_4_GoNotifier 0;
BA_ "GenSigSendType" SG_ 819 ADS_4_DAISts 0;
BA_ "GenSigSendType" SG_ 819 ADS_4_Radar_textinfo 0;
BA_ "GenSigSendType" SG_ 819 ADS_4_SCF_PopoverReq 0;
BA_ "GenSigSendType" SG_ 819 ADS_4_DrvrCfmSCFDispFb 0;
BA_ "GenSigSendType" SG_ 819 ADS_4_SCF_SpdLimUnit 0;
BA_ "GenSigSendType" SG_ 819 ADS_4_SCF_SpdLimSts 0;
BA_ "GenSigSendType" SG_ 819 ADS_4_CRC2 0;
BA_ "GenSigSendType" SG_ 819 ADS_4_RollgCntr2 0;
BA_ "GenSigSendType" SG_ 819 ADS_4_Resd2 0;
BA_ "GenSigSendType" SG_ 819 ADS_4_ACCObjTyp 0;
BA_ "GenSigSendType" SG_ 819 ADS_4_FrntFarObjTyp 0;
BA_ "GenSigSendType" SG_ 819 ADS_4_ACCObjLgtDstX 0;
BA_ "GenSigSendType" SG_ 819 ADS_4_ACCObjHozDstY 0;
BA_ "GenSigSendType" SG_ 819 ADS_4_FrntFarObjHozDstY 0;
BA_ "GenSigSendType" SG_ 819 ADS_4_FrntFarObjID 0;
BA_ "GenSigSendType" SG_ 819 ADS_4_Resd 0;
BA_ "GenSigSendType" SG_ 819 ADS_4_ACCObjID 0;
BA_ "GenSigSendType" SG_ 819 ADS_4_FrntFarObjLgtDstX 0;
BA_ "GenSigSendType" SG_ 819 ADS_4_CRC3 0;
BA_ "GenSigSendType" SG_ 819 ADS_4_RollgCntr3 0;
BA_ "GenSigSendType" SG_ 819 ADS_4_Resd3 0;
BA_ "GenSigSendType" SG_ 819 ADS_4_LeObjHozDstY 0;
BA_ "GenSigSendType" SG_ 819 ADS_4_Resd_1 0;
BA_ "GenSigSendType" SG_ 819 ADS_4_LeObjID 0;
BA_ "GenSigSendType" SG_ 819 ADS_4_LeObjTyp 0;
BA_ "GenSigSendType" SG_ 819 ADS_4_LeObjLgtDstX 0;
BA_ "GenSigSendType" SG_ 819 ADS_4_RiObjHozDstY 0;
BA_ "GenSigSendType" SG_ 819 ADS_4_RiObjID 0;
BA_ "GenSigSendType" SG_ 819 ADS_4_RiObjTyp 0;
BA_ "GenSigSendType" SG_ 819 ADS_4_RiObjLgtDstX 0;
BA_ "GenSigSendType" SG_ 819 ADS_4_CRC4 0;
BA_ "GenSigSendType" SG_ 819 ADS_4_RollgCntr4 0;
BA_ "GenSigSendType" SG_ 819 ADS_4_Resd4 0;
BA_ "GenSigSendType" SG_ 819 ADS_4_SCFSwtSet 0;
BA_ "GenSigSendType" SG_ 819 ADS_4_AEBSettingSt 0;
BA_ "GenSigSendType" SG_ 819 ADS_4_FCWSettingSt 0;
BA_ "GenSigSendType" SG_ 819 NOPTextinfo_333h 0;
BA_ "GenSigSendType" SG_ 819 ADS_4_CruiseAccelerateSts 0;
BA_ "GenSigSendType" SG_ 819 ADS_4_DAISwtSet 0;
BA_ "GenSigSendType" SG_ 819 FCM_FRM_DAIONOFFSts_333h 0;
BA_ "GenSigStartValue" SG_ 819 FCTAFCTBONOFFSts_333h 3;
BA_ "GenSigSendType" SG_ 819 FCTAFCTBONOFFSts_333h 0;
BA_ "GenSigSendType" SG_ 819 TRA_Operation_Status_333h 0;
BA_ "GenSigSendType" SG_ 819 LightingBlueONOFFSts_333h 0;
BA_ "GenSigSendType" SG_ 819 ADCC_AdsLowPowSts_333h 0;
BA_ "GenSigSendType" SG_ 819 DataCollectionONOFFStS_333h 0;
BA_ "GenSigSendType" SG_ 819 FCM_10_TLITrfcLi_333h 0;
BA_ "GenSigSendType" SG_ 821 ADS_5_CRC1 0;
BA_ "GenSigSendType" SG_ 821 ADS_5_RollgCntr1 0;
BA_ "GenSigSendType" SG_ 821 ADS_5_Resd1 0;
BA_ "GenSigSendType" SG_ 821 ADS_5_ILOASts 0;
BA_ "GenSigSendType" SG_ 821 ADS_5_ICAQuitReason 0;
BA_ "GenSigSendType" SG_ 821 ADS_5_ISLISt 0;
BA_ "GenSigSendType" SG_ 821 ADS_5_ISLISpeedLimitSign 0;
BA_ "GenSigSendType" SG_ 821 ADS_5_ILOATextInfo 0;
BA_ "GenSigSendType" SG_ 821 ADS_5_ILOAActdirection 0;
BA_ "GenSigSendType" SG_ 821 ADS_5_LKS_warning 0;
BA_ "GenSigSendType" SG_ 821 ADS_5_EgoLeftLineHeatgAg 0;
BA_ "GenSigSendType" SG_ 821 ADS_5_ISLIOverSpeedWarn 0;
BA_ "GenSigSendType" SG_ 821 ADS_5_EgoLeLineHozlDst 0;
BA_ "GenSigSendType" SG_ 821 ADS_5_EgoLeLineID 0;
BA_ "GenSigSendType" SG_ 821 ADS_5_EgoLeLineColor 0;
BA_ "GenSigSendType" SG_ 821 ADS_5_EgoLeLineTyp 0;
BA_ "GenSigSendType" SG_ 821 ADS_5_CRC2 0;
BA_ "GenSigSendType" SG_ 821 ADS_5_RollgCntr2 0;
BA_ "GenSigSendType" SG_ 821 ADS_5_Resd2 0;
BA_ "GenSigSendType" SG_ 821 ADS_5_EgoLeLineCrvt 0;
BA_ "GenSigSendType" SG_ 821 ADS_5_NeborLeLineHozlDst 0;
BA_ "GenSigSendType" SG_ 821 ADS_5_NeborLeLineID 0;
BA_ "GenSigSendType" SG_ 821 ADS_5_NeborLeLineColor 0;
BA_ "GenSigSendType" SG_ 821 ADS_5_NeborLeLineTyp 0;
BA_ "GenSigSendType" SG_ 821 ADS_5_NeborLeLineCrvt 0;
BA_ "GenSigSendType" SG_ 821 ADS_5_NeborRiLineHozlDst 0;
BA_ "GenSigSendType" SG_ 821 ADS_5_NeborRiLineID 0;
BA_ "GenSigSendType" SG_ 821 ADS_5_NeborRiLineColor 0;
BA_ "GenSigSendType" SG_ 821 ADS_5_NeborRiLineTyp 0;
BA_ "GenSigSendType" SG_ 821 ADS_5_CRC3 0;
BA_ "GenSigSendType" SG_ 821 ADS_5_RollgCntr3 0;
BA_ "GenSigSendType" SG_ 821 ADS_5_Resd3 0;
BA_ "GenSigSendType" SG_ 821 ADS_5_NeborRiLineCrvt 0;
BA_ "GenSigSendType" SG_ 821 ADS_5_ELKSettingSt 0;
BA_ "GenSigSendType" SG_ 821 ADS_5_LDWLDPSnvtySet 0;
BA_ "GenSigSendType" SG_ 821 ADS_5_LDWWarnType 0;
BA_ "GenSigSendType" SG_ 821 ADS_5_IESSwtSet 0;
BA_ "GenSigSendType" SG_ 821 ADS_5_IHCSettingSt 0;
BA_ "GenSigSendType" SG_ 821 ADS_5_ISLIWarningMod 0;
BA_ "GenSigSendType" SG_ 821 ADS_5_ICAEnableBtnSts 0;
BA_ "GenSigSendType" SG_ 821 ADS_5_EgoRiLineTyp 0;
BA_ "GenSigSendType" SG_ 821 ADS_5_FCM_Camera_textinfo 0;
BA_ "GenSigInvalidValue" SG_ 821 ADS_5_EgoRiLineHozlDst 511;
BA_ "GenSigSendType" SG_ 821 ADS_5_EgoRiLineHozlDst 0;
BA_ "GenSigSendType" SG_ 821 ADS_5_EgoRiLineColor 0;
BA_ "GenSigSendType" SG_ 821 ADS_5_EgoRiLineID 0;
BA_ "GenSigSendType" SG_ 821 ADS_5_CRC4 0;
BA_ "GenSigSendType" SG_ 821 ADS_5_RollgCntr4 0;
BA_ "GenSigSendType" SG_ 821 ADS_5_Resd4 0;
BA_ "GenSigInvalidValue" SG_ 821 ADS_5_EgoRightLineHeatgAg 511;
BA_ "GenSigSendType" SG_ 821 ADS_5_EgoRightLineHeatgAg 0;
BA_ "GenSigInvalidValue" SG_ 821 ADS_5_EgoRiLineCrvt 1023;
BA_ "GenSigSendType" SG_ 821 ADS_5_EgoRiLineCrvt 0;
BA_ "GenSigInvalidValue" SG_ 821 ADS_5_NeborLeftLineHeatgAg 511;
BA_ "GenSigSendType" SG_ 821 ADS_5_NeborLeftLineHeatgAg 0;
BA_ "GenSigInvalidValue" SG_ 821 ADS_5_NeborRightLineHeatgAg 511;
BA_ "GenSigSendType" SG_ 821 ADS_5_NeborRightLineHeatgAg 0;
BA_ "ASIL" SG_ 850 ASU_6_HMIFailFb_JT 2;
BA_ "GenSigSendType" SG_ 850 ASU_6_HMIFailFb_JT 0;
BA_ "GenSigSendType" SG_ 859 RearDefrostSts 0;
BA_ "GenSigSendType" SG_ 917 ADBenable 0;
BA_ "GenSigSendType" SG_ 917 RandomMusicShowCMD 0;
BA_ "GenSigSendType" SG_ 917 DIYMusicShowmod 0;
BA_ "GenSigSendType" SG_ 917 MusicLoudness_55HZ 0;
BA_ "GenSigSendType" SG_ 917 LiShowMod 0;
BA_ "GenSigSendType" SG_ 917 MusicLoudness_262HZ 0;
BA_ "GenSigSendType" SG_ 917 MusicLoudness_123HZ 0;
BA_ "GenSigSendType" SG_ 917 MusicLoudness_587HZ 0;
BA_ "GenSigSendType" SG_ 917 MusicLoudness_440HZ 0;
BA_ "GenSigSendType" SG_ 917 MusicLoudness_784HZ 0;
BA_ "GenSigSendType" SG_ 917 MusicLoudness_2794HZ 0;
BA_ "GenSigSendType" SG_ 917 MusicLoudness_1318HZ 0;
BA_ "GenSigSendType" SG_ 917 MusicLoudness_6272HZ 0;
BA_ "GenSigSendType" SG_ 917 ISDShowCMD 0;
BA_ "GenSigSendType" SG_ 917 ISDShowMode 0;
BA_ "GenSigSendType" SG_ 943 CSA_3_CRC1 0;
BA_ "GenSigSendType" SG_ 943 CSA_3_RollgCntr1 0;
BA_ "GenSigSendType" SG_ 943 CSA_3_Resd1 0;
BA_ "GenSigInvalidValue" SG_ 943 FlwheelBearing 4095;
BA_ "GenSigSendType" SG_ 943 FlwheelBearing 0;
BA_ "GenSigInvalidValue" SG_ 943 FrwheelBearing 4095;
BA_ "GenSigSendType" SG_ 943 FrwheelBearing 0;
BA_ "GenSigInvalidValue" SG_ 943 BlwheelBearing 4095;
BA_ "GenSigSendType" SG_ 943 BlwheelBearing 0;
BA_ "GenSigInvalidValue" SG_ 943 BrwheelBearing 4095;
BA_ "GenSigSendType" SG_ 943 BrwheelBearing 0;
BA_ "GenSigSendType" SG_ 943 CSA_3_CRC2 0;
BA_ "GenSigSendType" SG_ 943 CSA_3_RollgCntr2 0;
BA_ "GenSigInvalidValue" SG_ 943 VehicleBearing_kg 4095;
BA_ "GenSigSendType" SG_ 943 VehicleBearing_kg 0;
BA_ "GenSigInvalidValue" SG_ 943 VehicleBearing_lb 4095;
BA_ "GenSigSendType" SG_ 943 VehicleBearing_lb 0;
BA_ "GenSigInvalidValue" SG_ 943 GoodsWeight_kg 4095;
BA_ "GenSigSendType" SG_ 943 GoodsWeight_kg 0;
BA_ "GenSigInvalidValue" SG_ 943 Goods_Weight_Ratio 1023;
BA_ "GenSigSendType" SG_ 943 Goods_Weight_Ratio 0;
BA_ "GenSigSendType" SG_ 943 CSA_3_CRC3 0;
BA_ "GenSigSendType" SG_ 943 CSA_3_RollgCntr3 0;
BA_ "GenSigSendType" SG_ 943 CSA_3_Resd3 0;
BA_ "GenSigInvalidValue" SG_ 943 GoodsWeight_lb 4095;
BA_ "GenSigSendType" SG_ 943 GoodsWeight_lb 0;
BA_ "GenSigInvalidValue" SG_ 943 OverWeightValue_kg 4095;
BA_ "GenSigSendType" SG_ 943 OverWeightValue_kg 0;
BA_ "GenSigInvalidValue" SG_ 943 OverWeightValue_lb 4095;
BA_ "GenSigSendType" SG_ 943 OverWeightValue_lb 0;
BA_ "GenSigSendType" SG_ 943 OverLoadWarnShieldSetFed 0;
BA_ "GenSigSendType" SG_ 943 OverWeightWarning 0;
BA_ "GenSigSendType" SG_ 943 OverWeightRatio 0;
BA_ "GenSigInvalidValue" SG_ 943 Fraxlebearingrate 255;
BA_ "GenSigSendType" SG_ 943 Fraxlebearingrate 0;
BA_ "GenSigSendType" SG_ 949 PEPS_OrderInformation 0;
BA_ "GenSigSendType" SG_ 949 PEPS_InformationSource 0;
BA_ "GenSigSendType" SG_ 949 PEPS_KeySts 0;
BA_ "GenSigSendType" SG_ 949 PEPS_IDInformation 0;
BA_ "GenSigSendType" SG_ 949 PEPS_ETRUnLockReq 4;
BA_ "GenSigSendType" SG_ 991 TMS_BatteryLoopErrorLevel 0;
BA_ "GenSigSendType" SG_ 991 TMS_MotorLoopErrorLevel 0;
BA_ "GenSigSendType" SG_ 1018 FLZCU_DraggingModeRemind_3FAh 0;
BA_ "GenSigSendType" SG_ 1018 FLZCU_KeyDriveModememory_3FAh 0;
BA_ "GenSigSendType" SG_ 1018 FLZCU_DriveMode_3FAh 0;
BA_ "GenSigSendType" SG_ 1018 FLZCU_CCO_TextDisp_3FAh 0;
BA_ "GenSigSendType" SG_ 1018 FLZCU_CCOSwtReq_3FAh 0;
BA_ "GenSigSendType" SG_ 1018 FLZCU_DriveModeChangeFail_3FAh 0;
BA_ "GenSigInvalidValue" SG_ 1020 SAM_1_SteeringAngleSpeed 255;
BA_ "GenSigStartValue" SG_ 1020 SAM_1_SteeringAngleSpeed 255;
BA_ "GenSigSendType" SG_ 1020 SAM_1_SteeringAngleSpeed 0;
BA_ "GenSigInvalidValue" SG_ 1020 SAM_1_SteeringAngle 65535;
BA_ "GenSigStartValue" SG_ 1020 SAM_1_SteeringAngle 65535;
BA_ "GenSigSendType" SG_ 1020 SAM_1_SteeringAngle 0;
BA_ "GenSigInvalidValue" SG_ 1020 BMSH_MaxChgPwrPeak 4095;
BA_ "GenSigSendType" SG_ 1020 BMSH_MaxChgPwrPeak 0;
BA_ "GenSigInvalidValue" SG_ 1020 BMSH_MaxDchgPwrPeak 4095;
BA_ "GenSigSendType" SG_ 1020 BMSH_MaxDchgPwrPeak 0;
BA_ "GenSigInvalidValue" SG_ 1020 FMCU_8_ISGF_SpdAct 65535;
BA_ "GenSigStartValue" SG_ 1020 FMCU_8_ISGF_SpdAct 32767;
BA_ "ASIL" SG_ 1020 FMCU_8_ISGF_SpdAct 1;
BA_ "GenSigSendType" SG_ 1020 FMCU_8_ISGF_SpdAct 0;
BA_ "GenSigInvalidValue" SG_ 1020 RMCU_1_Speed 65535;
BA_ "GenSigStartValue" SG_ 1020 RMCU_1_Speed 32767;
BA_ "ASIL" SG_ 1020 RMCU_1_Speed 3;
BA_ "GenSigSendType" SG_ 1020 RMCU_1_Speed 0;
BA_ "GenSigStartValue" SG_ 1020 SAM_1_SteeringAngleVD 1;
BA_ "GenSigSendType" SG_ 1020 SAM_1_SteeringAngleVD 0;
BA_ "GenSigStartValue" SG_ 1020 SAM_1_SteeringAngleSpeedVD 1;
BA_ "GenSigSendType" SG_ 1020 SAM_1_SteeringAngleSpeedVD 0;
BA_ "GenSigStartValue" SG_ 1020 CSA_2_AllWarningInfo 7;
BA_ "ASIL" SG_ 1020 CSA_2_AllWarningInfo 2;
BA_ "GenSigSendType" SG_ 1020 CSA_2_AllWarningInfo 0;
BA_ "GenSigSendType" SG_ 1020 RMCU_1_TCURErrLvlDis 0;
BA_ "ASIL" SG_ 1020 ASU_2_sensorErrorSts 2;
BA_ "GenSigSendType" SG_ 1020 ASU_2_sensorErrorSts 0;
BA_ "GenSigInvalidValue" SG_ 1020 ASU_2_LFHeight 4095;
BA_ "GenSigStartValue" SG_ 1020 ASU_2_LFHeight 1500;
BA_ "ASIL" SG_ 1020 ASU_2_LFHeight 2;
BA_ "GenSigSendType" SG_ 1020 ASU_2_LFHeight 0;
BA_ "GenSigInvalidValue" SG_ 1020 ASU_2_RFHeight 4095;
BA_ "GenSigStartValue" SG_ 1020 ASU_2_RFHeight 1500;
BA_ "ASIL" SG_ 1020 ASU_2_RFHeight 2;
BA_ "GenSigSendType" SG_ 1020 ASU_2_RFHeight 0;
BA_ "GenSigInvalidValue" SG_ 1020 ASU_2_LRHeight 4095;
BA_ "GenSigStartValue" SG_ 1020 ASU_2_LRHeight 1500;
BA_ "ASIL" SG_ 1020 ASU_2_LRHeight 2;
BA_ "GenSigSendType" SG_ 1020 ASU_2_LRHeight 0;
BA_ "GenSigInvalidValue" SG_ 1020 ASU_2_RRHeight 4095;
BA_ "GenSigStartValue" SG_ 1020 ASU_2_RRHeight 1500;
BA_ "ASIL" SG_ 1020 ASU_2_RRHeight 2;
BA_ "GenSigSendType" SG_ 1020 ASU_2_RRHeight 0;
BA_ "ASIL" SG_ 1020 CSA_2_WiprFrntCmd 1;
BA_ "GenSigSendType" SG_ 1020 CSA_2_WiprFrntCmd 0;
BA_ "GenSigInvalidValue" SG_ 1020 EVCC_GunConnectSt_203h 3;
BA_ "GenSigSendType" SG_ 1020 EVCC_GunConnectSt_203h 0;
BA_ "ASIL" SG_ 1020 STAT_ShifterLeverFault 2;
BA_ "GenSigSendType" SG_ 1020 STAT_ShifterLeverFault 0;
BA_ "GenSigSendType" SG_ 1022 FLZCU_MedStatusFb 0;
BA_ "GenSigSendType" SG_ 1022 FLZCU_SteerWhlposSts 0;
BA_ "GenSigSendType" SG_ 1022 FLZCU_CarMode 0;
BA_ "GenSigSendType" SG_ 1022 FLZCU_MedAreaFb 0;
BA_ "GenSigSendType" SG_ 1022 FLZCU_MedFailCause 0;
BA_ "GenSigInvalidValue" SG_ 1022 DrvSecSeatLvltargetCmd_3FEh 127;
BA_ "GenSigSendType" SG_ 1022 DrvSecSeatLvltargetCmd_3FEh 0;
BA_ "GenSigSendType" SG_ 1022 FLZCU_NapArea2Fb 0;
BA_ "GenSigSendType" SG_ 1022 FLZCU_MedClosePrompt 0;
BA_ "GenSigInvalidValue" SG_ 1022 DrvSecSeatBackAgCmd_3FEh 127;
BA_ "GenSigSendType" SG_ 1022 DrvSecSeatBackAgCmd_3FEh 0;
BA_ "GenSigInvalidValue" SG_ 1022 DrvSecSeatLegSpprtCmd_3FEh 127;
BA_ "GenSigSendType" SG_ 1022 DrvSecSeatLegSpprtCmd_3FEh 0;
BA_ "GenSigSendType" SG_ 1022 FLZCU_LogoChargingSts 0;
BA_ "GenSigSendType" SG_ 1022 FLZCU_MonoAmbLigSts 0;
BA_ "GenSigSendType" SG_ 1022 DrvRearWinThermalStatus_3FEh 0;
BA_ "GenSigSendType" SG_ 1022 DrvWinThermalStatus_3FEh 0;
BA_ "GenSigInvalidValue" SG_ 1022 PassRearSeatBackAgCmd_3FEh 127;
BA_ "GenSigSendType" SG_ 1022 PassRearSeatBackAgCmd_3FEh 0;
BA_ "GenSigInvalidValue" SG_ 1022 PassRearSeatLvltargetCmd_3FEh 127;
BA_ "GenSigSendType" SG_ 1022 PassRearSeatLvltargetCmd_3FEh 0;
BA_ "GenSigInvalidValue" SG_ 1022 PassRearSeatLegSpprtCmd_3FEh 127;
BA_ "GenSigSendType" SG_ 1022 PassRearSeatLegSpprtCmd_3FEh 0;
BA_ "GenSigSendType" SG_ 1022 DrvSitPosnSts_3FEh 0;
BA_ "GenSigSendType" SG_ 1022 DrvRearSeatVentLvl2_3FEh 0;
BA_ "GenSigSendType" SG_ 1022 DrvSeatVentLvl2_3FEh 0;
BA_ "GenSigSendType" SG_ 1022 DrvRearSeatHeatLvl2_3FEh 0;
BA_ "GenSigSendType" SG_ 1022 DrvSeatHeatLvl2_3FEh 0;
BA_ "GenSigSendType" SG_ 1022 FLZCU_DrvExpSeatSts_3FEh 0;
BA_ "GenSigSendType" SG_ 1022 FLZCU_FLogolightInhibitSts 0;
BA_ "GenSigSendType" SG_ 1022 FLZCU_SteerOverHeatWarn 0;
BA_ "GenSigInvalidValue" SG_ 1022 MaintenanceOdometer_Backup_3FEh 16777215;
BA_ "GenSigSendType" SG_ 1022 MaintenanceOdometer_Backup_3FEh 0;
BA_ "GenSigSendType" SG_ 1024 CSunshadePercentSts 0;
BA_ "GenSigSendType" SG_ 1024 CSunshadeSts 0;
BA_ "GenSigSendType" SG_ 1024 PassSeatVentLvl2_400h 0;
BA_ "GenSigSendType" SG_ 1024 PassSeatHeatLvl2_400h 0;
BA_ "GenSigSendType" SG_ 1024 PassSecSeatHeatLvl2_400h 0;
BA_ "GenSigSendType" SG_ 1024 PassSecSeatVentLvl2_400h 0;
BA_ "GenSigSendType" SG_ 1024 FRZCU_OnekeyHVoffSwtst 0;
BA_ "GenSigSendType" SG_ 1024 FRZCU_CSunshadeThermalSts 0;
BA_ "GenSigSendType" SG_ 1024 PassRearWinThermalSts_400h 0;
BA_ "GenSigSendType" SG_ 1024 PassWinThermalSts_400h 0;
BA_ "GenSigSendType" SG_ 1024 FRZCU_ContainerlightSts 0;
BA_ "GenSigSendType" SG_ 1024 FRZCU_ADSLightSts 0;
BA_ "GenSigSendType" SG_ 1024 FRZCU_QueenSeatEnterSts 0;
BA_ "GenSigSendType" SG_ 1024 FRZCU_PasgerSeatMovFailCause 0;
BA_ "GenSigSendType" SG_ 1024 FRZCU_ADSLightFltSts 0;
BA_ "GenSigSendType" SG_ 1024 FRZCU_QueenSeatPosSts 0;
BA_ "GenSigSendType" SG_ 1024 FRZCU_QueenSeatSts 0;
BA_ "GenSigSendType" SG_ 1024 FRZCU_QueenSeatMovFailCause 0;
BA_ "GenSigSendType" SG_ 1024 CSunshadeLearnedSts 0;
BA_ "GenSigInvalidValue" SG_ 1024 CSunshadePosn 127;
BA_ "GenSigStartValue" SG_ 1024 CSunshadePosn 127;
BA_ "GenSigSendType" SG_ 1024 CSunshadePosn 0;
VAL_ 33 ACU_3_LongitudinalAccelerationVD 0 "Valid" 1 "Reserved" 2 "Invalid" 3 "Initialize" ;
VAL_ 33 ACU_3_CrashOutputSts 0 "No crash" 16 "Rear Crash" 32 "Roll Crash" 1 "Belt Crash" 2 "Front Crash" 4 "Left Side Crash" 8 "Right Side Crash" ;
VAL_ 49 ACU_2_YawrateSigValidData 0 "Valid" 1 "Reserved" 2 "Invalid" 3 "Initialize" ;
VAL_ 49 ACU_2_LateralAccelerationSigVD 0 "Valid" 1 "Reserved" 2 "Invalid" 3 "Initialize" ;
VAL_ 258 BMS_PackVoltage 65534 "Abnormal" 65535 "Invalid" ;
VAL_ 258 BMS_PackCurrent 65534 "Abnormal" 65535 "Invalid" ;
VAL_ 258 BMS_HvBattSts 0 "Init" 1 "standby" 2 "Precharge" 3 "HVOn" 4 "AC charge Mode" 5 "DC charge Mode" 6 "Boost charging mode" 7 "PreHeat Mode" 8 "keep warm" 9 "powerdown" 10 "emergencypowerdown" 11 "fault" 12 "afterrun" 13 "Keep warm complete Mode" 14 "PreHeat complete Mode" ;
VAL_ 258 BMS_SysSelfCheck 1 "self_checking" 2 "flaut" 3 "no fault" ;
VAL_ 258 BMS_HVBattThermRunaway 0 "normal" 1 "warning" 2 "invalid" ;
VAL_ 258 BMS_ChargeVoltageReq 16382 "Error" 16383 "Init" ;
VAL_ 258 BMS_ChgCurrReq 16382 "Error" 16383 "Init" ;
VAL_ 258 BMS_InfraDcUActDc 16382 "Error" 16383 "Init" ;
VAL_ 258 BMS_InfraDcIActDc 16382 "Error" 16383 "Init" ;
VAL_ 258 BMS_HvBattDynChrgnILim 16382 "Error" 16383 "Init" ;
VAL_ 258 BMS_HvBattUChrgnLim 16382 "Error" 16383 "Init" ;
VAL_ 258 BMS_ChrgDcIAvl 16382 "Error" 16383 "Init" ;
VAL_ 258 BMS_DChrgAPlusSt 0 "not active" 1 "active" ;
VAL_ 258 BMS_ChrgDcCnctrDetd 0 "Init" 1 "Connector not detected" 2 "Connector detected" 3 "SNS/Fault" ;
VAL_ 258 BMS_DCChgMode 0 "Default" 1 "HandOver" 2 "ParaConfig" 3 "Chging" 4 "ChgEnd" 5 "ChgWaring" 6 "ChgFault" ;
VAL_ 258 BMS_ChrgDcChrgnFltStopReas 0 "no fault" 1 "End by Infrastructure fault" 2 "BMS fault" 3 "CC2 fault" 4 "DC charge not allowd because low temperature" 5 "VCU fault" 6 "Boost fault" 7 "Other fault" ;
VAL_ 258 BMS_ChgRemTime 2046 "SNA/Fault" 2047 "Init" ;
VAL_ 258 BMS_ChargeRequest_Mode 0 "No request" 1 "AC Charging request" 2 "Boost Charging request" 3 "DC Fast Charging request" 4 "Charge precharge request" 5 "Reserved" 6 "Reserved" 7 "Reserved" 8 "Reserved" 9 "Reserved" 10 "Reserved" 11 "Reserved" 12 "Reserved" 13 "Reserved" 14 "Reserved" 15 "init" ;
VAL_ 258 BMS_1_StateOfChargeDis 254 "Abnormal" 255 "Invalid" ;
VAL_ 258 BMS_StateOfEnergy 65534 "Abnormal" 65535 "Invalid" ;
VAL_ 258 BMS_BlanceState 0 "Balance OFF" 1 "Balance ON" ;
VAL_ 258 BMS_IsolationFault 0 "no fault" 1 "Fault L1" 2 "Fault L2" 3 "Fault L3" ;
VAL_ 258 BMS_HVILFault_DC 0 "No fault" 1 "fault" ;
VAL_ 258 BMS_HVILFault_FMCU 0 "No fault" 1 "fault" ;
VAL_ 258 BMS_HVILFault_RMCU 0 "No fault" 1 "fault" ;
VAL_ 258 BMS_SOCDis 16382 "Abnormal" 16383 "Invalid" ;
VAL_ 258 BMS_InfraDcIActDcMin 16382 "Error" 16383 "Init" ;
VAL_ 259 EMS_EngineSpeed_Actual 65535 "Invalid" ;
VAL_ 290 EPSFailSts 0 "Not present" 1 "Fail present" 2 "Reserved" 3 "Reserved" ;
VAL_ 290 EPSSteeringAngleCalibrationSts 0 "Calibration is fine" 1 "No calibration or no initialization" ;
VAL_ 290 EPS_EOTLearning_Sts 0 "Learnt" 1 "Not Learnt" ;
VAL_ 513 MFSL_UP_SW 0 "Not_action" 1 "Pressed" 2 "Stuck" 3 "invalid" ;
VAL_ 513 MFSL_DW_SW 0 "Not_action" 1 "Pressed" 2 "Stuck" 3 "invalid" ;
VAL_ 513 MFSL_Left_SW 0 "Not_action" 1 "Pressed" 2 "Stuck" 3 "invalid" ;
VAL_ 513 MFSL_Right_SW 0 "Not_action" 1 "Pressed" 2 "Stuck" 3 "invalid" ;
VAL_ 513 MFSL_OK_SW 0 "Not_action" 1 "Pressed" 2 "Stuck" 3 "invalid" ;
VAL_ 513 MFSL_AVM_SW 0 "Not_action" 1 "Pressed" 2 "Stuck" 3 "invalid" ;
VAL_ 513 MFSL_Customize 0 "Not_action" 1 "Pressed" 2 "Stuck" 3 "invalid" ;
VAL_ 513 MFSL_APA_SW 0 "Not_action" 1 "Pressed" 2 "Stuck" 3 "invalid" ;
VAL_ 513 MFSL_LCC_NCA_SW 0 "Not_action" 1 "Pressed" 2 "Stuck" 3 "invalid" ;
VAL_ 514 ADS_NicaReminderAcoustic_202h 0 "no request" 1 "acoustic" 2 "no acoustic" 3 "torL1_acoustic" 4 "aeb_acoustic" 5 "plsLiftFoot_acoustic" 6 "reserved" 7 "Invalid" ;
VAL_ 514 ADS_NicaReminderLEDVisual_202h 0 "no request" 1 "turn on" 2 "turn off" 3 "reserved" 4 "reserved" 5 "reserved" 6 "reserved" 7 "Invalid" ;
VAL_ 514 ADS_AdsFault_202h 0 "no request" 1 "无故障" 2 "有故障" 3 "reserved" 7 "Invalid" ;
VAL_ 514 ADS_TakeoverID_202h 0 "no request作为默认值" ;
VAL_ 514 ADS_TakeoverType_202h 0 "no request" 1 "大红手" 2 "松开加速踏板" 3 "制动踏板" 4 "MRM大红手" 5 "大黄手" 15 "Invalid" ;
VAL_ 514 ADS_TakeoverLevel_202h 0 "no request" 1 "Level 1" 2 "Level 2" 3 "Level 3" 4 "Level 4" 7 "Invalid" ;
VAL_ 514 ADS_TORIDCorrespErrorID_202h 0 "no request作为默认值" ;
VAL_ 517 MFSR_UP_SW 0 "Not_action" 1 "Pressed" 2 "Stuck" 3 "invalid" ;
VAL_ 517 MFSR_DW_SW 0 "Not_action" 1 "Pressed" 2 "Stuck" 3 "invalid" ;
VAL_ 517 MFSR_Left_SW 0 "Not_action" 1 "Pressed" 2 "Stuck" 3 "invalid" ;
VAL_ 517 MFSR_Right_SW 0 "Not_action" 1 "Pressed" 2 "Stuck" 3 "invalid" ;
VAL_ 517 MFSR_OK_SW 0 "Not_action" 1 "Pressed" 2 "Stuck" 3 "invalid" ;
VAL_ 517 MFSR_MENU_SW 0 "Not_action" 1 "Pressed" 2 "Stuck" 3 "invalid" ;
VAL_ 517 MFSR_Voice_SW 0 "Not_action" 1 "Pressed" 2 "Stuck" 3 "invalid" ;
VAL_ 517 MFSR_Customize 0 "Not_action" 1 "Pressed" 2 "Stuck" 3 "invalid" ;
VAL_ 524 ADS_6_Customize_buttonsFB 0 "Not Active" 1 "APA" 2 "TJA/ICA/ACC/NOA" 3 "Offroad AutoPilot" 4 "HPA" ;
VAL_ 571 LHTurnlightSts 0 "Not Active" 1 "Active" ;
VAL_ 571 RHTurnlightSts 0 "Not Active" 1 "Active" ;
VAL_ 571 DrvDoorSts_23Bh 0 "Close" 1 "Ajar" 2 "full_open" 3 "Reserved" ;
VAL_ 571 DrvDoorLockSts_23Bh 0 "Locked" 1 "Unlocked" 2 "Superlocked" 3 "Unknown" ;
VAL_ 571 LHTurnSW 0 "Off" 1 "Active" ;
VAL_ 571 RHTurnSW 0 "Off" 1 "Active" ;
VAL_ 571 HazardLightSW 0 "Close" 1 "Open" ;
VAL_ 571 DrvSeatBeltSW_23Bh 0 "Not Active" 1 "Active" ;
VAL_ 571 DirectionIndLeft 0 "Close" 1 "Open" ;
VAL_ 571 DirectionIndRight 0 "Close" 1 "Open" ;
VAL_ 572 ONEBOX_7_TAB_HighTemp 0 "No Active" 1 "Active" ;
VAL_ 572 ONEBOX_7_TAB_Active 0 "Not Active" 1 "Active" 2 "Stand by" 3 "Failed" ;
VAL_ 572 ONEBOX_7_BSW_Active 0 "Not Active" 1 "Active" 2 "Filed" 3 "initialize" ;
VAL_ 572 ONEBOX_7_iCCO_Active 0 "Not Active" 1 "Standby" 2 "Active" 3 "Filed" ;
VAL_ 587 LHRPulseCounterFailSts 0 "Fail Not Present" 1 "Fail Present" ;
VAL_ 587 RHRPulseCounterFailSts 0 "Fail Not Present" 1 "Fail Present" ;
VAL_ 587 RHFPulseCounterFailSts 0 "Fail Not Present" 1 "Fail Present" ;
VAL_ 587 LHFPulseCounterFailSts 0 "Fail Not Present" 1 "Fail Present" ;
VAL_ 587 LHFWheelDriveDirection 0 "Init" 1 "Forward" 2 "Backward" 3 "Stop" 4 "Invalid" 5 "reserved" 6 "reserved" 7 "reserved" ;
VAL_ 587 RHFWheelDriveDirection 0 "Init" 1 "Forward" 2 "Backward" 3 "Stop" 4 "Invalid" 5 "reserved" 6 "reserved" 7 "reserved" ;
VAL_ 587 LHRWheelDriveDirection 0 "Init" 1 "Forward" 2 "Backward" 3 "Stop" 4 "Invalid" 5 "reserved" 6 "reserved" 7 "reserved" ;
VAL_ 587 RHRWheelDriveDirection 0 "Init" 1 "Forward" 2 "Backward" 3 "Stop" 4 "Invalid" 5 "reserved" 6 "reserved" 7 "reserved" ;
VAL_ 587 IPB_SandABSAvl_24Bh 0 "Not_Active" 1 "Available" 2 "Not_Available" 3 "Reserved" ;
VAL_ 587 IPB_SandABSSwSts_24Bh 0 "Not_Active" 1 "ON" 2 "OFF" 3 "Reserved" ;
VAL_ 612 EPBAUTO_Status_264h 0 "Active" 1 "Not_Active" ;
VAL_ 612 FltLamp_264h 0 "Lamp OFF" 1 "Lamp ON" 2 "Lamp Flash" 3 "Reserved" ;
VAL_ 612 ParkLamp_264h 0 "Lamp OFF" 1 "Lamp ON" 2 "Lamp Flash" 3 "Reserved" ;
VAL_ 612 ActrSt_264h 0 "Unknow" 1 "Applied" 2 "Released" 3 "Applying" 4 "Releasing" 5 "CompletelyReleased" 6 "Half Applied" 7 "Reserved" ;
VAL_ 612 RWUSt_264h 0 "No active" 1 "active" ;
VAL_ 612 TextDisp_264h 0 "NO text message" 1 "Gradient too high" 2 "Clampforce not enough" 3 "fasten seatbelt" 4 "Press brake pedal" 5 "No_Release_Tip_for_Shift" 6 "Press_the_brake_pedal_first,then_shift_the_gear_to_the 'N' position" 7 "Reserved" 8 "Reserved" 9 "Reserved" 10 "Reserved" 11 "Reserved" 12 "Reserved" 13 "Reserved" 14 "Reserved" 15 "Reserved" ;
VAL_ 612 IPB_EPBErrorStatus 0 "No_Error" 1 "Error" ;
VAL_ 632 EngineCoolantTemperature 255 "Invalid" ;
VAL_ 638 FRZCU_HoodSts 0 "Close" 1 "Ajar" 2 "full_open" 3 "Reserved" ;
VAL_ 638 FRZCU_AuthenResult 0 "not_success" 1 "success" ;
VAL_ 638 FRZCU_TrunkSts 0 "Close" 1 "Ajar" 2 "full_open" 3 "Reserved" ;
VAL_ 638 DrvHandleSwitchSts_27Eh 0 "Not_Active" 1 "Outside" 2 "Inside" 3 "Bothside" ;
VAL_ 638 PassHandleSwitchSts_27Eh 0 "Not_Active" 1 "Outside" 2 "Inside" 3 "Bothside" ;
VAL_ 638 PassRearHandleSwitchSts_27Eh 0 "Not_Active" 1 "Outside" 2 "Inside" 3 "Bothside" ;
VAL_ 638 DrvRearHandleSwitchSts_27Eh 0 "Not_Active" 1 "Outside" 2 "Inside" 3 "Bothside" ;
VAL_ 638 SeatLength_target_Passenger 0 "Not_active" 1 "0" 2 "10%" 3 "20%" 4 "30%" 5 "40%" 6 "50%" 7 "60%" 8 "70%" 9 "80%" 10 "90%" 11 "100%" 12 "Reserved" 13 "Reserved" 14 "Reserved" 15 "Reserved" ;
VAL_ 638 FRZCU_TrunkLockSts 0 "Locked" 1 "Unlocked" 2 "Superlocked" 3 "Unknown" ;
VAL_ 638 SeatBackrest_target_Passenger 0 "Not_active" 1 "0" 2 "5%" 3 "10%" 4 "15%" 5 "20%" 6 "25%" 7 "30%" 8 "35%" 9 "40%" 10 "45%" 11 "50%" 12 "55%" 13 "60%" 14 "65%" 15 "70%" 16 "75%" 17 "80%" 18 "85%" 19 "90%" 20 "95%" 21 "100%" 22 "Reserved" 23 "Reserved" 24 "Reserved" 25 "Reserved" 26 "Reserved" 27 "Reserved" 28 "Reserved" 29 "Reserved" 30 "Reserved" 31 "Reserved" ;
VAL_ 638 FRZCU_GloveboxSW 0 "OFF" 1 "ON" ;
VAL_ 638 FrontBackSpeedAdj_Cmd 0 "No_Request" 1 "Low" 2 "Medium" 3 "High" 4 "Reserved" 5 "Reserved" 6 "Reserved" ;
VAL_ 638 FRZCU_HoodLockSts 0 "Locked" 1 "Unlocked" 2 "Superlocked" 3 "Unknown" ;
VAL_ 638 FRZCU_PELockInKeyWarning 0 "Not_Active" 1 "Active" ;
VAL_ 638 PassRearReleaseLockSts_27Eh 0 "None" 1 "Releasing" 2 "Released" 3 "Reset" 4 "Resetting" 5 "Reserved" 6 "Reserved" 7 "Reserved" ;
VAL_ 638 PassReleaseLockSts_27Eh 0 "None" 1 "Releasing" 2 "Released" 3 "Reset" 4 "Resetting" 5 "Reserved" 6 "Reserved" 7 "Reserved" ;
VAL_ 638 FRZCU_OTAPwrDwnReqFb 0 "No_Command" 1 "Success" 2 "Fail" 3 "Resrved" ;
VAL_ 638 FRZCU_KeylessWarning 0 "Not_Active" 1 "Active" ;
VAL_ 638 FRZCU_PowerOFFWarning 0 "Not_Active" 1 "Active" ;
VAL_ 638 FRZCU_OTAPwrOnReqFb 0 "No_Command" 1 "Success" 2 "Fail" 3 "Resrved" ;
VAL_ 644 FuelShortGround 0 "Fail Not Present" 1 "Short Ground" ;
VAL_ 644 FuelShortPower 0 "Fail Not Present" 1 "Short Power" ;
VAL_ 644 FuelOutOfRange 0 "Fail Not Present" 1 "Out Of Range" ;
VAL_ 644 FuelValidData 0 "Valid" 1 "Not valid" ;
VAL_ 683 PassDoorSts_2ABh 0 "Close" 1 "Ajar" 2 "full_open" 3 "Reserved" ;
VAL_ 683 ParkLightSts 0 "Close" 1 "Open" ;
VAL_ 683 PassRearDoorSts_2ABh 0 "Close" 1 "Ajar" 2 "full_open" 3 "Reserved" ;
VAL_ 699 DrvRearDoorSts_2BBh 0 "Close" 1 "Ajar" 2 "full_open" 3 "Reserved" ;
VAL_ 769 ADS_LccNcaFunctionStatus_301h 0 "no request" 1 "OFF" 2 "LCC_STANDBY" 3 "LCC_LATERAL_OVERRIDE" 4 "LCC_LONGITUDINAL_OVERRIDE" 5 "LCC_LAT_LONG_OVERRIDE" 6 "LCC_ACTIVE" 7 "NCA_STANDBY" 8 "NCA_LATERAL_OVERRIDE" 9 "NCA_LONGITUDINAL_OVERRIDE" 10 "NCA_LAT_LONG_OVERRIDE" 11 "NCA_ACTIVE" 63 "Invalid" ;
VAL_ 769 ADS_AccFunctionStatus_301h 0 "No request" 1 "ACC_OFF" 2 "ACC_STANDBY" 3 "ACC_OVERRIDE" 4 "ACC_ACTIVE" 5 "ACC_STANDSTILL" 15 "Invalid" ;
VAL_ 769 ADS_AvpFunctionStatus_301h 0 "no request" 1 "AVP_STATE_OFF" 2 "AVP_STATE_STANDBY" 3 "AVP_STATE_OVERRIDE" 4 "AVP_STATE_ACTIVE" 31 "invalid" ;
VAL_ 769 ADS_AdsFucntionNotActive_301h 0 "no request" 1 "OFF" 2 "ACC" 3 "LCC" 4 "NCA" 5 "AVP" 15 "Invalid" ;
VAL_ 769 ADS_OneTouchSpeedAdjustment_301h 0 "no request" 1 "Speed+" 2 "Speed-" 7 "Invalid" ;
VAL_ 769 ADS_SpeedAutoFollow_301h 0 "no request" 1 "OFF" 2 "Active" 7 "Invalid" ;
VAL_ 769 ADS_HODReminder_301h 0 "no request" 1 "OFF" 2 "warning_level 1" 3 "warning_level 2" 4 "warning_level 3" 5 "warning_level 4" 6 "reserved" 7 "Invalid" ;
VAL_ 769 ADS_CalibState_301h 0 "no request" 1 "off" 2 "on" 3 "reserved" 4 "reserved" 5 "reserved" 6 "reserved" 7 "Invalid" ;
VAL_ 769 ADS_FcwFault_301h 0 "no request" 1 "no fault" 2 "fault" 3 "invalid" ;
VAL_ 769 ADS_FcwWaning_301h 0 "no request" 1 "Off" 2 "Standby" 3 "Active_level1" 4 "Active_level2" 5 "Nolicense" 7 "invalid" ;
VAL_ 769 ADS_DMSReminder_301h 0 "no request" 1 "OFF" 2 "Distraction_warning_level 1" 3 "Fatigue_warning_level 1" 4 "Distraction_warning_level 2" 5 "Fatigue_warning_level 2" 6 "Distraction_warning_level 3" 7 "Fatigue_warning_level 3" 8 "Distraction_tellphone_call" 15 "Invalid" ;
VAL_ 769 ADS_AebObjType_301h 0 "no request" 1 "NONE" 2 "CARS" 3 "CYCLIST" 4 "Pedestrian" 5 "Others（通用障碍物）" 7 "invalid" ;
VAL_ 769 ADS_AebFault_301h 0 "no request" 1 "no fault" 2 "fault" 3 "invalid" ;
VAL_ 769 ADS_AebWaning_301h 0 "no request" 1 "Off" 2 "Active" 3 "IBA" 4 "Hold" 5 "Inactive (standby)" 6 "Nolicense" 7 "invalid" ;
VAL_ 769 ADS_RcwWarning_301h 0 "no request" 1 "Off" 2 "Standby" 3 "Active_level1" 4 "Active_level2" 5 "Nolicense" 7 "invalid" ;
VAL_ 769 ADS_RaebFault_301h 0 "no request" 1 "no fault" 2 "fault" 3 "invalid" ;
VAL_ 769 ADS_RaebWarning_301h 0 "no request" 1 "Off" 2 "Active" 3 "Hold" 4 "Inactive (standby)" 5 "Nolicense" 6 "Reserved" 7 "invalid" ;
VAL_ 769 ADS_FctaRightWarning_301h 0 "no request" 1 "Off" 2 "Standby" 3 "Active_level1_Right" 4 "Active_level2_Right" 5 "Nolicense" 7 "invalid" ;
VAL_ 769 ADS_FctaLeftWarning_301h 0 "no request" 1 "Off" 2 "Standby" 3 "Active_level1_Left" 4 "Active_level2_Left" 5 "Nolicense" 7 "invalid" ;
VAL_ 769 ADS_RcwFault_301h 0 "no request" 1 "no fault" 2 "fault" 3 "invalid" ;
VAL_ 769 ADS_FctbRightWarning_301h 0 "no request" 1 "Off" 2 "Active_Right" 3 "IBA" 4 "Hold" 5 "inactive (standby)" 6 "Nolicense" 7 "invalid" ;
VAL_ 769 ADS_FctbLeftWarning_301h 0 "no request" 1 "Off" 2 "Active_Left" 3 "IBA" 4 "Hold" 5 "inactive (standby)" 6 "Nolicense" 7 "invalid" ;
VAL_ 769 ADS_RctaFault_301h 0 "no request" 1 "no fault" 2 "fault" 3 "invalid" ;
VAL_ 769 ADS_RctaRightWarning_301h 0 "no request" 1 "Off" 2 "Standby" 3 "Warning_Right" 4 "Warning_level2_Right" 5 "Nolicense" 6 "Reserved" 7 "invalid" ;
VAL_ 769 ADS_RctaLeftWarning_301h 0 "no request" 1 "Off" 2 "Standby" 3 "Warning_Left" 4 "Warning_level2_Left" 5 "Nolicense" 6 "Reserved" 7 "invalid" ;
VAL_ 769 ADS_LdwWarning_301h 0 "no request" 1 "Off" 2 "Standby" 3 "Ready" 4 "Active_Left" 5 "Active_Right" 6 "Switchoff" 7 "invalid" ;
VAL_ 769 ADS_RctbRightWarning_301h 0 "no request" 1 "Off" 2 "Active_Right" 3 "Hold" 4 "Inactive (Standby)" 5 "Nolicense" 7 "invalid" ;
VAL_ 769 ADS_RctbLeftWarning_301h 0 "no request" 1 "Off" 2 "Active_Left" 3 "Hold" 4 "Inactive (Standby)" 5 "Nolicense" 7 "invalid" ;
VAL_ 769 ADS_LkaFault_301h 0 "no request" 1 "no fault" 2 "fault" 3 "invalid" ;
VAL_ 769 ADS_LKAWarning_301h 0 "no request" 1 "Off" 2 "Standby" 3 "Ready" 4 "Active_Left" 5 "Active_Right" 6 "Switchoff" 7 "invalid" ;
VAL_ 769 ADS_LdwFault_301h 0 "no request" 1 "no fault" 2 "fault" 3 "invalid" ;
VAL_ 769 ADS_BsdFault_301h 0 "no request" 1 "no fault" 2 "fault" 3 "invalid" ;
VAL_ 769 ADS_RightMirrWarningCmd_301h 0 "no request" 1 "no warning" 2 "level 1" 3 "level 2" 4 "reserved" 7 "Invalid" ;
VAL_ 769 ADS_LeftMirrWarningCmd_301h 0 "no request" 1 "no warning" 2 "level 1" 3 "level 2" 4 "reserved" 7 "Invalid" ;
VAL_ 769 ADS_RiFrntDoorWarningCmd_301h 0 "no request" 1 "no warning" 2 "level 1" 3 "level 2" 4 "reserved" 7 "Invalid" ;
VAL_ 769 ADS_LeReDoorWarningCmd_301h 0 "no request" 1 "no warning" 2 "level 1" 3 "level 2" 4 "reserved" 7 "Invalid" ;
VAL_ 769 ADS_LeFrntDoorWarningCmd_301h 0 "no request" 1 "no warning" 2 "level 1" 3 "level 2" 4 "reserved" 7 "Invalid" ;
VAL_ 769 ADS_SpeedLimitWarning_301h 0 "no request" 1 "no_warning" 2 "warning_Relative" 3 "warning_Absolute" 4 "reserved_1" 5 "reserved_2" 6 "reserved_3" 7 "Invalid" ;
VAL_ 769 ADS_DowFault_301h 0 "no request" 1 "no fault" 2 "fault" 3 "invalid" ;
VAL_ 769 ADS_RiReDoorWarningCmd_301h 0 "no request" 1 "no warning" 2 "level 1" 3 "level 2" 4 "reserved" 7 "Invalid" ;
VAL_ 769 ADS_ElkaFault_301h 0 "no request" 1 "no fault" 2 "fault" 3 "invalid" ;
VAL_ 769 ADS_TlaFault_301h 0 "no request" 1 "no fault" 2 "fault" 3 "invalid" ;
VAL_ 769 ADS_TsrFault_301h 0 "no request" 1 "no fault" 2 "fault" 3 "invalid" ;
VAL_ 769 ADS_ElkaWarning_301h 0 "no request" 1 "Off" 2 "Standby" 3 "Ready" 4 "Active_Left" 5 "Active_Right" 6 "Switchoff" 7 "invalid" ;
VAL_ 769 ADS_TlaWarning_301h 0 "no request" 1 "No Warning" 2 "Red Light Warning" 3 "Start Warning" 4 "reserved_1" 5 "reserved_2" 6 "reserved_3" 7 "Invalid" ;
VAL_ 770 ADS_RPAOnlineOrNot_302h 0 "None" 1 "rolling counter" 2 "rolling counter" 3 "rolling counter" 4 "rolling counter" 5 "rolling counter" 6 "rolling counter" 7 "rolling counter" 8 "rolling counter" 9 "rolling counter" 10 "rolling counter" 11 "rolling counter" 12 "rolling counter" 13 "rolling counter" 14 "rolling counter" 15 "rolling counter" 16 "rolling counter" 17 "rolling counter" 18 "rolling counter" 19 "rolling counter" 20 "rolling counter" 21 "rolling counter" 22 "rolling counter" 23 "rolling counter" 24 "rolling counter" 25 "rolling counter" 26 "rolling counter" 27 "rolling counter" 28 "rolling counter" 29 "rolling counter" 30 "rolling counter" 31 "rolling counter" 32 "rolling counter" 33 "rolling counter" 34 "rolling counter" 35 "rolling counter" 36 "rolling counter" 37 "rolling counter" 38 "rolling counter" 39 "rolling counter" 40 "rolling counter" 41 "rolling counter" 42 "rolling counter" 43 "rolling counter" 44 "rolling counter" 45 "rolling counter" 46 "rolling counter" 47 "rolling counter" 48 "rolling counter" 49 "rolling counter" 50 "rolling counter" 51 "rolling counter" 52 "rolling counter" 53 "rolling counter" 54 "rolling counter" 55 "rolling counter" 56 "rolling counter" 57 "rolling counter" 58 "rolling counter" 59 "rolling counter" 60 "rolling counter" 61 "rolling counter" 62 "rolling counter" 63 "rolling counter" 64 "rolling counter" 65 "rolling counter" 66 "rolling counter" 67 "rolling counter" 68 "rolling counter" 69 "rolling counter" 70 "rolling counter" 71 "rolling counter" 72 "rolling counter" 73 "rolling counter" 74 "rolling counter" 75 "rolling counter" 76 "rolling counter" 77 "rolling counter" 78 "rolling counter" 79 "rolling counter" 80 "rolling counter" 81 "rolling counter" 82 "rolling counter" 83 "rolling counter" 84 "rolling counter" 85 "rolling counter" 86 "rolling counter" 87 "rolling counter" 88 "rolling counter" 89 "rolling counter" 90 "rolling counter" 91 "rolling counter" 92 "rolling counter" 93 "rolling counter" 94 "rolling counter" 95 "rolling counter" 96 "rolling counter" 97 "rolling counter" 98 "rolling counter" 99 "rolling counter" 100 "rolling counter" 101 "rolling counter" 102 "rolling counter" 103 "rolling counter" 104 "rolling counter" 105 "rolling counter" 106 "rolling counter" 107 "rolling counter" 108 "rolling counter" 109 "rolling counter" 110 "rolling counter" 111 "rolling counter" 112 "rolling counter" 113 "rolling counter" 114 "rolling counter" 115 "rolling counter" 116 "rolling counter" 117 "rolling counter" 118 "rolling counter" 119 "rolling counter" 120 "rolling counter" 121 "rolling counter" 122 "rolling counter" 123 "rolling counter" 124 "rolling counter" 125 "rolling counter" 126 "rolling counter" 127 "rolling counter" 128 "rolling counter" 129 "rolling counter" 130 "rolling counter" 131 "rolling counter" 132 "rolling counter" 133 "rolling counter" 134 "rolling counter" 135 "rolling counter" 136 "rolling counter" 137 "rolling counter" 138 "rolling counter" 139 "rolling counter" 140 "rolling counter" 141 "rolling counter" 142 "rolling counter" 143 "rolling counter" 144 "rolling counter" 145 "rolling counter" 146 "rolling counter" 147 "rolling counter" 148 "rolling counter" 149 "rolling counter" 150 "rolling counter" 151 "rolling counter" 152 "rolling counter" 153 "rolling counter" 154 "rolling counter" 155 "rolling counter" 156 "rolling counter" 157 "rolling counter" 158 "rolling counter" 159 "rolling counter" 160 "rolling counter" 161 "rolling counter" 162 "rolling counter" 163 "rolling counter" 164 "rolling counter" 165 "rolling counter" 166 "rolling counter" 167 "rolling counter" 168 "rolling counter" 169 "rolling counter" 170 "rolling counter" 171 "rolling counter" 172 "rolling counter" 173 "rolling counter" 174 "rolling counter" 175 "rolling counter" 176 "rolling counter" 177 "rolling counter" 178 "rolling counter" 179 "rolling counter" 180 "rolling counter" 181 "rolling counter" 182 "rolling counter" 183 "rolling counter" 184 "rolling counter" 185 "rolling counter" 186 "rolling counter" 187 "rolling counter" 188 "rolling counter" 189 "rolling counter" 190 "rolling counter" 191 "rolling counter" 192 "rolling counter" 193 "rolling counter" 194 "rolling counter" 195 "rolling counter" 196 "rolling counter" 197 "rolling counter" 198 "rolling counter" 199 "rolling counter" 200 "rolling counter" 201 "rolling counter" 202 "rolling counter" 203 "rolling counter" 204 "rolling counter" 205 "rolling counter" 206 "rolling counter" 207 "rolling counter" 208 "rolling counter" 209 "rolling counter" 210 "rolling counter" 211 "rolling counter" 212 "rolling counter" 213 "rolling counter" 214 "rolling counter" 215 "rolling counter" 216 "rolling counter" 217 "rolling counter" 218 "rolling counter" 219 "rolling counter" 220 "rolling counter" 221 "rolling counter" 222 "rolling counter" 223 "rolling counter" 224 "rolling counter" 225 "rolling counter" 226 "rolling counter" 227 "rolling counter" 228 "rolling counter" 229 "rolling counter" 230 "rolling counter" 231 "rolling counter" 232 "rolling counter" 233 "rolling counter" 234 "rolling counter" 235 "rolling counter" 236 "rolling counter" 237 "rolling counter" 238 "rolling counter" 239 "rolling counter" 240 "rolling counter" 241 "rolling counter" 242 "rolling counter" 243 "rolling counter" 244 "rolling counter" 245 "rolling counter" 246 "rolling counter" 247 "rolling counter" 248 "rolling counter" 249 "rolling counter" 250 "rolling counter" 251 "rolling counter" 252 "rolling counter" 253 "rolling counter" 254 "rolling counter" 255 "rolling counter" ;
VAL_ 770 ADS_VehParkMod_302h 0 "None" 1 "车头泊入" 2 "车尾泊入" ;
VAL_ 770 ADS_RpaParkAuthn_302h 0 "不允许手机操作" 1 "允许手机操作" ;
VAL_ 770 ADS_ParkDirCfm_302h 0 "None" 1 "ParallelLeft_confirm" 2 "ParallelRight_confirm" 3 "PerpendicularForward_confirm" 4 "PerpendicularLeftForward_confirm" 5 "PerpendicularRightForward_confirm" 6 "PerpendicularLeftBack_confirm" 7 "PerpendicularRightBack_confirm" 8 "PerpendicularBack_confirm" ;
VAL_ 770 ADS_RemParkPatSel_302h 0 "NONE" 1 "PARK_IN_REQUEST_CONFIRMED" 2 "PARK_OUT_REQUEST_CONFIRMED" 3 "RESERVED" ;
VAL_ 770 ADS_ObstclDst_302h 0 "None" 1 "前左障碍物距离Level1" 2 "前左障碍物距离Level2" 3 "前左障碍物距离Level3" 4 "前障碍物距离Level1" 5 "前障碍物距离Level2" 6 "前障碍物距离Level3" 7 "前右障碍物距离Level1" 8 "前右障碍物距离Level2" 9 "前右障碍物距离Level3" 10 "后左障碍物距离Level1" 11 "后左障碍物距离Level2" 12 "后左障碍物距离Level3" 13 "后障碍物距离Level1" 14 "后障碍物距离Level2" 15 "后障碍物距离Level3" 16 "后右障碍物距离Level1" 17 "后右障碍物距离Level2" 18 "后右障碍物距离Level3" 19 "Reserved" 20 "Reserved" 21 "Reserved" 22 "Reserved" 23 "Reserved" 24 "Reserved" 25 "Reserved" 26 "Reserved" 27 "Reserved" 28 "Reserved" 29 "Reserved" 30 "Reserved" 31 "Reserved" ;
VAL_ 770 ADS_AutEve_302h 1 "MOP_HMI_NULL" 2 "MOP_HMI_CRUISE" 3 "MOP_HMI_BYPASS" 4 "MOP_HMI_STOP_MAN" 5 "MOP_HMI_STOP_CAR" 6 "MOP_HMI_FOLLOW" 7 "MOP_HMI_MEET" 8 "MOP_HMI_TIME_OUT" 9 "Reserved" 10 "Reserved" 11 "Reserved" 12 "Reserved" 13 "Reserved" 14 "Reserved" 15 "Reserved" ;
VAL_ 770 ADS_parkInterruptDuration_302h 0 "None（无倒计时或倒计时已结束）" 1 "30s倒计时，精度为1s" 2 "30s倒计时，精度为1s" 3 "30s倒计时，精度为1s" 4 "30s倒计时，精度为1s" 5 "30s倒计时，精度为1s" 6 "30s倒计时，精度为1s" 7 "30s倒计时，精度为1s" 8 "30s倒计时，精度为1s" 9 "30s倒计时，精度为1s" 10 "30s倒计时，精度为1s" 11 "30s倒计时，精度为1s" 12 "30s倒计时，精度为1s" 13 "30s倒计时，精度为1s" 14 "30s倒计时，精度为1s" 15 "30s倒计时，精度为1s" 16 "30s倒计时，精度为1s" 17 "30s倒计时，精度为1s" 18 "30s倒计时，精度为1s" 19 "30s倒计时，精度为1s" 20 "30s倒计时，精度为1s" 21 "30s倒计时，精度为1s" 22 "30s倒计时，精度为1s" 23 "30s倒计时，精度为1s" 24 "30s倒计时，精度为1s" 25 "30s倒计时，精度为1s" 26 "30s倒计时，精度为1s" 27 "30s倒计时，精度为1s" 28 "30s倒计时，精度为1s" 29 "30s倒计时，精度为1s" 30 "30s倒计时，精度为1s" 49 "Reserved" 50 "Reserved" 51 "Reserved" 52 "Reserved" 53 "Reserved" 54 "Reserved" 55 "Reserved" 56 "Reserved" 57 "Reserved" 58 "Reserved" 59 "Reserved" 60 "Reserved" 61 "Reserved" 62 "Reserved" 63 "Reserved" 64 "Reserved" 65 "Reserved" 66 "Reserved" 67 "Reserved" 68 "Reserved" 69 "Reserved" 70 "Reserved" 71 "Reserved" 72 "Reserved" 73 "Reserved" 74 "Reserved" 75 "Reserved" 76 "Reserved" 77 "Reserved" 78 "Reserved" 79 "Reserved" 80 "Reserved" 81 "Reserved" 82 "Reserved" 83 "Reserved" 84 "Reserved" 85 "Reserved" 86 "Reserved" 87 "Reserved" 88 "Reserved" 89 "Reserved" 90 "Reserved" 91 "Reserved" 92 "Reserved" 93 "Reserved" 94 "Reserved" 95 "Reserved" 96 "Reserved" 97 "Reserved" 98 "Reserved" 99 "Reserved" 100 "Reserved" 101 "Reserved" 102 "Reserved" 103 "Reserved" 104 "Reserved" 105 "Reserved" 106 "Reserved" 107 "Reserved" 108 "Reserved" 109 "Reserved" 110 "Reserved" 111 "Reserved" 112 "Reserved" 113 "Reserved" 114 "Reserved" 115 "Reserved" 116 "Reserved" 117 "Reserved" 118 "Reserved" 119 "Reserved" 120 "Reserved" 121 "Reserved" 122 "Reserved" 123 "Reserved" 124 "Reserved" 125 "Reserved" 126 "Reserved" 127 "Reserved" 128 "Reserved" 129 "Reserved" 130 "Reserved" 131 "Reserved" 132 "Reserved" 133 "Reserved" 134 "Reserved" 135 "Reserved" 136 "Reserved" 137 "Reserved" 138 "Reserved" 139 "Reserved" 140 "Reserved" 141 "Reserved" 142 "Reserved" 143 "Reserved" 144 "Reserved" 145 "Reserved" 146 "Reserved" 147 "Reserved" 148 "Reserved" 149 "Reserved" 150 "Reserved" 151 "Reserved" 152 "Reserved" 153 "Reserved" 154 "Reserved" 155 "Reserved" 156 "Reserved" 157 "Reserved" 158 "Reserved" 159 "Reserved" 160 "Reserved" 161 "Reserved" 162 "Reserved" 163 "Reserved" 164 "Reserved" 165 "Reserved" 166 "Reserved" 167 "Reserved" 168 "Reserved" 169 "Reserved" 170 "Reserved" 171 "Reserved" 172 "Reserved" 173 "Reserved" 174 "Reserved" 175 "Reserved" 176 "Reserved" 177 "Reserved" 178 "Reserved" 179 "Reserved" 180 "Reserved" 181 "Reserved" 182 "Reserved" 183 "Reserved" 184 "Reserved" 185 "Reserved" 186 "Reserved" 187 "Reserved" 188 "Reserved" 189 "Reserved" 190 "Reserved" 191 "Reserved" 192 "Reserved" 193 "Reserved" 194 "Reserved" 195 "Reserved" 196 "Reserved" 197 "Reserved" 198 "Reserved" 199 "Reserved" 200 "Reserved" 201 "Reserved" 202 "Reserved" 203 "Reserved" 204 "Reserved" 205 "Reserved" 206 "Reserved" 207 "Reserved" 208 "Reserved" 209 "Reserved" 210 "Reserved" 211 "Reserved" 212 "Reserved" 213 "Reserved" 214 "Reserved" 215 "Reserved" 216 "Reserved" 217 "Reserved" 218 "Reserved" 219 "Reserved" 220 "Reserved" 221 "Reserved" 222 "Reserved" 223 "Reserved" 224 "Reserved" 225 "Reserved" 226 "Reserved" 227 "Reserved" 228 "Reserved" 229 "Reserved" 230 "Reserved" 231 "Reserved" 232 "Reserved" 233 "Reserved" 234 "Reserved" 235 "Reserved" 236 "Reserved" 237 "Reserved" 238 "Reserved" 239 "Reserved" 240 "Reserved" 241 "Reserved" 242 "Reserved" 243 "Reserved" 244 "Reserved" 245 "Reserved" 246 "Reserved" 247 "Reserved" 248 "Reserved" 249 "Reserved" 250 "Reserved" 251 "Reserved" 252 "Reserved" 253 "Reserved" 254 "Reserved" 255 "Reserved" ;
VAL_ 770 ADS_ParkOutDir_ParaLe_302h 0 "不可用" 1 "可用" ;
VAL_ 770 ADS_ParkStMac_302h 0 "STATE_OFF" 1 "STATE_RDA_FORWARD" 2 "STATE_RDA_BACK" 3 "STATE_RDA_ABORT" 4 "STATE_RDA_FINISH" 5 "STATE_CRUISE_FINISH" 6 "STATE_APA_SUSPEND" 7 "STATE_APA_SEARCH" 8 "STATE_APA_STANDBY" 9 "STATE_PARK_OUT" 10 "STATE_PARK_IN" 11 "STATE_APA_FINISH" 12 "STATE_PAUSE" 13 "STATE_OVERRIDE" 14 "预留1" 15 "Reserved" 16 "Reserved" 17 "Reserved" 18 "Reserved" 19 "Reserved" 20 "Reserved" 21 "Reserved" 22 "Reserved" 23 "Reserved" 24 "Reserved" 25 "Reserved" 26 "Reserved" 27 "Reserved" 28 "Reserved" 29 "Reserved" 30 "Reserved" 31 "Reserved" ;
VAL_ 770 APA_ResuAvl_302h 0 "默认" 1 "自检过程中" 2 "自检成功，to active满足" 3 "自检不成功，to active不满足" ;
VAL_ 770 APA_RPAFctUnavlMsg_1_302h 0 "none" 1 "happened 出现该原因" ;
VAL_ 770 ADS_ParkOutDir_PerpBack_302h 0 "不可用" 1 "可用" ;
VAL_ 770 ADS_ParkOutDir_PerpRiBack_302h 0 "不可用" 1 "可用" ;
VAL_ 770 ADS_ParkOutDir_PerpLeBack_302h 0 "不可用" 1 "可用" ;
VAL_ 770 ADS_ParkOutDir_PerpRiFwd_302h 0 "不可用" 1 "可用" ;
VAL_ 770 ADS_ParkOutDir_PerpLeFwd_302h 0 "不可用" 1 "可用" ;
VAL_ 770 ADS_ParkOutDir_PerpFwd_302h 0 "不可用" 1 "可用" ;
VAL_ 770 ADS_ParkOutDir_ParaRi_302h 0 "不可用" 1 "可用" ;
VAL_ 770 APA_RPAFctUnavlMsg_9_302h 0 "none" 1 "happened 出现该原因" ;
VAL_ 770 APA_RPAFctUnavlMsg_8_302h 0 "none" 1 "happened 出现该原因" ;
VAL_ 770 APA_RPAFctUnavlMsg_7_302h 0 "none" 1 "happened 出现该原因" ;
VAL_ 770 APA_RPAFctUnavlMsg_6_302h 0 "none" 1 "happened 出现该原因" ;
VAL_ 770 APA_RPAFctUnavlMsg_5_302h 0 "none" 1 "happened 出现该原因" ;
VAL_ 770 APA_RPAFctUnavlMsg_4_302h 0 "none" 1 "happened 出现该原因" ;
VAL_ 770 APA_RPAFctUnavlMsg_3_302h 0 "none" 1 "happened 出现该原因" ;
VAL_ 770 APA_RPAFctUnavlMsg_2_302h 0 "none" 1 "happened 出现该原因" ;
VAL_ 770 APA_RPAFctUnavlMsg_17_302h 0 "none" 1 "happened 出现该原因" ;
VAL_ 770 APA_RPAFctUnavlMsg_16_302h 0 "none" 1 "happened 出现该原因" ;
VAL_ 770 APA_RPAFctUnavlMsg_15_302h 0 "none" 1 "happened 出现该原因" ;
VAL_ 770 APA_RPAFctUnavlMsg_14_302h 0 "none" 1 "happened 出现该原因" ;
VAL_ 770 APA_RPAFctUnavlMsg_13_302h 0 "none" 1 "happened 出现该原因" ;
VAL_ 770 APA_RPAFctUnavlMsg_12_302h 0 "none" 1 "happened 出现该原因" ;
VAL_ 770 APA_RPAFctUnavlMsg_11_302h 0 "none" 1 "happened 出现该原因" ;
VAL_ 770 APA_RPAFctUnavlMsg_10_302h 0 "none" 1 "happened 出现该原因" ;
VAL_ 770 APA_RPAFctUnavlMsg_25_302h 0 "none" 1 "happened 出现该原因" ;
VAL_ 770 APA_RPAFctUnavlMsg_24_302h 0 "none" 1 "happened 出现该原因" ;
VAL_ 770 APA_RPAFctUnavlMsg_23_302h 0 "none" 1 "happened 出现该原因" ;
VAL_ 770 APA_RPAFctUnavlMsg_22_302h 0 "none" 1 "happened 出现该原因" ;
VAL_ 770 APA_RPAFctUnavlMsg_21_302h 0 "none" 1 "happened 出现该原因" ;
VAL_ 770 APA_RPAFctUnavlMsg_20_302h 0 "none" 1 "happened 出现该原因" ;
VAL_ 770 APA_RPAFctUnavlMsg_19_302h 0 "none" 1 "happened 出现该原因" ;
VAL_ 770 APA_RPAFctUnavlMsg_18_302h 0 "none" 1 "happened 出现该原因" ;
VAL_ 770 APA_RPACnclMsg_8_302h 0 "none" 1 "happened 出现该原因" ;
VAL_ 770 APA_RPACnclMsg_7_302h 0 "none" 1 "happened 出现该原因" ;
VAL_ 770 APA_RPACnclMsg_6_302h 0 "none" 1 "happened 出现该原因" ;
VAL_ 770 APA_RPACnclMsg_5_302h 0 "none" 1 "happened 出现该原因" ;
VAL_ 770 APA_RPACnclMsg_4_302h 0 "none" 1 "happened 出现该原因" ;
VAL_ 770 APA_RPACnclMsg_3 0 "none" 1 "happened 出现该原因" ;
VAL_ 770 APA_RPACnclMsg_2_302h 0 "none" 1 "happened 出现该原因" ;
VAL_ 770 APA_RPACnclMsg_1_302h 0 "none" 1 "happened 出现该原因" ;
VAL_ 770 APA_RPACnclMsg_16_302h 0 "none" 1 "happened 出现该原因" ;
VAL_ 770 APA_RPACnclMsg_15_302h 0 "none" 1 "happened 出现该原因" ;
VAL_ 770 APA_RPACnclMsg_14_302h 0 "none" 1 "happened 出现该原因" ;
VAL_ 770 APA_RPACnclMsg_13_302h 0 "none" 1 "happened 出现该原因" ;
VAL_ 770 APA_RPACnclMsg_12_302h 0 "none" 1 "happened 出现该原因" ;
VAL_ 770 APA_RPACnclMsg_11_302h 0 "none" 1 "happened 出现该原因" ;
VAL_ 770 APA_RPACnclMsg_10_302h 0 "none" 1 "happened 出现该原因" ;
VAL_ 770 APA_RPACnclMsg_9_302h 0 "none" 1 "happened 出现该原因" ;
VAL_ 770 APA_RPAPauseMsg_4_302h 0 "none" 1 "happened 出现该原因" ;
VAL_ 770 APA_RPAPauseMsg_3_302h 0 "none" 1 "happened 出现该原因" ;
VAL_ 770 APA_RPAPauseMsg_2_302h 0 "none" 1 "happened 出现该原因" ;
VAL_ 770 APA_RPAPauseMsg_1_302h 0 "none" 1 "happened 出现该原因" ;
VAL_ 770 APA_RPACnclMsg_20_302h 0 "none" 1 "happened 出现该原因" ;
VAL_ 770 APA_RPACnclMsg_19_302h 0 "none" 1 "happened 出现该原因" ;
VAL_ 770 APA_RPACnclMsg_18_302h 0 "none" 1 "happened 出现该原因" ;
VAL_ 770 APA_RPACnclMsg_17_302h 0 "none" 1 "happened 出现该原因" ;
VAL_ 770 APA_RPAPauseMsg_10_302h 0 "none" 1 "happened 出现该原因" ;
VAL_ 770 APA_RPAPauseMsg_9_302h 0 "none" 1 "happened 出现该原因" ;
VAL_ 770 APA_RPAPauseMsg_8_302h 0 "none" 1 "happened 出现该原因" ;
VAL_ 770 APA_RPAPauseMsg_7_302h 0 "none" 1 "happened 出现该原因" ;
VAL_ 770 APA_RPAPauseMsg_6_302h 0 "none" 1 "happened 出现该原因" ;
VAL_ 770 APA_RPAPauseMsg_5_302h 0 "none" 1 "happened 出现该原因" ;
VAL_ 770 ADS_MnvrOrintChng2_302h 0 "None" 1 "Parallel" 2 "Cross" 3 "斜列" ;
VAL_ 770 ADS_MnvrOrintChng1_302h 0 "None" 1 "Parallel" 2 "Cross" 3 "斜列" ;
VAL_ 770 ADS_TcsActvSts_302h 0 "NotActive" 1 "Active" ;
VAL_ 770 ADS_VdcActvSts_302h 0 "NotActive" 1 "Active" ;
VAL_ 770 ADS_ParkChkSrc_Posn1_302h 0 "None" 1 "camera" 2 "lidar" 3 "mixed" 4 "Reserved" 5 "Reserved" 6 "Reserved" 7 "Reserved" ;
VAL_ 770 ADS_TarParkSt_Posn1_302h 0 "None" 1 "Invalid" 2 "Valid" 3 "Selectable" 4 "Selected" 5 "Reserved" 6 "Reserved" 7 "Reserved" ;
VAL_ 770 ADS_ParkChkSrc_Posn2_302h 0 "None" 1 "camera" 2 "lidar" 3 "mixed" ;
VAL_ 770 ADS_TarParkSt_Posn2_302h 0 "None" 1 "Invalid" 2 "Valid" 3 "Selectable" 4 "Selected" 5 "Reserved" 6 "Reserved" 7 "Reserved" ;
VAL_ 771 TimeGapAdjustment_33Dh 0 "no request" 1 "Levell" 2 "Level2" 3 "Level3" 4 "Level4" 5 "Levels" 6 "Reserved" 7 "invalid" ;
VAL_ 777 ISGF_ErrLvl 0 "No Error" 1 "Err_level1" 2 "Err_level2" 3 "Err_level3" 4 "Err_level4" 5 "Err_level5" 6 "Err_level6" ;
VAL_ 783 ADCC_SysReadySts 0 "Ready" 1 "not Ready" 2 "Temporary_Failure" 3 "Permanent_Failure" 4 "Reserved" 5 "Reserved" ;
VAL_ 787 PassSitPosnSts_313h 0 "Not Active" 1 "Location1" 2 "Location2" 3 "Location3" ;
VAL_ 787 ChrgHoodSts 0 "Close" 1 "Open" ;
VAL_ 788 ADS_2_AEBStatus 0 "OFF" 1 "ON" 2 "Failure" 3 "available" 4 "active" 5 "pre-fill" 6 "blindness" ;
VAL_ 788 ADS_2_FCWStatus 0 "no request" 1 "level 1(low)" 2 "level 2(middle)" 3 "level 3(high)" 4 "reserved" 5 "reserved" 6 "reserved" 7 "reserved" ;
VAL_ 788 FCM_2_IHCfunctionSts 0 "Off" 1 "Standby" 2 "Active" 3 "Fault" 4 "Reserved" 5 "Reserved" 6 "Reserved" 7 "Reserved" ;
VAL_ 789 ATCM_DriveModeSw 0 "Not Active" 1 "Plus" 2 "Minus" 3 "Reserved" ;
VAL_ 789 ATCM_XModeSw 0 "Not_Active" 1 "ON" 2 "OFF" 3 "Reserved" ;
VAL_ 789 ATCM_SwitchUTurnModeSet 0 "Release" 1 "Press" ;
VAL_ 789 ATCM_ASU_LiftSet 0 "Release" 1 "Plus" ;
VAL_ 789 ATCM_ASU_LowerSet 0 "Not Active" 1 "Minus" ;
VAL_ 789 ATCM_ESP_OFF_SW 0 "Release" 1 "Press" ;
VAL_ 789 ATCM_AVH_SW 0 "Release" 1 "Press" ;
VAL_ 789 ATCM_AVM 0 "Release" 1 "Press" ;
VAL_ 794 ADS_3_ICATextinfo 0 "No dispaly" 1 "TJAICA Activated" 2 "TJAICA Cannot Be Activated" 3 "TJAICA Cancelled" 4 "TJAICA failure" 5 "TJAICA Suspend" 6 "TJAICA resumed" 7 "TJAICA degrade to ACC" 8 "Urgent TOR request" 9 "uncentered" 10 "Too Large curve" 11 "Abnormal tire pressure" 12 "Camera block" 13 "Master switch is off" 14 "reserved" 15 "reserved" ;
VAL_ 794 ADS_3_ICAStatus 0 "Off" 1 "Passive" 2 "Standby" 3 "Active" 4 "Failure" 5 "Suspend" 6 "reserved" 7 "reserved" ;
VAL_ 794 ADS_3_DriverHandsoffWarning 0 "None" 1 "Warning 1 for stage1" 2 "Warning 2  for stage2" 3 "Warning 3 for stage3(TOR)" 4 "Warning 4 for stage4(Punishment)" 5 "reserved" 6 "reserved" 7 "reserved" ;
VAL_ 794 ADS_3_ACCSts 0 "Off" 1 "Passive" 2 "Standby" 3 "Active_Control" 4 "Brake Only" 5 "Override" 6 "Stand Wait" 7 "failure" 8 "Stand Active" 9 "reserved" 10 "reserved" 11 "reserved" 12 "reserved" 13 "reserved" 14 "reserved" 15 "reserved" ;
VAL_ 794 ADS_3_LKSSts 0 "OFF" 1 "Standby" 2 "Active" 3 "Failure" 4 "Passive" 5 "Reserved" 6 "Reserved" 7 "Reserved" ;
VAL_ 794 ADS_3_LKSMod 0 "Off" 1 "Warning" 2 "Warning+intervention" 3 "reserved" ;
VAL_ 794 ADS_3_LKSRightTrackingSt 0 "Inactive" 1 "Lane Tracking" 2 "Intervention" 3 "warning" ;
VAL_ 794 ADS_3_LKSLeftTrackingSt 0 "Inactive" 1 "Lane Tracking" 2 "Intervention" 3 "warning" ;
VAL_ 794 ADS_3_ELKSts 0 "OFF" 1 "Standby" 2 "Active" 3 "Failure" 4 "Passive" 5 "Reserved" 6 "Reserved" 7 "Reserved" ;
VAL_ 794 ADS_3_ELKRightActiveSt 0 "no warning" 1 "tracking" 2 "intervention" ;
VAL_ 794 ADS_3_ELKLeftActiveSt 0 "no warning" 1 "tracking" 2 "intervention" ;
VAL_ 794 ADS_HNOPSts 0 "Off" 1 "Passive" 2 "Ready" 3 "Active control" 4 "Longitudinal Suspend" 5 "TOR" 6 "Safe stop" 7 "Failure" 8 "Lateral Suspend" ;
VAL_ 811 BMS_Chg_Sts_32Bh 1 "Parking chagre" 2 "Driving charge" 3 "no charge" 4 "charge complete" 14 "Abnomal" 15 "Invalid" ;
VAL_ 819 ADS_4_AEBReqType 0 "NoReq" 1 "AEBm" 2 "AEBp" 3 "AEBVru" 4 "EBA" 5 "LTA" 6 "CPTA" 7 "Reserved" ;
VAL_ 819 ADS_4_AEBStatus 0 "OFF" 1 "ON" 2 "Failure" 3 "available" 4 "active" 5 "pre-fill" 6 "blindness" 7 "Reserved" ;
VAL_ 819 ADS_4_ACCSts 0 "Off" 1 "Passive" 2 "Standby" 3 "Active_Control" 4 "BrakeOnly" 5 "Override" 6 "StandWait" 7 "failure" 8 "StandActive" 9 "reserved" 10 "reserved" 11 "reserved" 12 "reserved" 13 "reserved" 14 "reserved" 15 "reserved" ;
VAL_ 819 ADS_4_TimeGapSet 0 "None" 1 "Time Gap1" 2 "Time Gap2" 3 "Time Gap3" 4 "Time Gap4" 5 "Time Gap5" 6 "Reserved" 7 "Reserved" ;
VAL_ 819 ADS_4_FcwMode 0 "OFF" 1 "ON" 2 "Failure" 3 "Active" 4 "blindness" 5 "Reserved" 6 "Reserved" 7 "Reserved" ;
VAL_ 819 ADS_4_DAIStatus 0 "On" 1 "Off" 2 "Failure" 3 "None" ;
VAL_ 819 ADS_4_ACCTextMessage 0 "No Display" 1 "ACC Activated" 2 "ACC Cannot Be Activated" 3 "ACC Cancelled" 4 "ACC failure" 5 "Weather abnormal" 6 "Driver Override" 7 "Active Decelerate" 8 "Cruise speed can not be added" 9 "ACC abort and take over request" 10 "Maximum decelerate to ahead speed sign" 11 "System add timegap to front big vehicle" 12 "Cut in reminder" 13 "Large curve remider" 14 "Auto drive off reminder" 15 "takeover timeout" ;
VAL_ 819 ADS_4_LongiTakeOverReq 0 "No Request" 1 "Request" ;
VAL_ 819 ADS_4_SetSpdUnit 0 "Km/h" 1 "Mile/h" ;
VAL_ 819 ADS_4_GoNotifier 0 "None" 1 "Go Notifier" 2 "Go Visual Notifier" 3 "Handson visual warning" 4 "Handson and DMS warning" 5 "Press gas reminder" 6 "Reserved" 7 "Reserved" ;
VAL_ 819 ADS_4_DAISts 0 "None" 1 "active Drive Off" 2 "Reserved" 3 "Reserved" ;
VAL_ 819 ADS_4_Radar_textinfo 0 "Radar normal" 1 "Radar failure" 2 "Radar blocked" 3 "Reserved" 4 "Reserved" 5 "Reserved" 6 "Reserved" 7 "Reserved" ;
VAL_ 819 ADS_4_SCF_PopoverReq 0 "No Request" 1 "Driver confirm Request" ;
VAL_ 819 ADS_4_DrvrCfmSCFDispFb 0 "not confirmed" 1 "confirme" ;
VAL_ 819 ADS_4_SCF_SpdLimUnit 0 "Unknown" 1 "km/h" 2 "Miles/h" 3 "Reserved" ;
VAL_ 819 ADS_4_SCF_SpdLimSts 0 "OFF" 1 "STANDBY" 2 "ACTIVE" 3 "REVERSIBLE_FAILURE" 4 "IREVERSIBLE FAILURE" 5 "Reserved" 6 "Reserved" 7 "Reserved" ;
VAL_ 819 ADS_4_ACCObjTyp 0 "No type" 1 "Car" 2 "Truck" 3 "Motorcycle" 4 "Pedestrian" 5 "Cyclist" 6 "Bus" 7 "Reserved" 8 "Reserved" 9 "Reserved" 10 "Reserved" 11 "Reserved" 12 "Reserved" 13 "Reserved" 14 "Reserved" 15 "Reserved" ;
VAL_ 819 ADS_4_FrntFarObjTyp 0 "No type" 1 "Car" 2 "Truck" 3 "Motorcycle" 4 "Pedestrian" 5 "Cyclist" 6 "Bus" 7 "Reserved" 8 "Reserved" 9 "Reserved" 10 "Reserved" 11 "Reserved" 12 "Reserved" 13 "Reserved" 14 "Reserved" 15 "Reserved" ;
VAL_ 819 ADS_4_FrntFarObjID 0 "Invalid" 1 "Valid" ;
VAL_ 819 ADS_4_Resd 0 "Not available" 1 "available" ;
VAL_ 819 ADS_4_ACCObjID 0 "Invalid" 1 "Valid" ;
VAL_ 819 ADS_4_Resd_1 0 "Not available" 1 "available" ;
VAL_ 819 ADS_4_LeObjID 0 "Invalid" 1 "Valid" ;
VAL_ 819 ADS_4_LeObjTyp 0 "No type" 1 "Car" 2 "Truck" 3 "Motorcycle" 4 "Pedestrian" 5 "Cyclist" 6 "Bus" 7 "Reserved" 8 "Reserved" 9 "Reserved" 10 "Reserved" 11 "Reserved" 12 "Reserved" 13 "Reserved" 14 "Reserved" 15 "Reserved" ;
VAL_ 819 ADS_4_RiObjID 0 "Invalid" 1 "Valid" ;
VAL_ 819 ADS_4_RiObjTyp 0 "No type" 1 "Car" 2 "Truck" 3 "Motorcycle" 4 "Pedestrian" 5 "Cyclist" 6 "Bus" 7 "Reserved" 8 "Reserved" 9 "Reserved" 10 "Reserved" 11 "Reserved" 12 "Reserved" 13 "Reserved" 14 "Reserved" 15 "Reserved" ;
VAL_ 819 ADS_4_SCFSwtSet 0 "None" 1 "ON" 2 "Off" 3 "reserved" ;
VAL_ 819 ADS_4_AEBSettingSt 0 "None" 1 "ON" 2 "Off" 3 "reserved" ;
VAL_ 819 ADS_4_FCWSettingSt 0 "None" 1 "Off" 2 "high" 3 "middle" 4 "low" 5 "reserved" 6 "reserved" 7 "reserved" ;
VAL_ 819 NOPTextinfo_333h 0 "No_display" 1 "NOP_Activated" 2 "NOP_Cannot_Be_Activated" 3 "NOP_Cancelled" 4 "NOP_failure" 5 "NOP_Suspend" 6 "NOP_resumed" 7 "NOP_degrade_to_LCC" 8 "Urgent_TOR_request" 9 "reserved" 10 "reserved" 11 "reserved" 12 "reserved" 13 "reserved" 14 "reserved" 15 "reserved" ;
VAL_ 819 ADS_4_CruiseAccelerateSts 0 "None" 1 "Accelerating" 2 "Decelerating" 3 "Reserved" ;
VAL_ 819 ADS_4_DAISwtSet 0 "None" 1 "ON" 2 "Off" 3 "reserved" ;
VAL_ 819 FCM_FRM_DAIONOFFSts_333h 0 "Not_active" 1 "ON" 2 "OFF" 3 "Reserved" ;
VAL_ 819 FCTAFCTBONOFFSts_333h 0 "OFF" 1 "Warning" 2 "Warning_and_braking" 3 "None" ;
VAL_ 819 TRA_Operation_Status_333h 0 "Off" 1 "No_Ready" 2 "Ready" 3 "Prepare" 4 "Reversing" 5 "Reversing_Suspend" 6 "Finish_Success" 7 "Finish_Failure" 8 "Finish_Termination" 9 "Error_Int_Fault" 10 "Error_Ext_Fault" 11 "Reserved" 12 "Reserved" 13 "Reserved" 14 "Reserved" 15 "Reserved" ;
VAL_ 819 LightingBlueONOFFSts_333h 0 "Not_active" 1 "ON" 2 "OFF" 3 "Reserved" ;
VAL_ 819 ADCC_AdsLowPowSts_333h 0 "Not_active" 1 "ON" 2 "OFF" ;
VAL_ 819 DataCollectionONOFFStS_333h 0 "Not_active" 1 "ON" 2 "OFF" 3 "Reserved" ;
VAL_ 819 FCM_10_TLITrfcLi_333h 0 "No_display" 1 "Green" 2 "Yelllow" 3 "red" ;
VAL_ 821 ADS_5_ILOASts 0 "Off" 1 "On" 2 "Evasioning" 3 "Retreat" 4 "Evasion finished" 5 "None" 6 "Reserved" 7 "Reserved" ;
VAL_ 821 ADS_5_ICAQuitReason 0 "None" 1 "Bad Weather" 2 "Large curve" 3 "ODD not meet" 4 "reserved" 5 "reserved" 6 "reserved" 7 "reserved" ;
VAL_ 821 ADS_5_ISLISt 0 "OFF" 1 "ON" 2 "failure" 3 "Reserved" ;
VAL_ 821 ADS_5_ISLISpeedLimitSign 0 "No display" 1 "Cancellation sign" 2 "5" 3 "10" 4 "15" 5 "20" 6 "25" 7 "30" 8 "35" 9 "40" 10 "45" 11 "50" 12 "55" 13 "60" 14 "65" 15 "70" 16 "75" 17 "80" 18 "85" 19 "90" 20 "95" 21 "100" 22 "105" 23 "110" 24 "115" 25 "120" 26 "125" 27 "130" 28 "135" 29 "140" 30 "145" 31 "150" 32 "155" 33 "160" 34 "165" 35 "170" 36 "175" 37 "180" 38 "185" 39 "190" 40 "195" 41 "200" 42 "Reserved" 43 "Reserved" 44 "Reserved" 45 "Reserved" 46 "Reserved" 47 "Reserved" 48 "Reserved" 49 "Reserved" 50 "Reserved" 51 "Reserved" 52 "Reserved" 53 "Reserved" 54 "Reserved" 55 "Reserved" 56 "Reserved" 57 "Reserved" 58 "Reserved" 59 "Reserved" 60 "Reserved" 61 "Reserved" 62 "Reserved" 63 "Reserved" 64 "Reserved" 65 "Reserved" 66 "Reserved" 67 "Reserved" 68 "Reserved" 69 "Reserved" 70 "Reserved" 71 "Reserved" 72 "Reserved" 73 "Reserved" 74 "Reserved" 75 "Reserved" 76 "Reserved" 77 "Reserved" 78 "Reserved" 79 "Reserved" 80 "Reserved" 81 "Reserved" 82 "Reserved" 83 "Reserved" 84 "Reserved" 85 "Reserved" 86 "Reserved" 87 "Reserved" 88 "Reserved" 89 "Reserved" 90 "Reserved" 91 "Reserved" 92 "Reserved" 93 "Reserved" 94 "Reserved" 95 "Reserved" 96 "Reserved" 97 "Reserved" 98 "Reserved" 99 "Reserved" 100 "Reserved" 101 "Reserved" 102 "Reserved" 103 "Reserved" 104 "Reserved" 105 "Reserved" 106 "Reserved" 107 "Reserved" 108 "Reserved" 109 "Reserved" 110 "Reserved" 111 "Reserved" 112 "Reserved" 113 "Reserved" 114 "Reserved" 115 "Reserved" 116 "Reserved" 117 "Reserved" 118 "Reserved" 119 "Reserved" 120 "Reserved" 121 "Reserved" 122 "Reserved" 123 "Reserved" 124 "Reserved" 125 "Reserved" 126 "Reserved" 127 "Reserved" 128 "Reserved" 129 "Reserved" 130 "Reserved" 131 "Reserved" 132 "Reserved" 133 "Reserved" 134 "Reserved" 135 "Reserved" 136 "Reserved" 137 "Reserved" 138 "Reserved" 139 "Reserved" 140 "Reserved" 141 "Reserved" 142 "Reserved" 143 "Reserved" 144 "Reserved" 145 "Reserved" 146 "Reserved" 147 "Reserved" 148 "Reserved" 149 "Reserved" 150 "Reserved" 151 "Reserved" 152 "Reserved" 153 "Reserved" 154 "Reserved" 155 "Reserved" 156 "Reserved" 157 "Reserved" 158 "Reserved" 159 "Reserved" 160 "Reserved" 161 "Reserved" 162 "Reserved" 163 "Reserved" 164 "Reserved" 165 "Reserved" 166 "Reserved" 167 "Reserved" 168 "Reserved" 169 "Reserved" 170 "Reserved" 171 "Reserved" 172 "Reserved" 173 "Reserved" 174 "Reserved" 175 "Reserved" 176 "Reserved" 177 "Reserved" 178 "Reserved" 179 "Reserved" 180 "Reserved" 181 "Reserved" 182 "Reserved" 183 "Reserved" 184 "Reserved" 185 "Reserved" 186 "Reserved" 187 "Reserved" 188 "Reserved" 189 "Reserved" 190 "Reserved" 191 "Reserved" 192 "Reserved" 193 "Reserved" 194 "Reserved" 195 "Reserved" 196 "Reserved" 197 "Reserved" 198 "Reserved" 199 "Reserved" 200 "Reserved" 201 "Reserved" 202 "Reserved" 203 "Reserved" 204 "Reserved" 205 "Reserved" 206 "Reserved" 207 "Reserved" 208 "Reserved" 209 "Reserved" 210 "Reserved" 211 "Reserved" 212 "Reserved" 213 "Reserved" 214 "Reserved" 215 "Reserved" 216 "Reserved" 217 "Reserved" 218 "Reserved" 219 "Reserved" 220 "Reserved" 221 "Reserved" 222 "Reserved" 223 "Reserved" 224 "Reserved" 225 "Reserved" 226 "Reserved" 227 "Reserved" 228 "Reserved" 229 "Reserved" 230 "Reserved" 231 "Reserved" 232 "Reserved" 233 "Reserved" 234 "Reserved" 235 "Reserved" 236 "Reserved" 237 "Reserved" 238 "Reserved" 239 "Reserved" 240 "Reserved" 241 "Reserved" 242 "Reserved" 243 "Reserved" 244 "Reserved" 245 "Reserved" 246 "Reserved" 247 "Reserved" 248 "Reserved" 249 "Reserved" 250 "Reserved" 251 "Reserved" 252 "Reserved" 253 "Reserved" 254 "Reserved" 255 "Reserved" ;
VAL_ 821 ADS_5_ILOATextInfo 0 "None" 1 "Evading oversized vehicle" 2 "Avoiding obstacles" 3 "Reserved" ;
VAL_ 821 ADS_5_ILOAActdirection 0 "Not active" 1 "Left" 2 "Right" 3 "Reserved" ;
VAL_ 821 ADS_5_LKS_warning 0 "no warning" 1 "warning" ;
VAL_ 821 ADS_5_EgoLeftLineHeatgAg 511 "Invalid" ;
VAL_ 821 ADS_5_ISLIOverSpeedWarn 0 "No warning" 1 "Waning1" 2 "Waning2" 3 "Waning3" ;
VAL_ 821 ADS_5_EgoLeLineHozlDst 511 "Invalid" ;
VAL_ 821 ADS_5_EgoLeLineID 0 "Invalid" 1 "Valid" ;
VAL_ 821 ADS_5_EgoLeLineColor 0 "No display" 1 "Color_Unknown" 2 "Color_White" 3 "Color_Yellow" ;
VAL_ 821 ADS_5_EgoLeLineTyp 0 "No display" 1 "Type_Unknown" 2 "Type_Solid_Line" 3 "Type_Dashed_Line" ;
VAL_ 821 ADS_5_EgoLeLineCrvt 1023 "Invalid" ;
VAL_ 821 ADS_5_NeborLeLineHozlDst 511 "Invalid" ;
VAL_ 821 ADS_5_NeborLeLineID 0 "Invalid" 1 "Valid" ;
VAL_ 821 ADS_5_NeborLeLineColor 0 "No display" 1 "Color_Unknown" 2 "Color_White" 3 "Color_Yellow" ;
VAL_ 821 ADS_5_NeborLeLineTyp 0 "No display" 1 "Type_Unknown" 2 "Type_Solid_Line" 3 "Type_Dashed_Line" ;
VAL_ 821 ADS_5_NeborLeLineCrvt 1023 "Invalid" ;
VAL_ 821 ADS_5_NeborRiLineHozlDst 511 "Invalid" ;
VAL_ 821 ADS_5_NeborRiLineID 0 "Invalid" 1 "Valid" ;
VAL_ 821 ADS_5_NeborRiLineColor 0 "No display" 1 "Color_Unknown" 2 "Color_White" 3 "Color_Yellow" ;
VAL_ 821 ADS_5_NeborRiLineTyp 0 "No display" 1 "Type_Unknown" 2 "Type_Solid_Line" 3 "Type_Dashed_Line" ;
VAL_ 821 ADS_5_NeborRiLineCrvt 1023 "Invalid" ;
VAL_ 821 ADS_5_ELKSettingSt 0 "None" 1 "On" 2 "Off" 3 "reserved" ;
VAL_ 821 ADS_5_LDWLDPSnvtySet 0 "None" 1 "high" 2 "low" 3 "reserved" ;
VAL_ 821 ADS_5_LDWWarnType 0 "None" 1 "warning only" 2 "vibration  only" 3 "warning and vibration" ;
VAL_ 821 ADS_5_IESSwtSet 0 "None" 1 "ON" 2 "Off" 3 "reserved" ;
VAL_ 821 ADS_5_IHCSettingSt 0 "None" 1 "ON" 2 "OFF" 3 "reserved" ;
VAL_ 821 ADS_5_ISLIWarningMod 0 "None" 1 "Display warning;" 2 "Sound+display warning" 3 "Off" ;
VAL_ 821 ADS_5_ICAEnableBtnSts 0 "None" 1 "ON" 2 "Off" 3 "reserved" ;
VAL_ 821 ADS_5_EgoRiLineTyp 0 "No display" 1 "Type_Unknown" 2 "Type_Solid_Line" 3 "Type_Dashed_Line" ;
VAL_ 821 ADS_5_FCM_Camera_textinfo 0 "Camera normal" 1 "Camera failure" 2 "Camera blocked" 3 "Camera high temperature" ;
VAL_ 821 ADS_5_EgoRiLineColor 0 "No display" 1 "Color_Unknown" 2 "Color_White" 3 "Color_Yellow" ;
VAL_ 821 ADS_5_EgoRiLineID 0 "Invalid" 1 "Valid" ;
VAL_ 850 ASU_6_HMIFailFb_JT 0 "Not Active" 1 "SUSP IS lock" 2 "PLG is open" 3 "suspension height disable" 4 "suspension damping disable" 5 "Altitude too high" 6 "Pump_worked_out" 7 "The_pump_is_working_abnormally" 8 "Off-road_trekking_not_active" 9 "Off-road_trekking_out" 10 "Inflate_not_active" 11 "Undergroundmode_not_active" 12 "Undergroundmode_out" ;
VAL_ 859 RearDefrostSts 0 "OFF" 1 "ON" ;
VAL_ 917 ADBenable 0 "Notactive" 1 "enable" 2 "disenable" 3 "Reserved" ;
VAL_ 917 RandomMusicShowCMD 0 "Not active" 1 "Active" 2 "Reserved" 3 "Reserved" ;
VAL_ 917 DIYMusicShowmod 0 "Not active" 1 "waiting" 2 "mode1" 3 "mode2" ;
VAL_ 917 MusicLoudness_55HZ 0 "Level 1" 1 "Level 2" 2 "Level 3" 3 "Level 4" 4 "Level 5" 5 "Level 6" 6 "Level 7" 7 "Level 8" 8 "Level 9" 9 "Level 10" 10 "Level 11" 11 "Level 12" 12 "Level 13" 13 "Level 14" 14 "Level 15" 15 "Level 16" 16 "Reserved" 17 "Reserved" 18 "Reserved" 19 "Reserved" 20 "Reserved" 21 "Reserved" 22 "Reserved" 23 "Reserved" 24 "Reserved" 25 "Reserved" 26 "Reserved" 27 "Reserved" 28 "Reserved" 29 "Reserved" 30 "Reserved" 31 "Invalid" ;
VAL_ 917 LiShowMod 0 "NotActive" 1 "OFF" 2 "Mode1" 3 "Mode2" 4 "Mode3" 5 "Mode4(Reserved)" 6 "Mode5(Reserved)" ;
VAL_ 917 MusicLoudness_262HZ 0 "Level 1" 1 "Level 2" 2 "Level 3" 3 "Level 4" 4 "Level 5" 5 "Level 6" 6 "Level 7" 7 "Level 8" 8 "Level 9" 9 "Level 10" 10 "Level 11" 11 "Level 12" 12 "Level 13" 13 "Level 14" 14 "Level 15" 15 "Level 16" 16 "Reserved" 17 "Reserved" 18 "Reserved" 19 "Reserved" 20 "Reserved" 21 "Reserved" 22 "Reserved" 23 "Reserved" 24 "Reserved" 25 "Reserved" 26 "Reserved" 27 "Reserved" 28 "Reserved" 29 "Reserved" 30 "Reserved" 31 "Invalid" ;
VAL_ 917 MusicLoudness_123HZ 0 "Level 1" 1 "Level 2" 2 "Level 3" 3 "Level 4" 4 "Level 5" 5 "Level 6" 6 "Level 7" 7 "Level 8" 8 "Level 9" 9 "Level 10" 10 "Level 11" 11 "Level 12" 12 "Level 13" 13 "Level 14" 14 "Level 15" 15 "Level 16" 16 "Reserved" 17 "Reserved" 18 "Reserved" 19 "Reserved" 20 "Reserved" 21 "Reserved" 22 "Reserved" 23 "Reserved" 24 "Reserved" 25 "Reserved" 26 "Reserved" 27 "Reserved" 28 "Reserved" 29 "Reserved" 30 "Reserved" 31 "Invalid" ;
VAL_ 917 MusicLoudness_587HZ 0 "Level 1" 1 "Level 2" 2 "Level 3" 3 "Level 4" 4 "Level 5" 5 "Level 6" 6 "Level 7" 7 "Level 8" 8 "Level 9" 9 "Level 10" 10 "Level 11" 11 "Level 12" 12 "Level 13" 13 "Level 14" 14 "Level 15" 15 "Level 16" 16 "Reserved" 17 "Reserved" 18 "Reserved" 19 "Reserved" 20 "Reserved" 21 "Reserved" 22 "Reserved" 23 "Reserved" 24 "Reserved" 25 "Reserved" 26 "Reserved" 27 "Reserved" 28 "Reserved" 29 "Reserved" 30 "Reserved" 31 "Invalid" ;
VAL_ 917 MusicLoudness_440HZ 0 "Level 1" 1 "Level 2" 2 "Level 3" 3 "Level 4" 4 "Level 5" 5 "Level 6" 6 "Level 7" 7 "Level 8" 8 "Level 9" 9 "Level 10" 10 "Level 11" 11 "Level 12" 12 "Level 13" 13 "Level 14" 14 "Level 15" 15 "Level 16" 16 "Reserved" 17 "Reserved" 18 "Reserved" 19 "Reserved" 20 "Reserved" 21 "Reserved" 22 "Reserved" 23 "Reserved" 24 "Reserved" 25 "Reserved" 26 "Reserved" 27 "Reserved" 28 "Reserved" 29 "Reserved" 30 "Reserved" 31 "Invalid" ;
VAL_ 917 MusicLoudness_784HZ 0 "Level 1" 1 "Level 2" 2 "Level 3" 3 "Level 4" 4 "Level 5" 5 "Level 6" 6 "Level 7" 7 "Level 8" 8 "Level 9" 9 "Level 10" 10 "Level 11" 11 "Level 12" 12 "Level 13" 13 "Level 14" 14 "Level 15" 15 "Level 16" 16 "Reserved" 17 "Reserved" 18 "Reserved" 19 "Reserved" 20 "Reserved" 21 "Reserved" 22 "Reserved" 23 "Reserved" 24 "Reserved" 25 "Reserved" 26 "Reserved" 27 "Reserved" 28 "Reserved" 29 "Reserved" 30 "Reserved" 31 "Invalid" ;
VAL_ 917 MusicLoudness_2794HZ 0 "Level 1" 1 "Level 2" 2 "Level 3" 3 "Level 4" 4 "Level 5" 5 "Level 6" 6 "Level 7" 7 "Level 8" 8 "Level 9" 9 "Level 10" 10 "Level 11" 11 "Level 12" 12 "Level 13" 13 "Level 14" 14 "Level 15" 15 "Level 16" 16 "Reserved" 17 "Reserved" 18 "Reserved" 19 "Reserved" 20 "Reserved" 21 "Reserved" 22 "Reserved" 23 "Reserved" 24 "Reserved" 25 "Reserved" 26 "Reserved" 27 "Reserved" 28 "Reserved" 29 "Reserved" 30 "Reserved" 31 "Invalid" ;
VAL_ 917 MusicLoudness_1318HZ 0 "Level 1" 1 "Level 2" 2 "Level 3" 3 "Level 4" 4 "Level 5" 5 "Level 6" 6 "Level 7" 7 "Level 8" 8 "Level 9" 9 "Level 10" 10 "Level 11" 11 "Level 12" 12 "Level 13" 13 "Level 14" 14 "Level 15" 15 "Level 16" 16 "Reserved" 17 "Reserved" 18 "Reserved" 19 "Reserved" 20 "Reserved" 21 "Reserved" 22 "Reserved" 23 "Reserved" 24 "Reserved" 25 "Reserved" 26 "Reserved" 27 "Reserved" 28 "Reserved" 29 "Reserved" 30 "Reserved" 31 "Invalid" ;
VAL_ 917 MusicLoudness_6272HZ 0 "Level 1" 1 "Level 2" 2 "Level 3" 3 "Level 4" 4 "Level 5" 5 "Level 6" 6 "Level 7" 7 "Level 8" 8 "Level 9" 9 "Level 10" 10 "Level 11" 11 "Level 12" 12 "Level 13" 13 "Level 14" 14 "Level 15" 15 "Level 16" 16 "Reserved" 17 "Reserved" 18 "Reserved" 19 "Reserved" 20 "Reserved" 21 "Reserved" 22 "Reserved" 23 "Reserved" 24 "Reserved" 25 "Reserved" 26 "Reserved" 27 "Reserved" 28 "Reserved" 29 "Reserved" 30 "Reserved" 31 "Invalid" ;
VAL_ 917 ISDShowCMD 0 "OFF" 1 "ON" ;
VAL_ 917 ISDShowMode 0 "Default value" 1 "BatteryCharging" 2 "Brand" 3 "TiresPressures" 4 "Weather" 5 "Greetings" 6 "Package" 7 "Panda" 8 "PredestrianCrossing" 9 "PingPong" 10 "Kite" 11 "Coffee" 12 "Reserved" 13 "Reserved" 14 "Reserved" 15 "Reserved" ;
VAL_ 943 OverLoadWarnShieldSetFed 0 "Not Active" 1 "ON" 2 "OFF" 3 "Fault" ;
VAL_ 943 OverWeightWarning 0 "No warning" 1 "Warning" ;
VAL_ 943 OverWeightRatio 0 "未超载" 1 "超载0-10%" 2 "超载10%~20%" 3 "超载20%~30%" 4 "超载30%`40%" 5 "严重超载" ;
VAL_ 943 Fraxlebearingrate 254 "Abnormal" 255 "Invalid" ;
VAL_ 949 PEPS_OrderInformation 0 "OFF" 1 "Lock" 2 "Unlock" 4 "Trunk" 5 "Welcome_On" 6 "Welcome_Off" 7 "RKE_Search_Car" 8 "Power_Slide_Door_Left" ;
VAL_ 949 PEPS_InformationSource 0 "Not_Active" 1 "Smart_Information" 2 "RKE_Information" 3 "Near_Access" ;
VAL_ 949 PEPS_KeySts 0 "Not_Active" 1 "PEPS_Key_In" 2 "PEPS_Key_Near_Flant" 3 "PEPS_Key_Near_Frant" 4 "PEPS_Key_Near_Trunkant" 5 "Unknow" ;
VAL_ 949 PEPS_IDInformation 0 "Not_Active" 1 "Transmitter_1" 2 "Transmitter_2" 3 "Transmitter_3" 4 "Transmitter_4" 5 "Transmitter_BLT1" 6 "Transmitter_BLT2" 7 "Transmitter_BLT3" 8 "Transmitter_NFC1" 9 "Transmitter_NFC2" 10 "Transmitter_NFC3" ;
VAL_ 949 PEPS_ETRUnLockReq 0 "Not_Request" 1 "Request" ;
VAL_ 991 TMS_BatteryLoopErrorLevel 0 "No_Error" 1 "Derating_function" 2 "Disabler" 3 "ShutDown" 4 "Reserved" 5 "Reserved" 6 "Reserved" 7 "Reserved" ;
VAL_ 991 TMS_MotorLoopErrorLevel 0 "No_Error" 1 "Derating_function" 2 "Disabler" 3 "ShutDown" 4 "Reserved" 5 "Reserved" 6 "Reserved" 7 "Reserved" ;
VAL_ 1018 FLZCU_DraggingModeRemind_3FAh 0 "Not_Active" 1 "Enter" 2 "Working" 3 "Exit" 4 "Reserved" 5 "Reserved" 6 "Reserved" 7 "Reserved" ;
VAL_ 1018 FLZCU_KeyDriveModememory_3FAh 0 "Not_Active" 1 "Remember" 2 "No_Remember" ;
VAL_ 1018 FLZCU_DriveMode_3FAh 0 "Not Active" 1 "ECO" 2 "Normal" 3 "Sport" 4 "Snow" 5 "Off Road" 6 "Individual" 7 "Energy-saving hybrid" 8 "Sand" 9 "AI" 10 "Wade" 11 "Rock" 12 "Mud" 13 "Xmode" ;
VAL_ 1018 FLZCU_CCO_TextDisp_3FAh 0 "No_Warn" 1 "Please_Release_EPB" 2 "Please_Slow_Down" 3 "Please_Close_Door" 4 "Please_Open in D/N" 5 "Please_Close_APA/ACC/CC" 6 "Please_Exit_HDC" 7 "Please_Switch to Mud/Sand/Rock/Snow" 8 "Reduce_Speed_Below 12kph" 9 "Please_Close_CCO" ;
VAL_ 1018 FLZCU_CCOSwtReq_3FAh 0 "Not_Active" 1 "ON" 2 "OFF" 3 "Reserved" ;
VAL_ 1018 FLZCU_DriveModeChangeFail_3FAh 0 "NOT FAIL" 1 "FAIL" 2 "EngySavMod_Fail" 3 "Reserved" ;
VAL_ 1020 BMSH_MaxChgPwrPeak 4095 "Invalid" ;
VAL_ 1020 BMSH_MaxDchgPwrPeak 4095 "Invalid" ;
VAL_ 1020 FMCU_8_ISGF_SpdAct 65535 "Invalid" ;
VAL_ 1020 RMCU_1_Speed 65535 "Invalid" ;
VAL_ 1020 SAM_1_SteeringAngleVD 0 "Valid" 1 "Not Valid" ;
VAL_ 1020 SAM_1_SteeringAngleSpeedVD 0 "Valid" 1 "Not Valid" ;
VAL_ 1020 CSA_2_AllWarningInfo 0 "No error" 1 "First grade failure of gear shift mechanism" 2 "Second grade failure of gear shift mechanism" 3 "Third grade failure of gear shift mechanism(Reserved)" 4 "Please check the position of the gear shift" 5 "Reserved" 6 "Reserved" 7 "Reserved" ;
VAL_ 1020 RMCU_1_TCURErrLvlDis 0 "No Error" 1 "Err_Level1" 2 "Err_Level2" 3 "Err_Level3" 4 "Err_Level4" ;
VAL_ 1020 ASU_2_sensorErrorSts 0 "all four sensors no fault" 1 "RR sensor faulty" 2 "LR sensor faulty" 3 "RR and LR sensors faulty" 4 "RF sensor faulty" 5 "RF and RR sensor fault" 6 "RF and LR sensors  faulty" 7 "RF LR and RR sensors  faulty" 8 "LF sensor fault" 9 "LF and RR sensor fault" 10 "LF and LR sensor fault" 11 "LF LR and RR sensors are faulty" 12 "LF and RF sensor fault" 13 "LF RF and RR sensors are faulty" 14 "LF RF and LR sensors are faulty" 15 "four sensors are faulty" ;
VAL_ 1020 ASU_2_LFHeight 4095 "Invalid" ;
VAL_ 1020 ASU_2_RFHeight 4095 "Invalid" ;
VAL_ 1020 ASU_2_LRHeight 4095 "Invalid" ;
VAL_ 1020 ASU_2_RRHeight 4095 "Invalid" ;
VAL_ 1020 CSA_2_WiprFrntCmd 0 "OFF" 1 "AUTO" 2 "LOW" 3 "HIGH" ;
VAL_ 1020 EVCC_GunConnectSt_203h 0 "Disconnect" 1 "Connect" 2 "The connection is abnormal." 3 "Invalid" ;
VAL_ 1020 STAT_ShifterLeverFault 0 "Shift sensors both ok" 1 "Shift sensor 1 fault" 2 "Shift sensor 2 fault" 3 "Shift sensors both fault" 4 "Reserve" 5 "Reserve" 6 "Reserve" 7 "Invalid" ;
VAL_ 1022 FLZCU_MedStatusFb 0 "Not Active" 1 "ON" 2 "OFF" ;
VAL_ 1022 FLZCU_SteerWhlposSts 0 "Not Active" 1 "Elongation regulation" 2 "Shortening in regulation" 3 "Angle elevation" 4 "Angle centering" ;
VAL_ 1022 FLZCU_CarMode 0 "Normal Mode" 1 "Factory Mode" 2 "Transport Mode" 3 "Exhibition Mode" 4 "Reserved" 5 "Reserved" 6 "Reserved" 7 "Not active" ;
VAL_ 1022 FLZCU_MedAreaFb 0 "Not Active" 1 "Front Left" 2 "Front Right" 3 "Front Left and Right" 4 "2Row Left" 5 "2Row Right" 6 "2Row Left and 2Row Right" 7 "Front Left and 2Row Right" 8 "Front Right and 2Row Left" 9 "Front Left and 2Row Left" 10 "Front Right and 2Row Right" ;
VAL_ 1022 FLZCU_MedFailCause 0 "Not Active" 1 "Gear Not P" 2 "Vehicle Speed#0km/h" 3 "Hood Unlock" 4 "Trunk Unlock" 5 "FLDoor Unlock" 6 "FRDoor Unlock" 7 "RLDoor Unlock" 8 "RRDoor Unlock" 9 "Low Voltage Battery Voltage Low" 10 "High Voltage Battery Low" 11 "Brake Pedal Depressed" 12 "PowerMode Not Comfortable" ;
VAL_ 1022 FLZCU_NapArea2Fb 0 "Not Active" 1 "2Row Left" 2 "2Row Right" 3 "2Row Left and Right" 4 "Front Left and 2Row Right" 5 "Front Right and 2Row Left" 6 "Front Left and 2Row Left" 7 "Front Right and 2Row Right" ;
VAL_ 1022 FLZCU_MedClosePrompt 0 "Not Active" 1 "Low Voltage Battery Low" 2 "High Voltage Battery Low" ;
VAL_ 1022 FLZCU_LogoChargingSts 0 "Not Active" 1 "ON" 2 "OFF" 3 "Reserved" ;
VAL_ 1022 FLZCU_MonoAmbLigSts 0 "OFF" 1 "ON" ;
VAL_ 1022 DrvRearWinThermalStatus_3FEh 0 "Normal" 1 "Thermal protection" ;
VAL_ 1022 DrvWinThermalStatus_3FEh 0 "Normal" 1 "Thermal protection" ;
VAL_ 1022 DrvSitPosnSts_3FEh 0 "Not Active" 1 "Location1" 2 "Location2" 3 "Location3" 4 "FaceID" ;
VAL_ 1022 DrvRearSeatVentLvl2_3FEh 0 "Not Active" 1 "OFF" 2 "Level1" 3 "Level2" 4 "Level3" 5 "Level4" 6 "Level5" 7 "Level6" 8 "Level7" 9 "Level8" 10 "Level9" ;
VAL_ 1022 DrvSeatVentLvl2_3FEh 0 "Not Active" 1 "OFF" 2 "Level1" 3 "Level2" 4 "Level3" 5 "Level4" 6 "Level5" 7 "Level6" 8 "Level7" 9 "Level8" 10 "Level9" ;
VAL_ 1022 DrvRearSeatHeatLvl2_3FEh 0 "Not Active" 1 "OFF" 2 "Level1" 3 "Level2" 4 "Level3" 5 "Level4" 6 "Level5" 7 "Level6" 8 "Level7" 9 "Level8" 10 "Level9" ;
VAL_ 1022 DrvSeatHeatLvl2_3FEh 0 "Not Active" 1 "OFF" 2 "Level1" 3 "Level2" 4 "Level3" 5 "Level4" 6 "Level5" 7 "Level6" 8 "Level7" 9 "Level8" 10 "Level9" ;
VAL_ 1022 FLZCU_DrvExpSeatSts_3FEh 0 "Not active" 1 "Expand completed" 2 "Reset completed" 3 "Stop" ;
VAL_ 1022 FLZCU_FLogolightInhibitSts 0 "Permit" 1 "Inhibit" ;
VAL_ 1022 FLZCU_SteerOverHeatWarn 0 "Not Active" 1 "Active" ;
VAL_ 1024 CSunshadePercentSts 0 "Not Active" 1 "0%" 2 "10%" 3 "20%" 4 "30%" 5 "40%" 6 "50%" 7 "60%" 8 "70%" 9 "80%" 10 "90%" 11 "100%" ;
VAL_ 1024 CSunshadeSts 0 "Not Active" 1 "Open" 2 "Close" 3 "Half_Open" 4 "Opening" 5 "Closing" 6 "Stop" 7 "Error" ;
VAL_ 1024 PassSeatVentLvl2_400h 0 "Not Active" 1 "OFF" 2 "Level1" 3 "Level2" 4 "Level3" 5 "Level4" 6 "Level5" 7 "Level6" 8 "Level7" 9 "Level8" 10 "Level9" ;
VAL_ 1024 PassSeatHeatLvl2_400h 0 "Not Active" 1 "OFF" 2 "Level1" 3 "Level2" 4 "Level3" 5 "Level4" 6 "Level5" 7 "Level6" 8 "Level7" 9 "Level8" 10 "Level9" ;
VAL_ 1024 PassSecSeatHeatLvl2_400h 0 "Not Active" 1 "OFF" 2 "Level1" 3 "Level2" 4 "Level3" 5 "Level4" 6 "Level5" 7 "Level6" 8 "Level7" 9 "Level8" 10 "Level9" ;
VAL_ 1024 PassSecSeatVentLvl2_400h 0 "Not Active" 1 "OFF" 2 "Level1" 3 "Level2" 4 "Level3" 5 "Level4" 6 "Level5" 7 "Level6" 8 "Level7" 9 "Level8" 10 "Level9" ;
VAL_ 1024 FRZCU_OnekeyHVoffSwtst 0 "Not Pressed" 1 "Pressed" 2 "Stuck" 3 "Not Used" ;
VAL_ 1024 FRZCU_CSunshadeThermalSts 0 "Normal" 1 "Thermal protection" ;
VAL_ 1024 PassRearWinThermalSts_400h 0 "Normal" 1 "Thermal protection" ;
VAL_ 1024 PassWinThermalSts_400h 0 "Normal" 1 "Thermal protection" ;
VAL_ 1024 FRZCU_ContainerlightSts 0 "Not Active" 1 "ON" 2 "OFF" 3 "reserved" ;
VAL_ 1024 FRZCU_ADSLightSts 0 "OFF" 1 "ON" 2 "Reserved" 3 "Reserved" ;
VAL_ 1024 FRZCU_QueenSeatEnterSts 0 "Not Active" 1 "Running" 2 "Running Success" 3 "Running Fail" ;
VAL_ 1024 FRZCU_PasgerSeatMovFailCause 0 "Not active" 1 "Not Learned" 2 "Antipinch event" 3 "Hard Switch Not Released" 4 "Fold_Sts" 5 "Motor Circuit Failure" 6 "Low Priority" ;
VAL_ 1024 FRZCU_ADSLightFltSts 0 "No Error" 1 "Error" 2 "Reserved" 3 "Reserved" ;
VAL_ 1024 FRZCU_QueenSeatPosSts 0 "Not at QueenSeatPos" 1 "QueenSeatPos" ;
VAL_ 1024 FRZCU_QueenSeatSts 0 "Not Active" 1 "Exited" 2 "Entered" ;
VAL_ 1024 FRZCU_QueenSeatMovFailCause 0 "Not active" 1 "Not Learned" 2 "Antipinch event" 3 "Hard Switch Not Released" 4 "Fold_Sts" 5 "Motor Circuit Failure" 6 "Low Priority" 7 "RRSeatExpSts" 8 "RRSeat Occupied" 9 "RRSeatStop" ;
VAL_ 1024 CSunshadeLearnedSts 0 "Not Active" 1 "Learned" 2 "Not Learned" 3 "Learning" ;
SIG_GROUP_ 514 E2EP01_Signal_Group_202 1 : ADS_TORIDCorrespErrorID_202h ADS_TakeoverLevel_202h ADS_TakeoverType_202h ADS_TakeoverID_202h ADS_AdsFault_202h ADS_NicaReminderLEDVisual_202h ADS_NicaReminderAcoustic_202h ADS_Resd1_202h ADS_RollgCntr1_202h ADS_CRC1_202h;
SIG_GROUP_ 612 E2EP01_Signal_Group_264 1 : IPB_EPBErrorStatus TextDisp_264h RWUSt_264h ActrSt_264h ParkLamp_264h FltLamp_264h EPBAUTO_Status_264h RollgCntr1_264h CRC1_264h New_Signal_264_1 New_Signal_264_2 New_Signal_264_3 New_Signal_264_4 New_Signal_264_5;
